VERSION "BASE;119 -- 04.07.2025 -- R3233 -- FDMgenDBC1.0"

NS_ :

BS_:

BU_: CM4

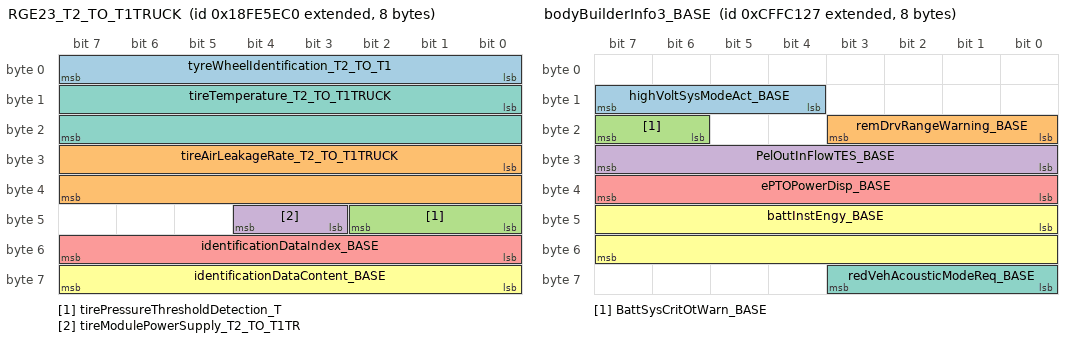
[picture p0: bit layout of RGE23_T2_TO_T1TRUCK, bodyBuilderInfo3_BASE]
BO_ 2566807232 RGE23_T2_TO_T1TRUCK: 8 Vector__XXX
 SG_ tyreWheelIdentification_T2_TO_T1 : 0|8@1+ (1,0) [0|0] "-" CM4
 SG_ tireAirLeakageRate_T2_TO_T1TRUCK : 24|16@1+ (0.1,0) [0|6425.5] "Pa/s" CM4
 SG_ tirePressureThresholdDetection_T : 40|3@1+ (1,0) [0|0] "-" CM4
 SG_ tireModulePowerSupply_T2_TO_T1TR : 43|2@1+ (1,0) [0|0] "-" CM4
 SG_ identificationDataIndex_BASE : 48|8@1+ (1,0) [0|250] "-" CM4
 SG_ identificationDataContent_BASE : 56|8@1+ (1,0) [0|250] "-" CM4
 SG_ tireTemperature_T2_TO_T1TRUCK : 8|16@1+ (0.03125,-273) [-273|1735] "°C" CM4

BO_ 2365571367 bodyBuilderInfo3_BASE: 8 Vector__XXX
 SG_ highVoltSysModeAct_BASE : 12|4@1+ (1,0) [0|0] "-" CM4
 SG_ remDrvRangeWarning_BASE : 16|4@1+ (1,0) [0|0] "-" CM4
 SG_ BattSysCritOtWarn_BASE : 22|2@1+ (1,0) [0|0] "-" CM4
 SG_ PelOutInFlowTES_BASE : 24|8@1+ (5,-625) [-625|625] "kW" CM4
 SG_ ePTOPowerDisp_BASE : 32|8@1+ (0.5,0) [0|120] "%" CM4
 SG_ battInstEngy_BASE : 40|16@1+ (0.01,-321.27) [-321.27|321.28] "kWh/km" CM4
 SG_ redVehAcousticModeReq_BASE : 56|4@1+ (1,0) [0|0] "-" CM4

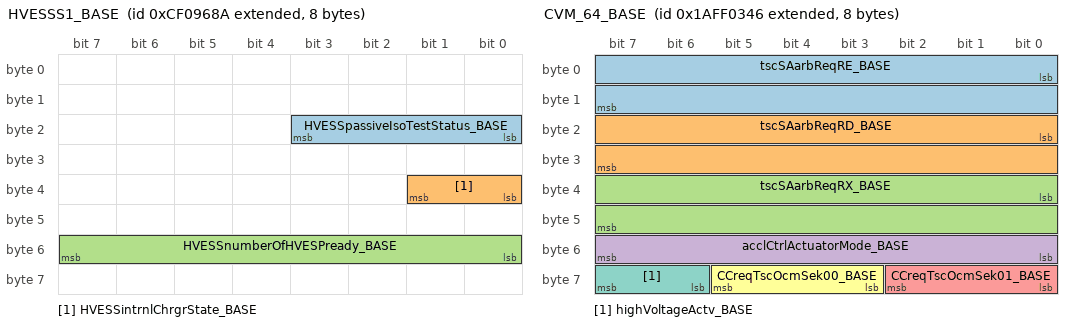
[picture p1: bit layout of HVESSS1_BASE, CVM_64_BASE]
BO_ 2364577418 HVESSS1_BASE: 8 Vector__XXX
 SG_ HVESSpassiveIsoTestStatus_BASE : 16|4@1+ (1,0) [0|0] "-" CM4
 SG_ HVESSintrnlChrgrState_BASE : 32|2@1+ (1,0) [0|0] "-" CM4
 SG_ HVESSnumberOfHVESPready_BASE : 48|8@1+ (1,0) [0|250] "count" CM4

BO_ 2600403782 CVM_64_BASE: 8 Vector__XXX
 SG_ tscSAarbReqRE_BASE : 0|16@1+ (1,0) [0|65535] "-" CM4
 SG_ tscSAarbReqRD_BASE : 16|16@1+ (1,0) [0|65535] "-" CM4
 SG_ tscSAarbReqRX_BASE : 32|16@1+ (1,0) [0|65535] "-" CM4
 SG_ acclCtrlActuatorMode_BASE : 48|8@1+ (1,0) [0|0] "-" CM4
 SG_ CCreqTscOcmSek01_BASE : 56|3@1+ (1,0) [0|0] "-" CM4
 SG_ CCreqTscOcmSek00_BASE : 59|3@1+ (1,0) [0|0] "-" CM4
 SG_ highVoltageActv_BASE : 62|2@1+ (1,0) [0|0] "-" CM4

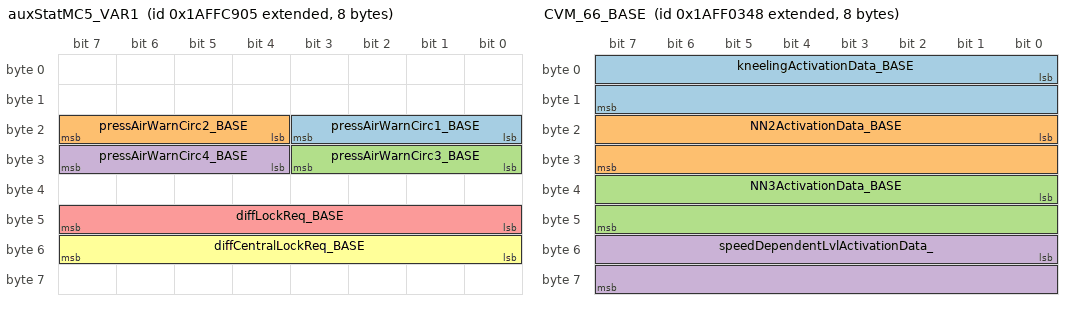
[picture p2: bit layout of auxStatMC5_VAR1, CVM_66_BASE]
BO_ 2600454405 auxStatMC5_VAR1: 8 Vector__XXX
 SG_ pressAirWarnCirc1_BASE : 16|4@1+ (1,0) [0|0] "-" CM4
 SG_ pressAirWarnCirc2_BASE : 20|4@1+ (1,0) [0|0] "-" CM4
 SG_ pressAirWarnCirc3_BASE : 24|4@1+ (1,0) [0|0] "-" CM4
 SG_ pressAirWarnCirc4_BASE : 28|4@1+ (1,0) [0|0] "-" CM4
 SG_ diffLockReq_BASE : 40|8@1+ (1,0) [0|0] "-" CM4
 SG_ diffCentralLockReq_BASE : 48|8@1+ (1,0) [0|0] "-" CM4

BO_ 2566842927 vehicleWeight_VAR2: 8 Vector__XXX
 SG_ axleLocation_VEHWE_VAR2_SSC1 : 0|8@1+ (1,0) [0|255] "-" CM4
 SG_ axleWeight_VEHWE_VAR2_SSC1 : 8|16@1+ (0.5,0) [0|32127.5] "kg" CM4

BO_ 2600403784 CVM_66_BASE: 8 Vector__XXX
 SG_ kneelingActivationData_BASE : 0|16@1+ (1,0) [0|64255] "-" CM4
 SG_ NN2ActivationData_BASE : 16|16@1+ (1,0) [0|64255] "km" CM4
 SG_ NN3ActivationData_BASE : 32|16@1+ (1,0) [0|64255] "km" CM4
 SG_ speedDependentLvlActivationData_ : 48|16@1+ (1,0) [0|64255] "km" CM4

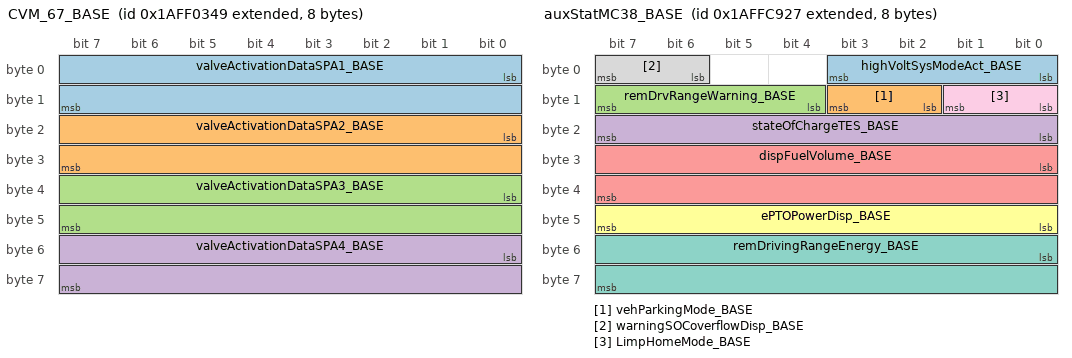
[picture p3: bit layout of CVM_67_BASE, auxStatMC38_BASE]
BO_ 2600403785 CVM_67_BASE: 8 Vector__XXX
 SG_ valveActivationDataSPA1_BASE : 0|16@1+ (1,0) [0|64255] "-" CM4
 SG_ valveActivationDataSPA2_BASE : 16|16@1+ (1,0) [0|64255] "-" CM4
 SG_ valveActivationDataSPA3_BASE : 32|16@1+ (1,0) [0|64255] "-" CM4
 SG_ valveActivationDataSPA4_BASE : 48|16@1+ (1,0) [0|64255] "-" CM4

BO_ 2566898215 bodyBuilderInfo4_BASE: 8 Vector__XXX
 SG_ pssblRngExt_ePTO_BASE : 0|16@1+ (0.5,0) [0|32127.5] "km" CM4
 SG_ currPwrCnsmptEPTO_BASE : 16|16@1+ (0.5,-250) [-250|250] "kW" CM4
 SG_ remOperatingTime_BASE : 32|16@1+ (1,0) [0|64255] "min" CM4
 SG_ sMeanPowerTES_BASE : 48|16@1+ (0.05,-1600) [-1600|1600] "kW" CM4

BO_ 2566898182 bodyBuilderInfo6_BASE: 8 Vector__XXX
 SG_ tourDataSetMux_BASE : 0|8@1+ (1,0) [0|0] "-" CM4
 SG_ energyConsumptionEPTO_BASE : 8|32@1+ (0.1,0) [0|421108121.5] "kWh" CM4

BO_ 2566848295 operatorIndicators_VAR1: 8 Vector__XXX
 SG_ waterInFuelIndicator_BASE : 0|2@1+ (1,0) [0|0] "-" CM4
 SG_ fuelSupplyEstimatedRemainingDist : 16|16@1+ (1,0) [0|64255] "km" CM4

BO_ 2600403787 CVM_69_BASE: 8 Vector__XXX
 SG_ steeringWheelAngle_BASIS : 0|16@1+ (0.0009765625,-31.374) [-31.374|31.3750234375000012221] "rad" CM4
 SG_ engineSpeed_BASIS : 16|16@1+ (0.125,0) [0|8031.875] "rpm" CM4
 SG_ transmissionInputShaftSpeed_BASI : 32|16@1+ (0.125,0) [0|8031.875] "rpm" CM4
 SG_ transmissionOutputShaftSpeed_BAS : 48|16@1+ (0.125,0) [0|8031.875] "rpm" CM4

BO_ 2600454439 auxStatMC38_BASE: 8 Vector__XXX
 SG_ highVoltSysModeAct_BASE : 0|4@1+ (1,0) [0|0] "-" CM4
 SG_ vehParkingMode_BASE : 10|2@1+ (1,0) [0|0] "-" CM4
 SG_ remDrvRangeWarning_BASE : 12|4@1+ (1,0) [0|0] "-" CM4
 SG_ stateOfChargeTES_BASE : 16|8@1+ (0.4,0) [0|100] "%" CM4
 SG_ dispFuelVolume_BASE : 24|16@1+ (0.5,0) [0|32127.5] "l" CM4
 SG_ ePTOPowerDisp_BASE : 40|8@1+ (0.5,0) [0|120] "%" CM4
 SG_ remDrivingRangeEnergy_BASE : 48|16@1+ (0.5,0) [0|32127.5] "km" CM4
 SG_ warningSOCoverflowDisp_BASE : 6|2@1+ (1,0) [0|0] "-" CM4
 SG_ LimpHomeMode_BASE : 8|2@1+ (1,0) [0|0] "-" CM4

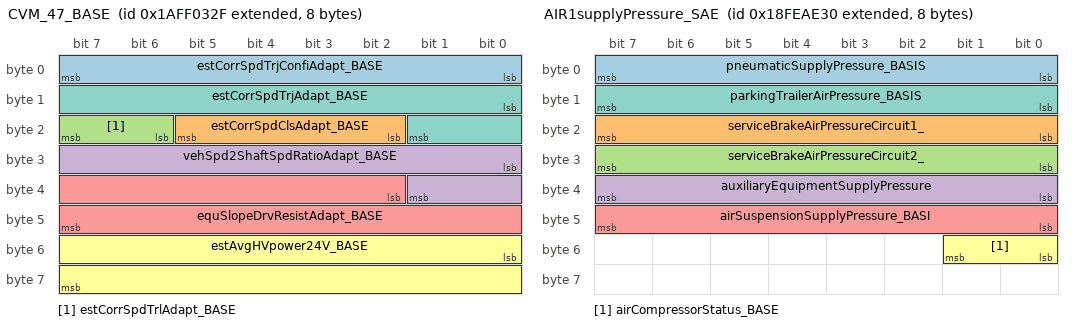
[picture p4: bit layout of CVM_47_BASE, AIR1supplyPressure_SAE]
BO_ 2600403759 CVM_47_BASE: 8 Vector__XXX
 SG_ estCorrSpdTrjConfiAdapt_BASE : 0|8@1+ (1,0) [0|100] "%" CM4
 SG_ estCorrSpdClsAdapt_BASE : 18|4@1+ (1,0) [0|0] "-" CM4
 SG_ estCorrSpdTrlAdapt_BASE : 22|2@1+ (1,0) [0|0] "-" CM4
 SG_ vehSpd2ShaftSpdRatioAdapt_BASE : 24|10@1+ (0.0009765625,0) [0|0.5] "m" CM4
 SG_ equSlopeDrvResistAdapt_BASE : 34|14@1+ (0.01,0) [0|50] "%" CM4
 SG_ estAvgHVpower24V_BASE : 48|16@1+ (0.025,-800) [-800|806.375] "kW" CM4
 SG_ estCorrSpdTrjAdapt_BASE : 8|10@1+ (0.015625,0) [0|3.984375] "-" CM4

BO_ 2566827568 AIR1supplyPressure_SAE: 8 Vector__XXX
 SG_ pneumaticSupplyPressure_BASIS : 0|8@1+ (8,0) [0|2000] "kPa" CM4
 SG_ serviceBrakeAirPressureCircuit1_ : 16|8@1+ (8,0) [0|2000] "kPa" CM4
 SG_ serviceBrakeAirPressureCircuit2_ : 24|8@1+ (8,0) [0|2000] "kPa" CM4
 SG_ auxiliaryEquipmentSupplyPressure : 32|8@1+ (8,0) [0|2000] "kPa" CM4
 SG_ airSuspensionSupplyPressure_BASI : 40|8@1+ (8,0) [0|2000] "kPa" CM4
 SG_ airCompressorStatus_BASE : 48|2@1+ (1,0) [0|0] "-" CM4
 SG_ parkingTrailerAirPressure_BASIS : 8|8@1+ (8,0) [0|2000] "kPa" CM4

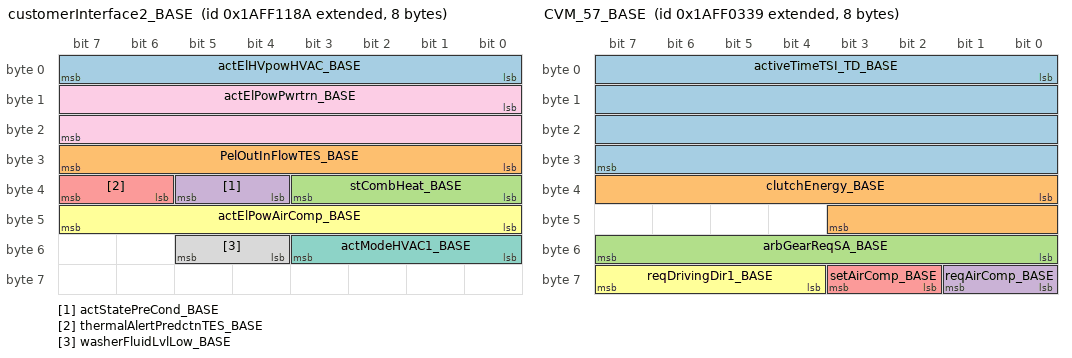
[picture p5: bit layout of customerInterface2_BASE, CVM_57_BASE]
BO_ 2600407434 customerInterface2_BASE: 8 Vector__XXX
 SG_ actElHVpowHVAC_BASE : 0|8@1+ (500,0) [0|125000] "W" CM4
 SG_ PelOutInFlowTES_BASE : 24|8@1+ (5,-625) [-625|625] "kW" CM4
 SG_ stCombHeat_BASE : 32|4@1+ (1,0) [0|0] "-" CM4
 SG_ actStatePreCond_BASE : 36|2@1+ (1,0) [0|0] "-" CM4
 SG_ thermalAlertPredctnTES_BASE : 38|2@1+ (1,0) [0|0] "-" CM4
 SG_ actElPowAirComp_BASE : 40|8@1+ (0.05,0) [0|10.8] "kW" CM4
 SG_ actModeHVAC1_BASE : 48|4@1+ (1,0) [0|0] "-" CM4
 SG_ washerFluidLvlLow_BASE : 52|2@1+ (1,0) [0|0] "-" CM4
 SG_ actElPowPwrtrn_BASE : 8|16@1+ (1,-600) [-600|600] "kW" CM4

BO_ 2566841088 engineConfiguration_BASE: 39 Vector__XXX
 SG_ engineReferenceEngineTorque_BASI : 152|16@1+ (1,0) [0|64255] "Nm" CM4
 SG_ maxMomEngOverSpeedPoint7_BASIS : 168|16@1+ (0.125,0) [0|8031.875] "rpm" CM4

BO_ 2600403768 CVM_56_BASE: 8 Vector__XXX
 SG_ fuelConsptDriveCycle_BASE : 0|32@1+ (0.001,0) [0|4200000] "l" CM4
 SG_ pitchAngleTruckAndTrailer_BASE : 32|16@1+ (0.005,0) [-150|150] "%" CM4
 SG_ Mgu3GeneratingCurrentLimit_BASE : 48|8@1+ (5,0) [0|1250] "A" CM4

BO_ 2600403769 CVM_57_BASE: 8 Vector__XXX
 SG_ activeTimeTSI_TD_BASE : 0|32@1+ (1,0) [0|4294967295] "s" CM4
 SG_ clutchEnergy_BASE : 32|12@1+ (1,0) [0|4093] "kWs" CM4
 SG_ arbGearReqSA_BASE : 48|8@1+ (1,0) [0|255] "-" CM4
 SG_ reqAirComp_BASE : 56|2@1+ (1,0) [0|0] "-" CM4
 SG_ setAirComp_BASE : 58|2@1+ (1,0) [0|0] "-" CM4
 SG_ reqDrivingDir1_BASE : 60|4@1+ (1,0) [0|0] "-" CM4

BO_ 2600403766 CVM_54_BASE: 8 Vector__XXX
 SG_ vehSpdEnhanced_BASE : 0|32@1+ (0.00390625,-250) [-250|250] "km/h" CM4
 SG_ commandTorqueCCDI_BASE : 32|16@1+ (0.1,-3200) [-3200|3225.5] "Nm" CM4
 SG_ Mgu3EstimatedShaftTorque_BASE : 48|16@1+ (0.1,-3200) [-3200|3225.5] "Nm" CM4

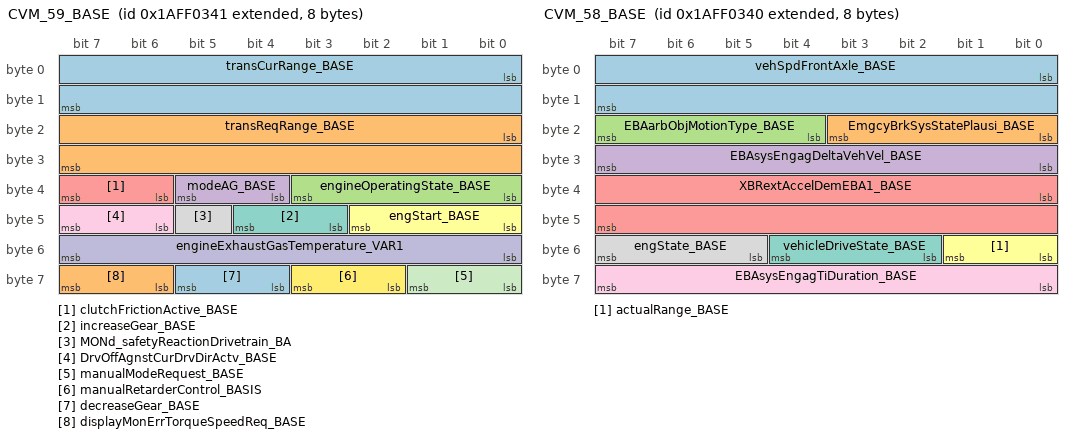
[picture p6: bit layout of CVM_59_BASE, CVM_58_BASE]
BO_ 2600403777 CVM_59_BASE: 8 Vector__XXX
 SG_ transCurRange_BASE : 0|16@1+ (1,0) [0|0] "-" CM4
 SG_ transReqRange_BASE : 16|16@1+ (1,0) [0|0] "-" CM4
 SG_ engineOperatingState_BASE : 32|4@1+ (1,0) [0|0] "-" CM4
 SG_ modeAG_BASE : 36|2@1+ (1,0) [0|0] "-" CM4
 SG_ clutchFrictionActive_BASE : 38|2@1+ (1,0) [0|0] "-" CM4
 SG_ engStart_BASE : 40|3@1+ (1,0) [0|0] "-" CM4
 SG_ increaseGear_BASE : 43|2@1+ (1,0) [0|0] "-" CM4
 SG_ MONd_safetyReactionDrivetrain_BA : 45|1@1+ (1,0) [0|0] "-" CM4
 SG_ DrvOffAgnstCurDrvDirActv_BASE : 46|2@1+ (1,0) [0|0] "-" CM4
 SG_ engineExhaustGasTemperature_VAR1 : 48|8@1+ (4,-40) [-40|960] "°C" CM4
 SG_ manualModeRequest_BASE : 56|2@1+ (1,0) [0|0] "-" CM4
 SG_ manualRetarderControl_BASIS : 58|2@1+ (1,0) [0|0] "-" CM4
 SG_ decreaseGear_BASE : 60|2@1+ (1,0) [0|0] "-" CM4
 SG_ displayMonErrTorqueSpeedReq_BASE : 62|2@1+ (1,0) [0|0] "-" CM4

BO_ 2600403776 CVM_58_BASE: 8 Vector__XXX
 SG_ vehSpdFrontAxle_BASE : 0|16@1+ (0.00390625,0) [0|250.996] "km/h" CM4
 SG_ EmgcyBrkSysStatePlausi_BASE : 16|4@1+ (1,0) [0|0] "-" CM4
 SG_ EBAarbObjMotionType_BASE : 20|4@1+ (1,0) [0|0] "-" CM4
 SG_ EBAsysEngagDeltaVehVel_BASE : 24|8@1+ (1,0) [0|255] "km/h" CM4
 SG_ XBRextAccelDemEBA1_BASE : 32|16@1+ (0.00048828125,-15.687) [-15.687|15.687] "m/s²" CM4
 SG_ actualRange_BASE : 48|2@1+ (1,0) [0|0] "-" CM4
 SG_ vehicleDriveState_BASE : 50|3@1+ (1,0) [0|0] "-" CM4
 SG_ engState_BASE : 53|3@1+ (1,0) [0|0] "-" CM4
 SG_ EBAsysEngagTiDuration_BASE : 56|8@1+ (0.1,0) [0|25.5] "s" CM4

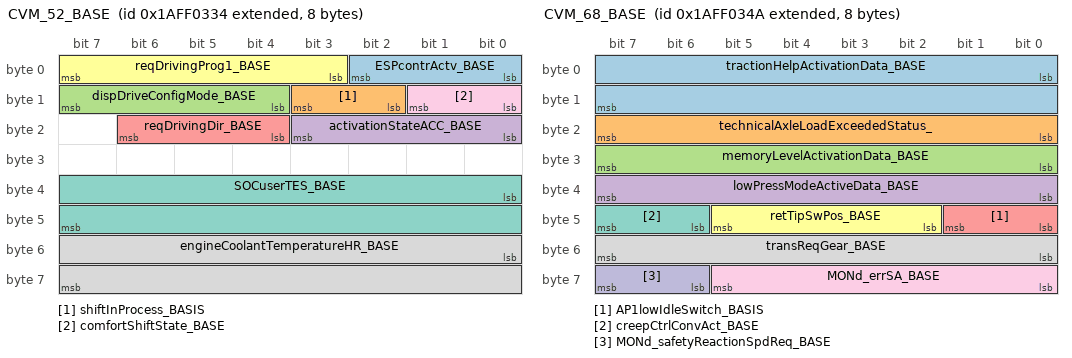
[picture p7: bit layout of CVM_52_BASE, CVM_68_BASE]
BO_ 2600403764 CVM_52_BASE: 8 Vector__XXX
 SG_ ESPcontrActv_BASE : 0|3@1+ (1,0) [0|0] "-" CM4
 SG_ shiftInProcess_BASIS : 10|2@1+ (1,0) [0|0] "-" CM4
 SG_ dispDriveConfigMode_BASE : 12|4@1+ (1,0) [0|0] "-" CM4
 SG_ activationStateACC_BASE : 16|4@1+ (1,0) [0|0] "-" CM4
 SG_ reqDrivingDir_BASE : 20|3@1+ (1,0) [0|0] "-" CM4
 SG_ reqDrivingProg1_BASE : 3|5@1+ (1,0) [0|0] "-" CM4
 SG_ SOCuserTES_BASE : 32|16@1+ (0.1,0) [0|102.1] "%" CM4
 SG_ engineCoolantTemperatureHR_BASE : 48|16@1+ (0.03125,-273) [-273|1734.96875] "°C" CM4
 SG_ comfortShiftState_BASE : 8|2@1+ (1,0) [0|0] "-" CM4

BO_ 2600403786 CVM_68_BASE: 8 Vector__XXX
 SG_ tractionHelpActivationData_BASE : 0|16@1+ (1,0) [0|64255] "km" CM4
 SG_ technicalAxleLoadExceededStatus_ : 16|8@1+ (100,0) [0|25000] "kg" CM4
 SG_ memoryLevelActivationData_BASE : 24|8@1+ (1,0) [0|250] "-" CM4
 SG_ lowPressModeActiveData_BASE : 32|8@1+ (1,0) [0|250] "-" CM4
 SG_ AP1lowIdleSwitch_BASIS : 40|2@1+ (1,0) [0|0] "-" CM4
 SG_ retTipSwPos_BASE : 42|4@1+ (1,0) [0|0] "-" CM4
 SG_ creepCtrlConvAct_BASE : 46|2@1+ (1,0) [0|0] "-" CM4
 SG_ transReqGear_BASE : 48|8@1+ (1,-125) [-125|125] "-" CM4
 SG_ MONd_errSA_BASE : 56|6@1+ (1,0) [0|0] "-" CM4
 SG_ MONd_safetyReactionSpdReq_BASE : 62|2@1+ (1,0) [0|0] "-" CM4

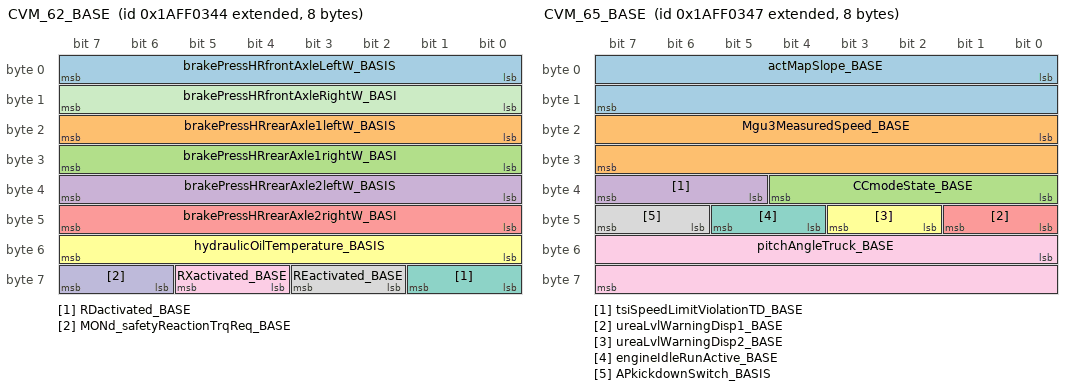
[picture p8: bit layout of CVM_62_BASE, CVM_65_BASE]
BO_ 2600403780 CVM_62_BASE: 8 Vector__XXX
 SG_ brakePressHRfrontAxleLeftW_BASIS : 0|8@1+ (0.05,0) [0|12.5] "bar" CM4
 SG_ brakePressHRrearAxle1leftW_BASIS : 16|8@1+ (0.05,0) [0|12.5] "bar" CM4
 SG_ brakePressHRrearAxle1rightW_BASI : 24|8@1+ (0.05,0) [0|12.5] "bar" CM4
 SG_ brakePressHRrearAxle2leftW_BASIS : 32|8@1+ (0.05,0) [0|12.5] "bar" CM4
 SG_ brakePressHRrearAxle2rightW_BASI : 40|8@1+ (0.05,0) [0|12.5] "bar" CM4
 SG_ hydraulicOilTemperature_BASIS : 48|8@1+ (1,-40) [-40|210] "°C" CM4
 SG_ RDactivated_BASE : 56|2@1+ (1,0) [0|0] "-" CM4
 SG_ REactivated_BASE : 58|2@1+ (1,0) [0|0] "-" CM4
 SG_ RXactivated_BASE : 60|2@1+ (1,0) [0|0] "-" CM4
 SG_ MONd_safetyReactionTrqReq_BASE : 62|2@1+ (1,0) [0|0] "-" CM4
 SG_ brakePressHRfrontAxleRightW_BASI : 8|8@1+ (0.05,0) [0|12.5] "bar" CM4

BO_ 2600403783 CVM_65_BASE: 8 Vector__XXX
 SG_ actMapSlope_BASE : 0|16@1+ (0.01,-50) [-50|50] "%" CM4
 SG_ Mgu3MeasuredSpeed_BASE : 16|16@1+ (0.5,-16000) [-16000|16127.5] "rpm" CM4
 SG_ CCmodeState_BASE : 32|5@1+ (1,0) [0|0] "-" CM4
 SG_ tsiSpeedLimitViolationTD_BASE : 37|3@1+ (1,0) [0|0] "-" CM4
 SG_ ureaLvlWarningDisp1_BASE : 40|2@1+ (1,0) [0|0] "-" CM4
 SG_ ureaLvlWarningDisp2_BASE : 42|2@1+ (1,0) [0|0] "-" CM4
 SG_ engineIdleRunActive_BASE : 44|2@1+ (1,0) [0|0] "-" CM4
 SG_ APkickdownSwitch_BASIS : 46|2@1+ (1,0) [0|0] "-" CM4
 SG_ pitchAngleTruck_BASE : 48|16@1+ (0.005,-150) [-150|150] "%" CM4

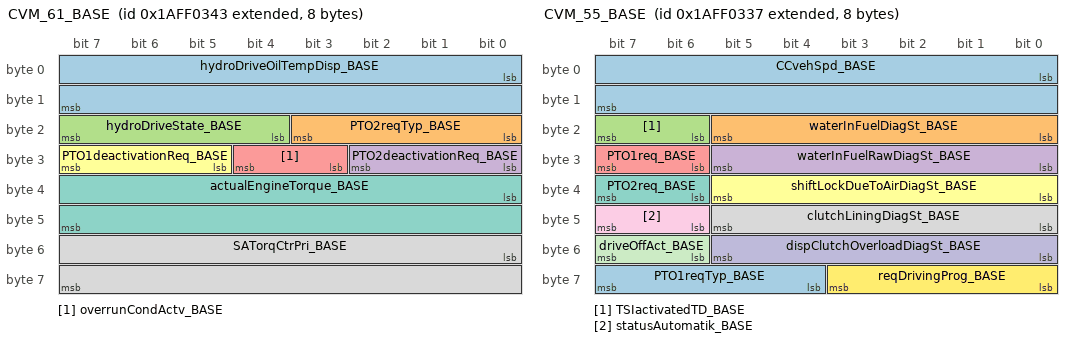
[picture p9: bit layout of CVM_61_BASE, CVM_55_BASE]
BO_ 2600403779 CVM_61_BASE: 8 Vector__XXX
 SG_ hydroDriveOilTempDisp_BASE : 0|16@1+ (0.03125,-273) [-273|1734.96875] "°C" CM4
 SG_ PTO2reqTyp_BASE : 16|4@1+ (1,0) [0|0] "-" CM4
 SG_ hydroDriveState_BASE : 20|4@1+ (1,0) [0|0] "-" CM4
 SG_ PTO2deactivationReq_BASE : 24|3@1+ (1,0) [0|0] "-" CM4
 SG_ overrunCondActv_BASE : 27|2@1+ (1,0) [0|0] "-" CM4
 SG_ PTO1deactivationReq_BASE : 29|3@1+ (1,0) [0|0] "-" CM4
 SG_ actualEngineTorque_BASE : 32|16@1+ (0.00390625,-125) [-125|125] "%" CM4
 SG_ SATorqCtrPri_BASE : 48|16@1+ (1,0) [0|65535] "-" CM4

BO_ 2600403767 CVM_55_BASE: 8 Vector__XXX
 SG_ CCvehSpd_BASE : 0|16@1+ (0.00390625,0) [0|250.996] "km/h" CM4
 SG_ waterInFuelDiagSt_BASE : 16|6@1+ (1,0) [0|0] "-" CM4
 SG_ TSIactivatedTD_BASE : 22|2@1+ (1,0) [0|0] "-" CM4
 SG_ waterInFuelRawDiagSt_BASE : 24|6@1+ (1,0) [0|0] "-" CM4
 SG_ PTO1req_BASE : 30|2@1+ (1,0) [0|0] "-" CM4
 SG_ shiftLockDueToAirDiagSt_BASE : 32|6@1+ (1,0) [0|0] "-" CM4
 SG_ PTO2req_BASE : 38|2@1+ (1,0) [0|0] "-" CM4
 SG_ clutchLiningDiagSt_BASE : 40|6@1+ (1,0) [0|0] "-" CM4
 SG_ statusAutomatik_BASE : 46|2@1+ (1,0) [0|0] "-" CM4
 SG_ dispClutchOverloadDiagSt_BASE : 48|6@1+ (1,0) [0|0] "-" CM4
 SG_ driveOffAct_BASE : 54|2@1+ (1,0) [0|0] "-" CM4
 SG_ reqDrivingProg_BASE : 56|4@1+ (1,0) [0|0] "-" CM4
 SG_ PTO1reqTyp_BASE : 60|4@1+ (1,0) [0|0] "-" CM4

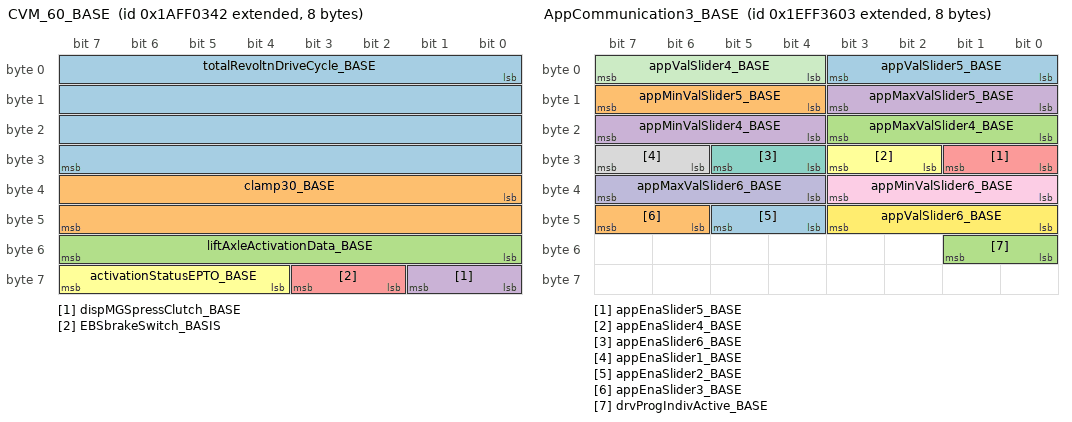
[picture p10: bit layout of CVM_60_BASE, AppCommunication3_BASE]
BO_ 2600403778 CVM_60_BASE: 8 Vector__XXX
 SG_ totalRevoltnDriveCycle_BASE : 0|32@1+ (1,0) [0|4261412864] "r" CM4
 SG_ clamp30_BASE : 32|16@1+ (0.001,0) [0|65.535] "V" CM4
 SG_ liftAxleActivationData_BASE : 48|8@1+ (1,0) [0|250] "-" CM4
 SG_ dispMGSpressClutch_BASE : 56|2@1+ (1,0) [0|0] "-" CM4
 SG_ EBSbrakeSwitch_BASIS : 58|2@1+ (1,0) [0|0] "-" CM4
 SG_ activationStatusEPTO_BASE : 60|4@1+ (1,0) [0|0] "-" CM4

BO_ 2667525635 AppCommunication3_BASE: 8 Vector__XXX
 SG_ appValSlider5_BASE : 0|4@1+ (0.1,0) [0|1] "-" CM4
 SG_ appMinValSlider5_BASE : 12|4@1+ (0.1,0) [0|1] "-" CM4
 SG_ appMaxValSlider4_BASE : 16|4@1+ (0.1,0) [0|1] "-" CM4
 SG_ appMinValSlider4_BASE : 20|4@1+ (0.1,0) [0|1] "-" CM4
 SG_ appEnaSlider5_BASE : 24|2@1+ (1,0) [0|0] "-" CM4
 SG_ appEnaSlider4_BASE : 26|2@1+ (1,0) [0|0] "-" CM4
 SG_ appEnaSlider6_BASE : 28|2@1+ (1,0) [0|0] "-" CM4
 SG_ appEnaSlider1_BASE : 30|2@1+ (1,0) [0|0] "-" CM4
 SG_ appMinValSlider6_BASE : 32|4@1+ (0.1,0) [0|1] "-" CM4
 SG_ appMaxValSlider6_BASE : 36|4@1+ (0.1,0) [0|1] "-" CM4
 SG_ appValSlider4_BASE : 4|4@1+ (0.1,0) [0|1] "-" CM4
 SG_ appValSlider6_BASE : 40|4@1+ (0.1,0) [0|1] "-" CM4
 SG_ appEnaSlider2_BASE : 44|2@1+ (1,0) [0|0] "-" CM4
 SG_ appEnaSlider3_BASE : 46|2@1+ (1,0) [0|0] "-" CM4
 SG_ drvProgIndivActive_BASE : 48|2@1+ (1,0) [0|0] "-" CM4
 SG_ appMaxValSlider5_BASE : 8|4@1+ (0.1,0) [0|1] "-" CM4

BO_ 2600403760 CVM_48_BASE: 8 Vector__XXX
 SG_ hyrdgnMaxTankTemperature_BASE : 0|8@1+ (1,-50) [-50|200] "°C" CM4
 SG_ hyrdgnTemperatureHighSide_BASE : 16|8@1+ (1,-50) [-50|200] "°C" CM4
 SG_ hyrdgnMinTankTemperature_BASE : 8|8@1+ (1,-50) [-50|200] "°C" CM4

BO_ 2566080807 FCCI_BASE: 8 Vector__XXX
 SG_ FCCI_placeholder_BASE : 0|8@1+ (1,0) [0|255] "-" CM4

BO_ 2566675782 HVESSCFG_BASE: 20 Vector__XXX
 SG_ HVESSnumberOfHVESPconfig_BASE : 128|8@1+ (1,0) [0|250] "count" CM4

BO_ 2566678922 EVOI1_BASE: 8 Vector__XXX
 SG_ HVESSestRemDist_BASE : 0|16@1+ (0.25,0) [0|16063.75] "km" CM4

BO_ 2566827815 GFC_BASE: 8 Vector__XXX
 SG_ tripFuelGas_BASE : 0|32@1+ (0.5,0) [0|2105540607.5] "kg" CM4
 SG_ totalFuelUsedGas_BASE : 32|32@1+ (0.5,0) [0|2105540607.5] "kg" CM4

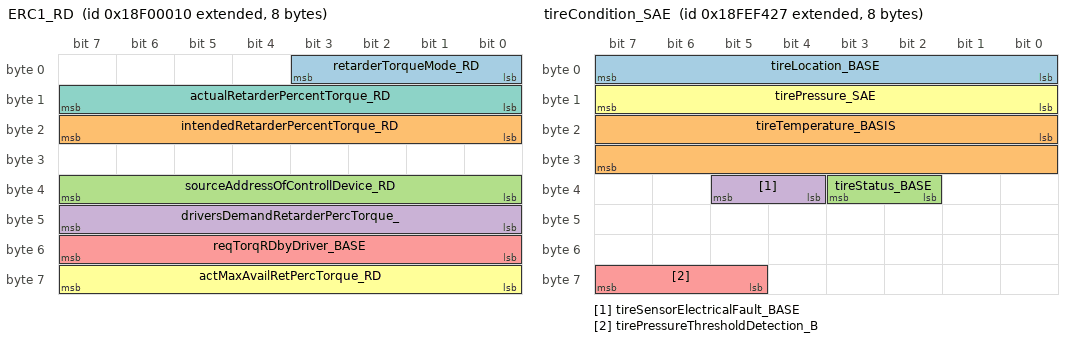
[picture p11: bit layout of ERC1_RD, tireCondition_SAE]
BO_ 2565865488 ERC1_RD: 8 Vector__XXX
 SG_ retarderTorqueMode_RD : 0|4@1+ (1,0) [0|0] "-" CM4
 SG_ intendedRetarderPercentTorque_RD : 16|8@1+ (1,-125) [-125|125] "%" CM4
 SG_ sourceAddressOfControllDevice_RD : 32|8@1+ (1,0) [0|255] "-" CM4
 SG_ driversDemandRetarderPercTorque_ : 40|8@1+ (1,-125) [-125|125] "%" CM4
 SG_ reqTorqRDbyDriver_BASE : 48|8@1+ (0.4,0) [0|100] "%" CM4
 SG_ actMaxAvailRetPercTorque_RD : 56|8@1+ (1,-125) [-125|125] "%" CM4
 SG_ actualRetarderPercentTorque_RD : 8|8@1+ (1,-125) [-125|125] "%" CM4

BO_ 2566845479 tireCondition_SAE: 8 Vector__XXX
 SG_ tireLocation_BASE : 0|8@1+ (1,0) [0|0] "-" CM4
 SG_ tireTemperature_BASIS : 16|16@1+ (0.03125,-273) [-273|1735] "°C" CM4
 SG_ tireStatus_BASE : 34|2@1+ (1,0) [0|0] "-" CM4
 SG_ tireSensorElectricalFault_BASE : 36|2@1+ (1,0) [0|0] "-" CM4
 SG_ tirePressureThresholdDetection_B : 61|3@1+ (1,0) [0|0] "-" CM4
 SG_ tirePressure_SAE : 8|8@1+ (4,0) [0|1000] "kPa" CM4

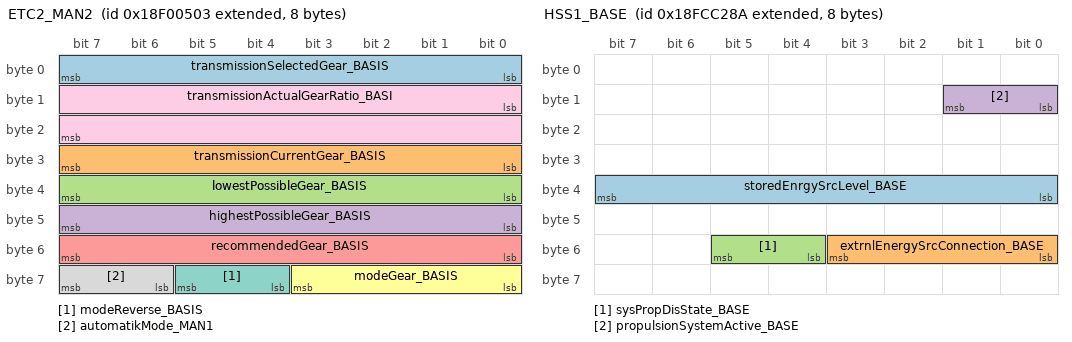
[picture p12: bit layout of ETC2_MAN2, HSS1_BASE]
BO_ 2565866755 ETC2_MAN2: 8 Vector__XXX
 SG_ transmissionSelectedGear_BASIS : 0|8@1+ (1,-125) [-125|125] "gear value" CM4
 SG_ transmissionCurrentGear_BASIS : 24|8@1+ (1,-125) [-125|128] "gear value" CM4
 SG_ lowestPossibleGear_BASIS : 32|8@1+ (1,-125) [-125|125] "gear value" CM4
 SG_ highestPossibleGear_BASIS : 40|8@1+ (1,-125) [-125|125] "gear value" CM4
 SG_ recommendedGear_BASIS : 48|8@1+ (1,-125) [-125|125] "gear value" CM4
 SG_ modeGear_BASIS : 56|4@1+ (1,0) [0|0] "-" CM4
 SG_ modeReverse_BASIS : 60|2@1+ (1,0) [0|0] "-" CM4
 SG_ automatikMode_MAN1 : 62|2@1+ (1,0) [0|0] "-" CM4
 SG_ transmissionActualGearRatio_BASI : 8|16@1+ (0.001,0) [0|64.255] "-" CM4

BO_ 2566774823 AMB2_BASE: 8 Vector__XXX
 SG_ AMB2_placeholder_BASE : 0|8@1+ (1,0) [0|255] "-" CM4

BO_ 2566687271 FCCP2S_BASE: 8 Vector__XXX
 SG_ FCCP2S_placeholder_BASE : 0|8@1+ (1,0) [0|255] "-" CM4

BO_ 2566575143 EVSEACS2_BASE: 8 Vector__XXX
 SG_ EVSEACS2_placeholder_BASE : 0|8@1+ (1,0) [0|255] "-" CM4

BO_ 2566686247 FCHTR_BASE: 8 Vector__XXX
 SG_ FCHTR_placeholder_BASE : 0|8@1+ (1,0) [0|255] "-" CM4

BO_ 2565902887 HVESSD3_BASE: 8 Vector__XXX
 SG_ highestCellTempHVESS_BASE : 0|16@1+ (0.03125,-273) [-273|1734.96875] "°C" CM4
 SG_ lowestCellTempHVESS_BASE : 16|16@1+ (0.03125,-273) [-273|1734.96875] "°C" CM4
 SG_ avrgCellTempHVESS_BASE : 32|16@1+ (0.03125,-273) [-273|1734.96875] "°C" CM4

BO_ 2566775079 CCSI1_BASE: 8 Vector__XXX
 SG_ AirConditionerCompressorStatus_B : 8|2@1+ (1,0) [0|0] "-" CM4

BO_ 2566676038 HVESSHIST_BASE: 19 Vector__XXX
 SG_ HVESSstateOfHealth_BASE : 0|8@1+ (0.4,0) [0|100] "%" CM4
 SG_ HVESSTotalLifetimeEnrgOut_BASE : 120|32@1+ (1,0) [0|4211081215] "kWh" CM4
 SG_ HVESSTotalLifetimeEnrgInp_BASE : 88|32@1+ (1,0) [0|4211081215] "kWh" CM4

BO_ 2566701706 HSS1_BASE: 8 Vector__XXX
 SG_ storedEnrgySrcLevel_BASE : 32|8@1+ (0.4,0) [0|100] "%" CM4
 SG_ extrnlEnergySrcConnection_BASE : 48|4@1+ (1,0) [0|0] "-" CM4
 SG_ sysPropDisState_BASE : 52|2@1+ (1,0) [0|0] "-" CM4
 SG_ propulsionSystemActive_BASE : 8|2@1+ (1,0) [0|0] "-" CM4

BO_ 2600403798 CVM_80_BASE: 8 Vector__XXX
 SG_ CVM80placeholder_BASE : 0|8@1+ (1,0) [0|255] "-" CM4

BO_ 2600403790 CVM_72_BASE: 8 Vector__XXX
 SG_ CVM72placeholder_BASE : 0|8@1+ (1,0) [0|255] "-" CM4

BO_ 2600403794 CVM_76_BASE: 8 Vector__XXX
 SG_ CVM76placeholder_BASE : 0|8@1+ (1,0) [0|255] "-" CM4

BO_ 2600403795 CVM_77_BASE: 8 Vector__XXX
 SG_ CVM77placeholder_BASE : 0|8@1+ (1,0) [0|255] "-" CM4

BO_ 2600403797 CVM_79_BASE: 8 Vector__XXX
 SG_ CVM79placeholder_BASE : 0|8@1+ (1,0) [0|255] "-" CM4

BO_ 2600403796 CVM_78_BASE: 8 Vector__XXX
 SG_ CVM78placeholder_BASE : 0|8@1+ (1,0) [0|255] "-" CM4

BO_ 2600403789 CVM_71_BASE: 8 Vector__XXX
 SG_ CVM71placeholder_BASE : 0|8@1+ (1,0) [0|255] "-" CM4

BO_ 2600403792 CVM_74_BASE: 8 Vector__XXX
 SG_ CVM74placeholder_BASE : 0|8@1+ (1,0) [0|255] "-" CM4

BO_ 2600403793 CVM_75_BASE: 8 Vector__XXX
 SG_ CVM75placeholder_BASE : 0|8@1+ (1,0) [0|255] "-" CM4

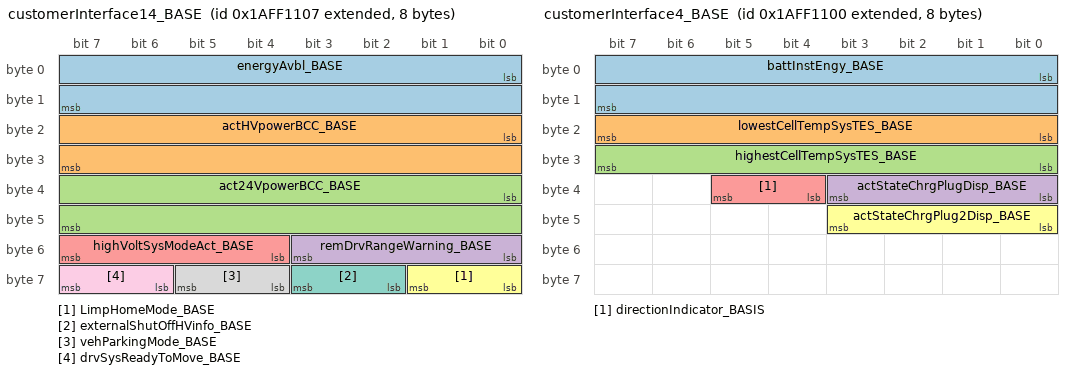
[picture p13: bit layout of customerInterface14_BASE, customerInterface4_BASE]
BO_ 2600407303 customerInterface14_BASE: 8 Vector__XXX
 SG_ energyAvbl_BASE : 0|16@1+ (0.01,0) [0|600] "kWh" CM4
 SG_ actHVpowerBCC_BASE : 16|16@1+ (0.0125,0) [0|100] "kW" CM4
 SG_ act24VpowerBCC_BASE : 32|16@1+ (0.0025,0) [0|13] "kW" CM4
 SG_ remDrvRangeWarning_BASE : 48|4@1+ (1,0) [0|0] "-" CM4
 SG_ highVoltSysModeAct_BASE : 52|4@1+ (1,0) [0|0] "-" CM4
 SG_ LimpHomeMode_BASE : 56|2@1+ (1,0) [0|0] "-" CM4
 SG_ externalShutOffHVinfo_BASE : 58|2@1+ (1,0) [0|0] "-" CM4
 SG_ vehParkingMode_BASE : 60|2@1+ (1,0) [0|0] "-" CM4
 SG_ drvSysReadyToMove_BASE : 62|2@1+ (1,0) [0|0] "-" CM4

BO_ 2566811687 combinationVehicleWeight_VAR2A: 8 Vector__XXX
 SG_ poweredVehicleWeight_VAR2_MC : 0|16@1+ (10,0) [0|642550] "kg" CM4
 SG_ grossCombinationVehicleWeight_VA : 16|16@1+ (10,0) [0|642550] "kg" CM4
 SG_ numberOfMassEstimations_BASIS : 56|8@1+ (1,0) [0|250] "-" CM4

BO_ 2600407296 customerInterface4_BASE: 8 Vector__XXX
 SG_ battInstEngy_BASE : 0|16@1+ (0.01,-321.27) [-321.27|321.28] "kWh/km" CM4
 SG_ lowestCellTempSysTES_BASE : 16|8@1+ (1,-40) [-40|210] "°C" CM4
 SG_ highestCellTempSysTES_BASE : 24|8@1+ (1,-40) [-40|210] "°C" CM4
 SG_ actStateChrgPlugDisp_BASE : 32|4@1+ (1,0) [0|0] "-" CM4
 SG_ directionIndicator_BASIS : 36|2@1+ (1,0) [0|0] "-" CM4
 SG_ actStateChrgPlug2Disp_BASE : 40|4@1+ (1,0) [0|0] "-" CM4

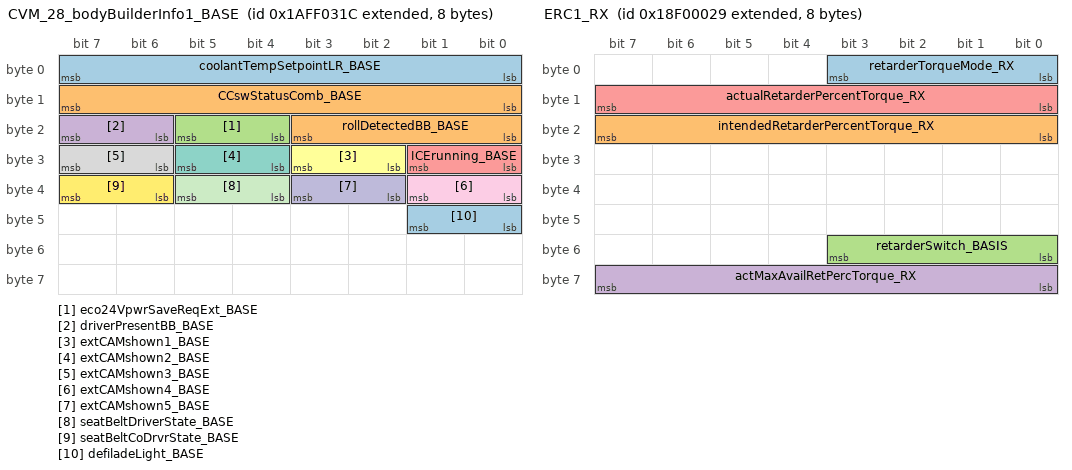
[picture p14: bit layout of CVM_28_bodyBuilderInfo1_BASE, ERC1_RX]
BO_ 2600403740 CVM_28_bodyBuilderInfo1_BASE: 8 Vector__XXX
 SG_ coolantTempSetpointLR_BASE : 0|8@1+ (1,-40) [-40|210] "°C" CM4
 SG_ rollDetectedBB_BASE : 16|4@1+ (1,0) [0|0] "-" CM4
 SG_ eco24VpwrSaveReqExt_BASE : 20|2@1+ (1,0) [0|0] "-" CM4
 SG_ driverPresentBB_BASE : 22|2@1+ (1,0) [0|0] "-" CM4
 SG_ ICErunning_BASE : 24|2@1+ (1,0) [0|0] "-" CM4
 SG_ extCAMshown1_BASE : 26|2@1+ (1,0) [0|0] "-" CM4
 SG_ extCAMshown2_BASE : 28|2@1+ (1,0) [0|0] "-" CM4
 SG_ extCAMshown3_BASE : 30|2@1+ (1,0) [0|0] "-" CM4
 SG_ extCAMshown4_BASE : 32|2@1+ (1,0) [0|0] "-" CM4
 SG_ extCAMshown5_BASE : 34|2@1+ (1,0) [0|0] "-" CM4
 SG_ seatBeltDriverState_BASE : 36|2@1+ (1,0) [0|0] "-" CM4
 SG_ seatBeltCoDrvrState_BASE : 38|2@1+ (1,0) [0|0] "-" CM4
 SG_ defiladeLight_BASE : 40|2@1+ (1,0) [0|0] "-" CM4
 SG_ CCswStatusComb_BASE : 8|8@1+ (1,0) [0|0] "-" CM4

BO_ 2566847015 B1_BASE: 8 Vector__XXX
 SG_ brakeApplicationPressure_BASE : 0|8@1+ (4,0) [0|1000] "kPa" CM4

BO_ 2566660647 EEC19_BASE: 8 Vector__XXX
 SG_ totalEngineEnergy_BASE : 0|32@1+ (1,0) [0|4211081215] "kWh" CM4

BO_ 2566840064 EEC3_BASIS: 8 Vector__XXX
 SG_ nominalFrictionPercentTorque_BAS : 0|8@1+ (1,-125) [-125|125] "%" CM4
 SG_ estimatedEngineParasiticLossesPe : 32|8@1+ (1,-125) [-125|125] "%" CM4

BO_ 2565865513 ERC1_RX: 8 Vector__XXX
 SG_ retarderTorqueMode_RX : 0|4@1+ (1,0) [0|0] "-" CM4
 SG_ intendedRetarderPercentTorque_RX : 16|8@1+ (1,-125) [-125|125] "%" CM4
 SG_ retarderSwitch_BASIS : 48|4@1+ (1,0) [0|0] "-" CM4
 SG_ actMaxAvailRetPercTorque_RX : 56|8@1+ (1,-125) [-125|125] "%" CM4
 SG_ actualRetarderPercentTorque_RX : 8|8@1+ (1,-125) [-125|125] "%" CM4

BO_ 2551906343 HVESSC1_BASE: 8 Vector__XXX
 SG_ HVESSC1_placeholder_BASE : 0|8@1+ (1,0) [0|255] "-" CM4

BO_ 2565902631 HVESSD2_BASE: 8 Vector__XXX
 SG_ HVESSD2_placeholder_BASE : 0|8@1+ (1,0) [0|255] "-" CM4

BO_ 2566687015 FCCP1S_BASE: 8 Vector__XXX
 SG_ FCCP1S_placeholder_BASE : 8|8@1+ (1,0) [0|255] "-" CM4

BO_ 2566570030 MG4LD_BASE: 16 Vector__XXX
 SG_ MG4LD_placeholder_BASE : 0|8@1+ (1,0) [0|255] "-" CM4

BO_ 2566569774 MG3LD_BASE: 16 Vector__XXX
 SG_ MG3LD_placeholder_BASE : 0|8@1+ (1,0) [0|255] "-" CM4

BO_ 2566569518 MG2LD_BASE: 16 Vector__XXX
 SG_ totalEnergyConsmpDS2_BASE : 0|32@1+ (100,0) [0|421108121500] "Wh" CM4
 SG_ totalEnergyGenDS2_BASE : 32|32@1+ (100,0) [0|421108121500] "Wh" CM4

BO_ 2566685991 FCHTRC_BASE: 8 Vector__XXX
 SG_ FCHTRC_placeholder_BASE : 0|8@1+ (1,0) [0|255] "-" CM4

BO_ 2364575882 HVESSD1_BASE: 8 Vector__XXX
 SG_ HVESSavbDisChargePower_BASE : 0|16@1+ (0.05,0) [0|3212.75] "kW" CM4
 SG_ HVESSavbChargePower_BASE : 16|16@1+ (0.05,0) [0|3212.75] "kW" CM4
 SG_ HVESSvoltageLevel_BASE : 32|16@1+ (0.05,0) [0|3212.75] "V" CM4
 SG_ HVESScurrent_BASE : 48|16@1+ (0.05,-1600) [-1600|1612.75] "A" CM4

BO_ 2566567975 EVSEDCS1_BASE: 8 Vector__XXX
 SG_ EVSE_DC_Charging_State_BASE : 0|4@1+ (1,0) [0|0] "-" CM4

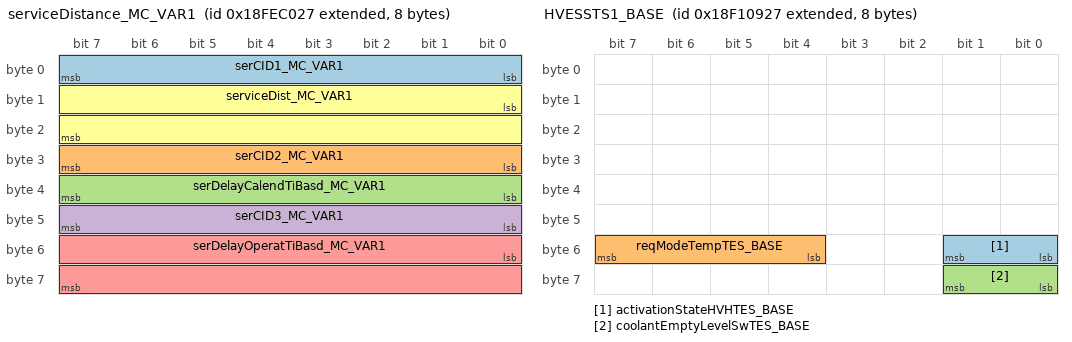
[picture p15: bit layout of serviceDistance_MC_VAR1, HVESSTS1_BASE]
BO_ 2566832167 serviceDistance_MC_VAR1: 8 Vector__XXX
 SG_ serCID1_MC_VAR1 : 0|8@1+ (1,0) [0|0] "-" CM4
 SG_ serCID2_MC_VAR1 : 24|8@1+ (1,0) [0|0] "-" CM4
 SG_ serDelayCalendTiBasd_MC_VAR1 : 32|8@1+ (1,-125) [-125|125] "week" CM4
 SG_ serCID3_MC_VAR1 : 40|8@1+ (1,0) [0|0] "-" CM4
 SG_ serDelayOperatTiBasd_MC_VAR1 : 48|16@1+ (1,-32127) [-32127|32128] "h" CM4
 SG_ serviceDist_MC_VAR1 : 8|16@1+ (5,-160635) [-160635|160640] "km" CM4

BO_ 2566819879 ETH_BASE: 33 Vector__XXX
 SG_ ETH_placeholder_BASE : 8|8@1+ (1,0) [0|255] "-" CM4

BO_ 2566569262 MG1LD_BASE: 16 Vector__XXX
 SG_ totalEnergyConsmpDS1_BASE : 0|32@1+ (100,0) [0|421108121500] "Wh" CM4
 SG_ totalEnergyGenDS1_BASE : 32|32@1+ (100,0) [0|421108121500] "Wh" CM4

BO_ 2600403765 CVM_53_BASE: 8 Vector__XXX
 SG_ HRengineTotalFuelUsed_BASE : 0|32@1+ (0.001,0) [0|4211081.2149999998509883881] "l" CM4
 SG_ calcClutchTorq_BASE : 32|32@1+ (1,-1000000) [-1000000|1000000] "Nm" CM4

BO_ 2565933607 HVESSD8_BASE: 8 Vector__XXX
 SG_ HVESSD8_placeholder_BASE : 0|8@1+ (1,0) [0|255] "-" CM4

BO_ 2565933863 HVESSD9_BASE: 8 Vector__XXX
 SG_ HVESSD9_placeholder_BASE : 8|8@1+ (1,0) [0|255] "-" CM4

BO_ 2566810919 HTR_BASE: 8 Vector__XXX
 SG_ HTR_placeholder_BASE : 0|8@1+ (1,0) [0|255] "-" CM4

BO_ 2565903143 HVESSD4_BASE: 8 Vector__XXX
 SG_ HVESSchargeCapacity_BASE : 16|16@1+ (0.01,0) [0|642.55] "Ah" CM4

BO_ 2566688551 alternateFuel3_VAR1: 8 Vector__XXX
 SG_ gasFuelSupplyPress1extRange_BASE : 0|16@1+ (0.00390625,0) [0|250.99609375] "MPa" CM4

BO_ 2565933351 HVESSTS1_BASE: 8 Vector__XXX
 SG_ activationStateHVHTES_BASE : 48|2@1+ (1,0) [0|0] "-" CM4
 SG_ reqModeTempTES_BASE : 52|4@1+ (1,0) [0|0] "-" CM4
 SG_ coolantEmptyLevelSwTES_BASE : 56|2@1+ (1,0) [0|0] "-" CM4

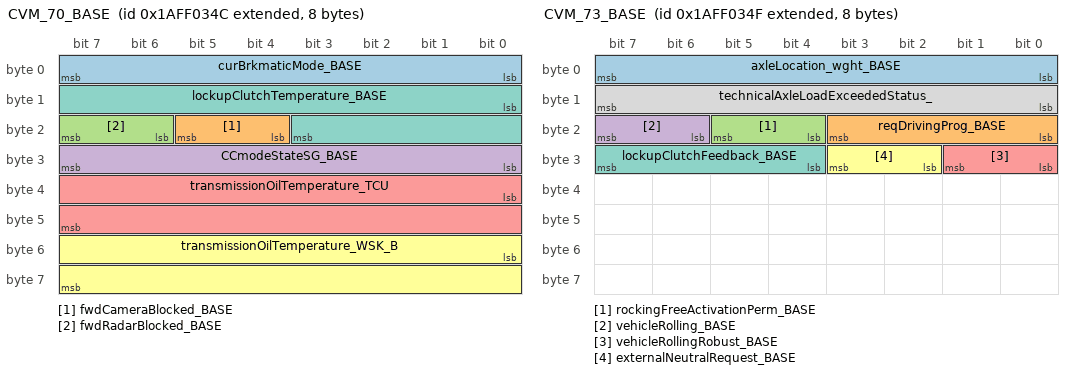
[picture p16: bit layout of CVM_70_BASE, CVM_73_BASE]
BO_ 2600403788 CVM_70_BASE: 8 Vector__XXX
 SG_ curBrkmaticMode_BASE : 0|8@1+ (1,0) [0|0] "-" CM4
 SG_ fwdCameraBlocked_BASE : 20|2@1+ (1,0) [0|0] "-" CM4
 SG_ fwdRadarBlocked_BASE : 22|2@1+ (1,0) [0|0] "-" CM4
 SG_ CCmodeStateSG_BASE : 24|8@1+ (1,0) [0|0] "-" CM4
 SG_ transmissionOilTemperature_TCU : 32|16@1+ (0.03125,-273) [-273|1735] "°C" CM4
 SG_ transmissionOilTemperature_WSK_B : 48|16@1+ (0.03125,-273) [-273|1734.96875] "°C" CM4
 SG_ lockupClutchTemperature_BASE : 8|12@1+ (1,-100) [-100|3915] "°C" CM4

BO_ 2600403791 CVM_73_BASE: 8 Vector__XXX
 SG_ axleLocation_wght_BASE : 0|8@1+ (1,0) [0|255] "-" CM4
 SG_ reqDrivingProg_BASE : 16|4@1+ (1,0) [0|0] "-" CM4
 SG_ rockingFreeActivationPerm_BASE : 20|2@1+ (1,0) [0|0] "-" CM4
 SG_ vehicleRolling_BASE : 22|2@1+ (1,0) [0|0] "-" CM4
 SG_ vehicleRollingRobust_BASE : 24|2@1+ (1,0) [0|0] "-" CM4
 SG_ externalNeutralRequest_BASE : 26|2@1+ (1,0) [0|0] "-" CM4
 SG_ lockupClutchFeedback_BASE : 28|4@1+ (1,0) [0|0] "-" CM4
 SG_ technicalAxleLoadExceededStatus_ : 8|8@1+ (100,0) [0|25000] "kg" CM4

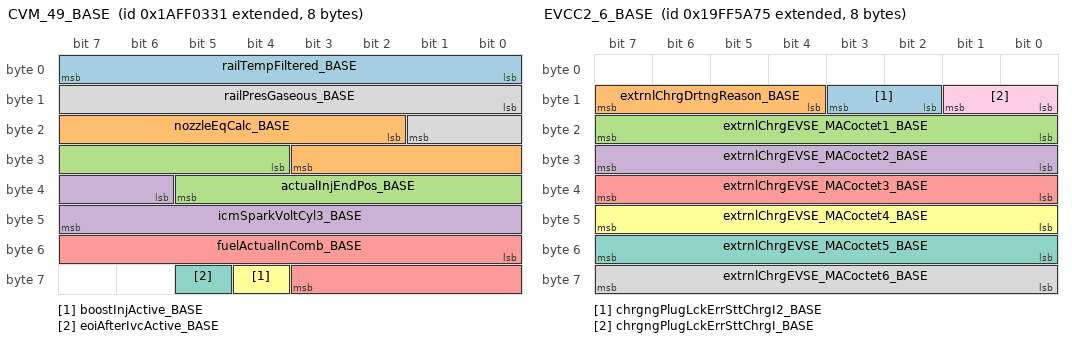
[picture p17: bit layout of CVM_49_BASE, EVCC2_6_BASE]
BO_ 2600403761 CVM_49_BASE: 8 Vector__XXX
 SG_ railTempFiltered_BASE : 0|8@1+ (0.5,0) [0|120] "°C" CM4
 SG_ nozzleEqCalc_BASE : 18|10@1+ (0.01,0) [0|10] "ms" CM4
 SG_ actualInjEndPos_BASE : 28|10@1+ (1,0) [0|650] "-" CM4
 SG_ icmSparkVoltCyl3_BASE : 38|10@1+ (0.1,0) [0|35] "-" CM4
 SG_ fuelActualInComb_BASE : 48|12@1+ (0.1,0) [0|110] "-" CM4
 SG_ boostInjActive_BASE : 60|1@1+ (1,0) [0|0] "-" CM4
 SG_ eoiAfterIvcActive_BASE : 61|1@1+ (1,0) [0|0] "-" CM4
 SG_ railPresGaseous_BASE : 8|10@1+ (0.05,0) [0|50] "bar" CM4

BO_ 2566843182 CI_BASE: 100 Vector__XXX
 SG_ CI_placeholder_BASE : 0|8@1+ (1,0) [0|255] "-" CM4

BO_ 2583648885 EVCC2_6_BASE: 8 Vector__XXX
 SG_ chrgngPlugLckErrSttChrgI2_BASE : 10|2@1+ (1,0) [0|0] "-" CM4
 SG_ extrnlChrgDrtngReason_BASE : 12|4@1+ (1,0) [0|0] "-" CM4
 SG_ extrnlChrgEVSE_MACoctet1_BASE : 16|8@1+ (1,0) [0|255] "count" CM4
 SG_ extrnlChrgEVSE_MACoctet2_BASE : 24|8@1+ (1,0) [0|255] "count" CM4
 SG_ extrnlChrgEVSE_MACoctet3_BASE : 32|8@1+ (1,0) [0|255] "count" CM4
 SG_ extrnlChrgEVSE_MACoctet4_BASE : 40|8@1+ (1,0) [0|255] "count" CM4
 SG_ extrnlChrgEVSE_MACoctet5_BASE : 48|8@1+ (1,0) [0|255] "count" CM4
 SG_ extrnlChrgEVSE_MACoctet6_BASE : 56|8@1+ (1,0) [0|255] "count" CM4
 SG_ chrgngPlugLckErrSttChrgI_BASE : 8|2@1+ (1,0) [0|0] "-" CM4

BO_ 2600454433 auxStatMC21_VAR1: 8 Vector__XXX
 SG_ reqDispLKAdeact_BASE : 0|2@1+ (1,0) [0|0] "-" CM4
 SG_ reqDispMenuLKA_BASE : 10|2@1+ (1,0) [0|0] "-" CM4
 SG_ reqDispTJAdeactAuto_BASE : 12|2@1+ (1,0) [0|0] "-" CM4
 SG_ reqDispTJAdeactMan_BASE : 14|2@1+ (1,0) [0|0] "-" CM4
 SG_ TJAselected_BASE : 16|2@1+ (1,0) [0|0] "-" CM4
 SG_ reqDispVirtualConvoy_BASE : 18|2@1+ (1,0) [0|0] "-" CM4
 SG_ reqDispTJAdeactAutoNS_BASE : 2|2@1+ (1,0) [0|0] "-" CM4
 SG_ reqDispTCWblock_BASE : 20|2@1+ (1,0) [0|0] "-" CM4
 SG_ reqDispTCWcalib_BASE : 22|2@1+ (1,0) [0|0] "-" CM4
 SG_ reqDispTCWLCWlftBlock_BASE : 24|2@1+ (1,0) [0|0] "-" CM4
 SG_ reqDispTCWLCWlftCalib_BASE : 26|2@1+ (1,0) [0|0] "-" CM4
 SG_ reqDispTCWLCWlftPermFlt_BASE : 28|2@1+ (1,0) [0|0] "-" CM4
 SG_ reqDispTCWLCWlftTemp_BASE : 30|2@1+ (1,0) [0|0] "-" CM4
 SG_ reqDispTCWLCWrghBlock_BASE : 32|2@1+ (1,0) [0|0] "-" CM4
 SG_ reqDispTCWLCWrghCalib_BASE : 34|2@1+ (1,0) [0|0] "-" CM4
 SG_ reqDispTCWLCWrghPermFlt_BASE : 36|2@1+ (1,0) [0|0] "-" CM4
 SG_ reqDispTCWLCWrghTemp_BASE : 38|2@1+ (1,0) [0|0] "-" CM4
 SG_ reqDispLKAlatArrows_BASE : 4|2@1+ (1,0) [0|0] "-" CM4
 SG_ reqDispTCWlht_BASE : 40|2@1+ (1,0) [0|0] "-" CM4
 SG_ reqDispTCWpermFlt_BASE : 42|2@1+ (1,0) [0|0] "-" CM4
 SG_ reqDispTCWrht_BASE : 44|2@1+ (1,0) [0|0] "-" CM4
 SG_ reqDispTCWtemp_BASE : 46|2@1+ (1,0) [0|0] "-" CM4
 SG_ ecoWarningDoor_BASE : 48|2@1+ (1,0) [0|0] "-" CM4
 SG_ ecoWarningWndw_BASE : 50|2@1+ (1,0) [0|0] "-" CM4
 SG_ errPrkHeatingOff_BASE : 52|2@1+ (1,0) [0|0] "-" CM4
 SG_ wrnProgADRCluster_BASE : 54|2@1+ (1,0) [0|0] "-" CM4
 SG_ dispBattMainSwOffReqPrvnt_BASE : 56|2@1+ (1,0) [0|0] "-" CM4
 SG_ dispActEmergencySwitch_BASE : 58|2@1+ (1,0) [0|0] "-" CM4
 SG_ reqDispLKAmodeActive_BASE : 6|2@1+ (1,0) [0|0] "-" CM4
 SG_ stopStartDeselected_BASE : 60|2@1+ (1,0) [0|0] "-" CM4
 SG_ bckgrndLghtDefLiMd_BASE : 62|2@1+ (1,0) [0|0] "-" CM4
 SG_ reqDispLKAmodeStandby_BASE : 8|2@1+ (1,0) [0|0] "-" CM4

BO_ 2600454425 auxStatMC24_VAR1: 8 Vector__XXX
 SG_ couplingLockState_BASE : 0|8@1+ (1,0) [0|0] "-" CM4
 SG_ interlockServiceDue_BASE : 12|2@1+ (1,0) [0|0] "-" CM4
 SG_ tempLockout_BASE : 14|2@1+ (1,0) [0|0] "-" CM4
 SG_ permaLockout_BASE : 16|2@1+ (1,0) [0|0] "-" CM4
 SG_ ttAirSuspDeactivation_BASE : 18|2@1+ (1,0) [0|0] "-" CM4
 SG_ dispWrnElHySteer_BASE : 20|4@1+ (1,0) [0|0] "-" CM4
 SG_ DIGenableDistWrn_BASE : 24|2@1+ (1,0) [0|0] "-" CM4
 SG_ VASCsafeStateActive_BASE : 26|2@1+ (1,0) [0|0] "-" CM4
 SG_ reqCSSerrLmp_BASE : 28|2@1+ (1,0) [0|0] "-" CM4
 SG_ dispTipperStateSideWall_BASE : 30|2@1+ (1,0) [0|0] "-" CM4
 SG_ dispLimpHomeMode_BASE : 32|4@1+ (1,0) [0|0] "-" CM4
 SG_ tailGateRsp_BASE : 36|2@1+ (1,0) [0|0] "-" CM4
 SG_ ureaLvlWarningDisp1_BASE : 38|2@1+ (1,0) [0|0] "-" CM4
 SG_ VASCsupplyPressureLow_BASE : 54|2@1+ (1,0) [0|0] "-" CM4
 SG_ auxStatMC24cntE2E_BASE : 56|4@1+ (1,0) [0|15] "-" CM4
 SG_ auxStatMC24chkE2E_BASE : 60|4@1+ (1,0) [0|15] "-" CM4
 SG_ alcolTestMessage_BASE : 8|4@1+ (1,0) [0|0] "-" CM4

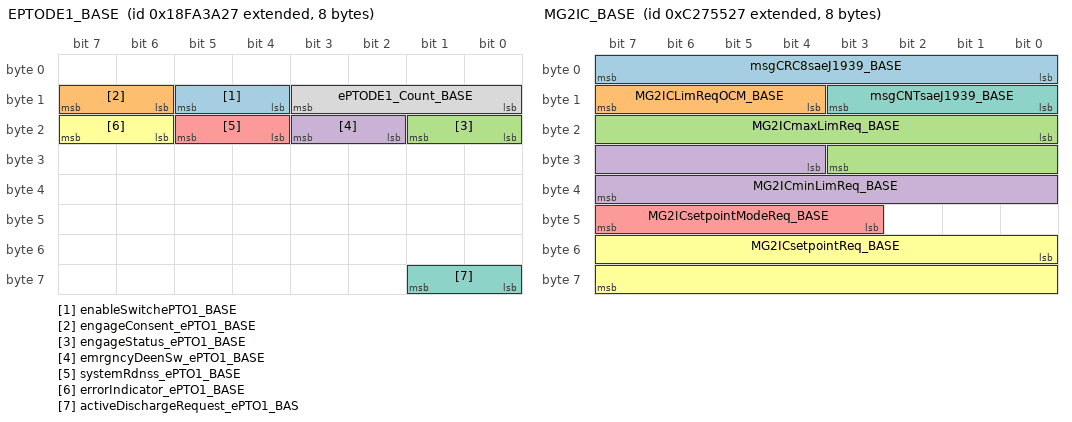
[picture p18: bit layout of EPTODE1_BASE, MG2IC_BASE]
BO_ 2566535719 EPTODE1_BASE: 8 Vector__XXX
 SG_ enableSwitchePTO1_BASE : 12|2@1+ (1,0) [0|0] "-" CM4
 SG_ engageConsent_ePTO1_BASE : 14|2@1+ (1,0) [0|0] "-" CM4
 SG_ engageStatus_ePTO1_BASE : 16|2@1+ (1,0) [0|0] "-" CM4
 SG_ emrgncyDeenSw_ePTO1_BASE : 18|2@1+ (1,0) [0|0] "-" CM4
 SG_ systemRdnss_ePTO1_BASE : 20|2@1+ (1,0) [0|0] "-" CM4
 SG_ errorIndicator_ePTO1_BASE : 22|2@1+ (1,0) [0|0] "-" CM4
 SG_ activeDischargeRequest_ePTO1_BAS : 56|2@1+ (1,0) [0|0] "-" CM4
 SG_ ePTODE1_Count_BASE : 8|4@1+ (1,0) [0|15] "-" CM4

BO_ 2351387943 MG2IC_BASE: 8 Vector__XXX
 SG_ msgCRC8saeJ1939_BASE : 0|8@1+ (1,0) [0|255] "-" CM4
 SG_ MG2ICLimReqOCM_BASE : 12|4@1+ (1,0) [0|0] "-" CM4
 SG_ MG2ICmaxLimReq_BASE : 16|12@1+ (0.0625,-125) [-125|125.9375] "%" CM4
 SG_ MG2ICminLimReq_BASE : 28|12@1+ (0.0625,-125) [-125|125.9375] "%" CM4
 SG_ MG2ICsetpointModeReq_BASE : 43|5@1+ (1,0) [0|0] "-" CM4
 SG_ MG2ICsetpointReq_BASE : 48|16@1+ (0.00390625,-125) [-125|125.99609375] "%" CM4
 SG_ msgCNTsaeJ1939_BASE : 8|4@1+ (1,0) [0|15] "-" CM4

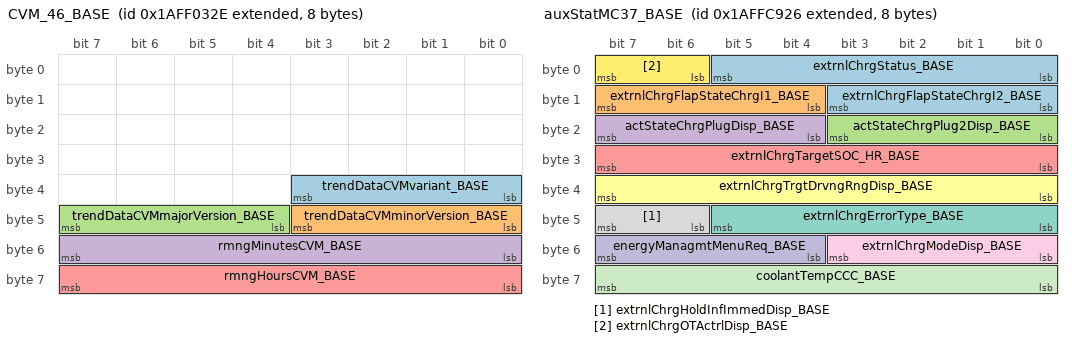
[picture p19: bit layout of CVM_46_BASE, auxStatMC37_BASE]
BO_ 2600403758 CVM_46_BASE: 8 Vector__XXX
 SG_ trendDataCVMvariant_BASE : 32|4@1+ (1,0) [0|0] "-" CM4
 SG_ trendDataCVMminorVersion_BASE : 40|4@1+ (1,0) [0|15] "-" CM4
 SG_ trendDataCVMmajorVersion_BASE : 44|4@1+ (1,0) [0|15] "-" CM4
 SG_ rmngMinutesCVM_BASE : 48|8@1+ (1,0) [0|250] "min" CM4
 SG_ rmngHoursCVM_BASE : 56|8@1+ (1,0) [0|250] "h" CM4

BO_ 2600454438 auxStatMC37_BASE: 8 Vector__XXX
 SG_ extrnlChrgStatus_BASE : 0|6@1+ (1,0) [0|0] "-" CM4
 SG_ extrnlChrgFlapStateChrgI1_BASE : 12|4@1+ (1,0) [0|0] "-" CM4
 SG_ actStateChrgPlug2Disp_BASE : 16|4@1+ (1,0) [0|0] "-" CM4
 SG_ actStateChrgPlugDisp_BASE : 20|4@1+ (1,0) [0|0] "-" CM4
 SG_ extrnlChrgTargetSOC_HR_BASE : 24|8@1+ (0.5,0) [0|125] "%" CM4
 SG_ extrnlChrgTrgtDrvngRngDisp_BASE : 32|8@1+ (10,0) [0|2500] "km" CM4
 SG_ extrnlChrgErrorType_BASE : 40|6@1+ (1,0) [0|0] "-" CM4
 SG_ extrnlChrgHoldInfImmedDisp_BASE : 46|2@1+ (1,0) [0|0] "-" CM4
 SG_ extrnlChrgModeDisp_BASE : 48|4@1+ (1,0) [0|0] "-" CM4
 SG_ energyManagmtMenuReq_BASE : 52|4@1+ (1,0) [0|0] "-" CM4
 SG_ coolantTempCCC_BASE : 56|8@1+ (1,-40) [-40|210] "°C" CM4
 SG_ extrnlChrgOTActrlDisp_BASE : 6|2@1+ (1,0) [0|0] "-" CM4
 SG_ extrnlChrgFlapStateChrgI2_BASE : 8|4@1+ (1,0) [0|0] "-" CM4

CM_ SG_ 2566807232 tyreWheelIdentification_T2_TO_T1 "It shall indicate the identification number of the tyre or wheel. The identification number shall specify the tyre or wheel position on each axle (bit 1 to bit 4) and the number of axles starting from the front of the respective towed vehicle (bit 5 to bi";
CM_ SG_ 2566807232 tireAirLeakageRate_T2_TO_T1TRUCK "This signal indicates the current air leakage (pressure loss) of a tyre. This signal is used in conjunction with the tyre/wheel identification.";
CM_ SG_ 2566807232 tirePressureThresholdDetection_T "This signal indicates the pressure level of one specific tyre. This signal is used in conjunctionwith the tyre/wheel identification.";
CM_ SG_ 2566807232 tireModulePowerSupply_T2_TO_T1TR "This signal indicates the current status of the power supply of the tyre module. It shall indicate whether it is sufficient to achieve the specified performance of the module. This parameter is used in conjunction with the tyre/wheel identification.";
CM_ SG_ 2566807232 identificationDataIndex_BASE "This signal shall be used as an index to an array of identification data as defined by the signal identification data conten and shall not be used without that context.";
CM_ SG_ 2566807232 identificationDataContent_BASE "This signal shall be interpreted as an array of identification data that is indexed by the signal ¿identification data index¿.";
CM_ SG_ 2566807232 tireTemperature_T2_TO_T1TRUCK "This signal indicates the current temperature of a tyre. This signal is used in conjunction with the tyre/wheel identification.";
CM_ BO_ 2365571367 "fast info for BodyBuilder";
CM_ SG_ 2365571367 highVoltSysModeAct_BASE "current operating mode of the high voltage system";
CM_ SG_ 2365571367 remDrvRangeWarning_BASE "The signal shows the current status of the TES energy content (in consideration of the SOC and the range).";
CM_ SG_ 2365571367 BattSysCritOtWarn_BASE "Critical battery system over-temperature warning";
CM_ SG_ 2365571367 PelOutInFlowTES_BASE "power flow / power outflow in/from TES (traction energy storage) positive: charge negative: discharge";
CM_ SG_ 2365571367 ePTOPowerDisp_BASE "value for ePTO power %";
CM_ SG_ 2365571367 battInstEngy_BASE "The instantous energy consumption divided by actual vehicle velocity.";
CM_ SG_ 2365571367 redVehAcousticModeReq_BASE "Requested acoustic mode for reduced acoustic emission of the vehicle.";
CM_ SG_ 2364577418 HVESSpassiveIsoTestStatus_BASE "Status of the high-voltage bus electrical passive isolation test as performed by the High Voltage Energy Storage System (or Pack 1 in systems with only one pack).";
CM_ SG_ 2364577418 HVESSintrnlChrgrState_BASE "Indicates that the charger in this HVES instance is on. SAE-SPN: 8207";
CM_ SG_ 2364577418 HVESSnumberOfHVESPready_BASE "The number of High-Voltage Energy Storage Packs that are currently ready to provide high-voltage energy. This signal will increment after contactors are closed. SAE-SPN: 12905";
CM_ BO_ 2600403782 "CANMSG CVM_64";
CM_ SG_ 2600403782 tscSAarbReqRE_BASE "The signal transmits the source address of the torque specification to the primary retarder.";
CM_ SG_ 2600403782 tscSAarbReqRD_BASE "The signal transmits the source address of the torque specification to the secondary retarder.";
CM_ SG_ 2600403782 acclCtrlActuatorMode_BASE "Signal indicates the actuator mode of acceleration control.";
CM_ SG_ 2600403782 CCreqTscOcmSek01_BASE "Maximum speed limitation/road speed limiter request; Request mode to the engine (Override Control Mode) as a component of the secondary side internal TSC for the engine. The request mode is used by the requesting function to define whether the request is ";
CM_ SG_ 2600403782 CCreqTscOcmSek00_BASE "Request from cruise control; Request mode to the engine (Override Control Mode) as a component of the secondary side internal TSC for the engine. The request mode is used by the requesting function to define whether the request is a restriction or a speci";
CM_ SG_ 2600403782 highVoltageActv_BASE "Indication of the HighVoltate-Status (active/not active) according to the highVoltage-switches of the traction energy storage (connected/not connected)";
CM_ BO_ 2600403784 "CANMSG CVM_66";
CM_ SG_ 2600403784 kneelingActivationData_BASE "This signal describes the frequency of active kneeling during an ignition cycle.";
CM_ SG_ 2600403784 NN2ActivationData_BASE "This signal describes the distance driven with active nominal level 2 during an ignition cycle.";
CM_ SG_ 2600403784 NN3ActivationData_BASE "This signal describes the distance driven with active nominal level 3 during an ignition cycle.";
CM_ SG_ 2600403784 speedDependentLvlActivationData_ "This signal describes the distance driven with active speed dependent level during an ignition cycle.";
CM_ BO_ 2600403785 "CANMSG CVM_67";
CM_ SG_ 2600403785 valveActivationDataSPA1_BASE "This signal describes the frequency of valve activation of the SPA 1 during an ignition cycle.";
CM_ SG_ 2600403785 valveActivationDataSPA2_BASE "This signal describes the frequency of valve activation of the SPA 2 during an ignition cycle.";
CM_ SG_ 2600403785 valveActivationDataSPA3_BASE "This signal describes the frequency of valve activation of the SPA 3 during an ignition cycle.";
CM_ SG_ 2600403785 valveActivationDataSPA4_BASE "This signal describes the frequency of valve activation of the SPA 4 during an ignition cycle.";
CM_ BO_ 2566898215 "bodyBuilderInfo4";
CM_ SG_ 2566898215 pssblRngExt_ePTO_BASE "The estimated possible range extension by switching off the electric Power Take Off (ePTO) system.";
CM_ SG_ 2566898215 currPwrCnsmptEPTO_BASE "current power delivery of the ePTO(contactor box) / (negative values for power consumption of ePTO)";
CM_ SG_ 2566898215 remOperatingTime_BASE "Remaining operating time of the vehicle in standstill considering auxiliary consumers and the remaining energy stored in the TES.";
CM_ SG_ 2566898215 sMeanPowerTES_BASE "1 s mean value of the power output of the Traction Energy Storage (TES). Power flowing into the TES has a positive sign, power flowing out of the TES has a negative sign.";
CM_ BO_ 2566898182 "bodyBuilderInfo6";
CM_ SG_ 2566898182 tourDataSetMux_BASE "Index of Selected Trip";
CM_ SG_ 2566898182 energyConsumptionEPTO_BASE "ePTO consumption since the last selected trip reset.";
CM_ BO_ 2566848295 "Operator indicators: Transmission Repetition Rate: 10 s or on change but no more often than 1s";
CM_ SG_ 2566848295 fuelSupplyEstimatedRemainingDist "Estimated remaining distance based on existing fuel supply. (SPN 8428)";
CM_ BO_ 2600403787 "CANMSG CVM_69";
CM_ SG_ 2600403787 steeringWheelAngle_BASIS "The main operator's steering wheel angle (on the steering column, not the actual wheel angle). The vehicle being steered to the left results in a positive steering wheel angle.";
CM_ SG_ 2600403787 engineSpeed_BASIS "Actual engine speed which is calculated over a minimum crankshaft angle of 720 degrees divided by the number of cylinders.";
CM_ SG_ 2600403787 transmissionInputShaftSpeed_BASI "Rotational velocity of the primary shaft transferring power into the transmission. When a torque converter is present, it is the output of the torque converter.";
CM_ SG_ 2600403787 transmissionOutputShaftSpeed_BAS "Calculated speed of the transmission output shaft.";
CM_ BO_ 2600454439 "CANMSG auxStatMC38";
CM_ SG_ 2600454439 highVoltSysModeAct_BASE "current operating mode of the high voltage system";
CM_ SG_ 2600454439 vehParkingMode_BASE "This signal describes whether the vehicle is in operation mode parking.";
CM_ SG_ 2600454439 remDrvRangeWarning_BASE "The signal shows the current status of the TES energy content (in consideration of the SOC and the range).";
CM_ SG_ 2600454439 stateOfChargeTES_BASE "Relative charge state of the TES (traction energy accumulator).";
CM_ SG_ 2600454439 dispFuelVolume_BASE "fuel volume to display";
CM_ SG_ 2600454439 ePTOPowerDisp_BASE "value for ePTO power %";
CM_ SG_ 2600454439 remDrivingRangeEnergy_BASE "Remaining range for the existing energy content of the TES.";
CM_ SG_ 2600454439 warningSOCoverflowDisp_BASE "This signal indicates a possible retarder brake overloading warning for further use.";
CM_ SG_ 2600454439 LimpHomeMode_BASE "The signal indicates whether the creep mode is active.";
CM_ BO_ 2600403759 "CANMSG CVM_47";
CM_ SG_ 2600403759 estCorrSpdTrjConfiAdapt_BASE "Confidence of the estimated correction coefficient";
CM_ SG_ 2600403759 estCorrSpdClsAdapt_BASE "the signal indicates in which speed range the transmitted value of CANSIG: estCorrSpdTrjAdapt is valid";
CM_ SG_ 2600403759 estCorrSpdTrlAdapt_BASE "signal indicated if CANSIG: estCorrSpdClsAdapt is taken without (0) or with trailer .";
CM_ SG_ 2600403759 vehSpd2ShaftSpdRatioAdapt_BASE "Ratio of vehicle speed [m/s] to angular speed of transmission output. f_vehSpd2ShaftSpdRatio [ (m/s) / (rad/s) = m/rad ] = Vehicle speed [km/h] / output shaft speed [rpm] * (30/pi) [rpm->rad/s] / 3.6 [km/h ->m/s].";
CM_ SG_ 2600403759 equSlopeDrvResistAdapt_BASE "calculated substitute slope value";
CM_ SG_ 2600403759 estAvgHVpower24V_BASE "The estimated average HV-power consumption of the Air Management System (AMS).";
CM_ SG_ 2600403759 estCorrSpdTrjAdapt_BASE "Estimated correction coefficient of the equivalent slope value of the parameter estimate of the vehicle function PCCA. (Parameter must be multiplied by the calculated equivalent slope value)";
CM_ BO_ 2566827568 "Air Supply Pressure - SAE variant";
CM_ SG_ 2566827568 pneumaticSupplyPressure_BASIS "Pneumatic Supply Pressure";
CM_ SG_ 2566827568 serviceBrakeAirPressureCircuit1_ "serviceBrakeAirPressureCircuit1; at MAN: Circuit 1";
CM_ SG_ 2566827568 serviceBrakeAirPressureCircuit2_ "serviceBrakeAirPressureCircuit2; at MAN: Circuit 2";
CM_ SG_ 2566827568 auxiliaryEquipmentSupplyPressure "The pneumatic pressure in the auxiliary circuit.";
CM_ SG_ 2566827568 airSuspensionSupplyPressure_BASI "The pneumatic pressure in the circuit for the electronically controlled air suspension system.";
CM_ SG_ 2566827568 airCompressorStatus_BASE "Indicates whether the air compressor is actively compressing air. SPN 1351";
CM_ SG_ 2566827568 parkingTrailerAirPressure_BASIS "parkingTrailerAirPressure; at MAN: Circuit 3";
CM_ BO_ 2600407434 "prop. message for the transmission of customer-specific signals 2";
CM_ SG_ 2600407434 actElHVpowHVAC_BASE "currently consumed electrical power (HV) of the HVAC system";
CM_ SG_ 2600407434 PelOutInFlowTES_BASE "power flow / power outflow in/from TES (traction energy storage) positive: charge negative: discharge";
CM_ SG_ 2600407434 stCombHeat_BASE "Feedback of the current status of the combustion heater of the climate system.";
CM_ SG_ 2600407434 actStatePreCond_BASE "information that the preconditioning of the vehicle interior is active";
CM_ SG_ 2600407434 thermalAlertPredctnTES_BASE "condition of the TES (traction energy accumulator) warning of increased temperature";
CM_ SG_ 2600407434 actElPowAirComp_BASE "Power consumption of the electric air compressor.";
CM_ SG_ 2600407434 actModeHVAC1_BASE "Current control mode of the climate controller in a solobus or in the rear of the vehicle of an articulated bus.";
CM_ SG_ 2600407434 actElPowPwrtrn_BASE "Actual electrical power of the powertrain. negative: recuperation positive: consumption";
CM_ BO_ 2566841088 "This map describes the stationary behavior of the engine and the speed dependent available indicated torque. This map should reflect the effect of changes due to barometric pressure, engine temperature, and any other stationary changes (sensor failures, e";
CM_ SG_ 2566841088 engineReferenceEngineTorque_BASI "This parameter is the 100% reference value for all defined indicated engine torque parameters. It is only defined once and doesn't change if a different engine torque map becomes valid.";
CM_ SG_ 2566841088 maxMomEngOverSpeedPoint7_BASIS "The maximum engine speed above high idle allowed by the engine control during a momentary high idle override. This duration of the override is limited by the maximum momentary override time limit, SPN 534.";
CM_ BO_ 2600403768 "CANMSG CVM_56";
CM_ SG_ 2600403768 fuelConsptDriveCycle_BASE "Added fuel consumption over the operating cycle.";
CM_ SG_ 2600403768 pitchAngleTruckAndTrailer_BASE "Effective angle of the vehicle/trailer combination (tractor vehicle + trailer) relative to the horizontal. The small angle approximation was used to convert rad to %: % = 100 x rad";
CM_ BO_ 2600403769 "CANMSG CVM_57";
CM_ SG_ 2600403769 activeTimeTSI_TD_BASE "Active time of traffic sign information between system activation and manual deactivation by the driver.";
CM_ SG_ 2600403769 clutchEnergy_BASE "Induced Clutch Energy.";
CM_ SG_ 2600403769 reqDrivingDir1_BASE "Requested driving range by the driving range switch";
CM_ BO_ 2600403766 "CANMSG CVM_54";
CM_ SG_ 2600403766 commandTorqueCCDI_BASE "commandTorqueCCDI";
CM_ BO_ 2600403777 "CANMSG CVM_59";
CM_ SG_ 2600403777 transCurRange_BASE "Engaged driving mode request: This signal indicates the currently active driving mode.";
CM_ SG_ 2600403777 transReqRange_BASE "Driving mode selection: This signal indicates the value for the driving mode.";
CM_ SG_ 2600403777 engineOperatingState_BASE "This parameter is used to indicate the current state, or mode, of operation by the engine. For details see SAE J1939-71 signal description.";
CM_ SG_ 2600403777 clutchFrictionActive_BASE "heat input due to active clutch friction.";
CM_ SG_ 2600403777 engStart_BASE "This signal is used to request a start of the internal combustion engine.";
CM_ SG_ 2600403777 MONd_safetyReactionDrivetrain_BA "This signal indicates whether a safety response is triggered in the clutch path.";
CM_ SG_ 2600403777 DrvOffAgnstCurDrvDirActv_BASE "This signal indicates whether a drive off against the vehicle's current direction of movement is active.";
CM_ SG_ 2600403777 manualModeRequest_BASE "This signal indicates a request to switch to manual mode.";
CM_ SG_ 2600403777 manualRetarderControl_BASIS "Manual Retarder Control";
CM_ SG_ 2600403777 decreaseGear_BASE "Reduce gear button";
CM_ SG_ 2600403777 displayMonErrTorqueSpeedReq_BASE "Signal indicating a safety response (engine speed / torque restriction) due to a violation of the engine speed / torque specification.";
CM_ BO_ 2600403776 "CANMSG CVM_58";
CM_ SG_ 2600403776 vehSpdFrontAxle_BASE "Durchschnittsgeschwindigkeit der beiden Vorderräder (Vorderachsgeschwindigkeit). Diese Fahrzeuggeschwindigkeit ist auf die Fahrzeuggeschwindigkeit des Tachographen (TCO) adaptiert.";
CM_ SG_ 2600403776 EmgcyBrkSysStatePlausi_BASE "This signal indicates the plausibilized EBA (emergency brake assist) system state according to SAE.";
CM_ SG_ 2600403776 EBAarbObjMotionType_BASE "This signal indicates the arbitrated object motion type.";
CM_ SG_ 2600403776 XBRextAccelDemEBA1_BASE "External EBA acceleration request (emergency brake assist) that the braking system must execute.";
CM_ SG_ 2600403776 actualRange_BASE "Gear group determined from the gear calculation.";
CM_ SG_ 2600403776 vehicleDriveState_BASE "This signals shows the current drive direction.";
CM_ SG_ 2600403776 engState_BASE "Current Engine state.";
CM_ BO_ 2600403764 "CANMSG CVM_52";
CM_ SG_ 2600403764 shiftInProcess_BASIS "Indicates that the transmission is in process of shifting from the current gear to the selected gear. This state is generally ACTIVE during the entire time that the transmission controls the vehicle. This includes any transmission clutch control, all engi";
CM_ SG_ 2600403764 dispDriveConfigMode_BASE "Display signal for drive config mode";
CM_ SG_ 2600403764 reqDrivingDir_BASE "Requested driving range by the driving range switch";
CM_ SG_ 2600403764 SOCuserTES_BASE "Current user SoC (state of charge) of the TES (traction energy storage). This is the SoC that is expected to be in use, after rescaling with upper and lower usage limits, but before final filtering and trimming for the cluster.";
CM_ SG_ 2600403764 comfortShiftState_BASE "actual state of the function Comfort Shift";
CM_ BO_ 2600403786 "CANMSG CVM_68";
CM_ SG_ 2600403786 tractionHelpActivationData_BASE "This signal describes the distance driven with active traction help during an ignition cycle.";
CM_ SG_ 2600403786 technicalAxleLoadExceededStatus_ "This signal indicates that the technical axle load has been exceeded (absolute value in kg). Value 0 kg corresponds to a non-existing exceedance. The axle position is specified via the additional information of the axleLocation.";
CM_ SG_ 2600403786 memoryLevelActivationData_BASE "This signal describes the frequency of memory level activation during an ignition cycle.";
CM_ SG_ 2600403786 lowPressModeActiveData_BASE "This signal describes the frequency of an active low pressure mode during an ignition cycle.";
CM_ SG_ 2600403786 AP1lowIdleSwitch_BASIS "Switch signal which indicates the state of the accelerator pedal 1 low idle switch. The low idle switch is defined in SAE Recommended Practice J1843.";
CM_ SG_ 2600403786 creepCtrlConvAct_BASE "status creep mode";
CM_ SG_ 2600403786 transReqGear_BASE "Requested Gear";
CM_ SG_ 2600403786 MONd_errSA_BASE "Arbitrated source address prepared for diagnostics at the time of the last safety response";
CM_ SG_ 2600403786 MONd_safetyReactionSpdReq_BASE "This signal indicates whether a safety response is triggered in the path that specifies the engine speed.";
CM_ BO_ 2600403780 "CANMSG CVM_62";
CM_ SG_ 2600403780 MONd_safetyReactionTrqReq_BASE "This signal indicates whether a safety response is triggered in the path that specifies the torque.";
CM_ BO_ 2600403783 "CANMSG CVM_65";
CM_ SG_ 2600403783 CCmodeState_BASE "This signal indicates the status of the cruise control.";
CM_ SG_ 2600403783 tsiSpeedLimitViolationTD_BASE "This signal shows, if the speed limit is currently violated.";
CM_ SG_ 2600403783 ureaLvlWarningDisp1_BASE "First Warning due to low urea level active";
CM_ SG_ 2600403783 ureaLvlWarningDisp2_BASE "Second Warning due to low adBlue level aktiv";
CM_ SG_ 2600403783 pitchAngleTruck_BASE "Angle of the towing vehicle relative to the horizontal. The small angle approximation was used for the conversion from rad to %used: % = 100 x rad";
CM_ BO_ 2600403779 "CANMSG CVM_61";
CM_ SG_ 2600403779 hydroDriveState_BASE "current system state of HydroDrive";
CM_ SG_ 2600403779 PTO2deactivationReq_BASE "Indicates if PTO2 has been deactivated manual or automated. An automated deactivation can be caused by internal faults or caused by a manual gear shift (misuse by operator).";
CM_ SG_ 2600403779 PTO1deactivationReq_BASE "Indicates if PTO1 has been deactivated manual or automated. An automated deactivation can be caused by internal faults or caused by a manual gear shift (misuse by operator).";
CM_ SG_ 2600403779 actualEngineTorque_BASE "Actual internal engine drive torque of engine with percental reference to the reference torque.";
CM_ SG_ 2600403779 SATorqCtrPri_BASE "Source address of the active primary side torque specification for the engine";
CM_ BO_ 2600403767 "CANMSG CVM_55";
CM_ SG_ 2600403767 CCvehSpd_BASE "Vehicle speed for the cruise control function.";
CM_ SG_ 2600403767 TSIactivatedTD_BASE "This signal shows the current status of the speed warning enabled setting.";
CM_ SG_ 2600403767 PTO1req_BASE "PTO1 request";
CM_ SG_ 2600403767 shiftLockDueToAirDiagSt_BASE "Status signal to the diagnostic manager: Shift lock due to air pressure.";
CM_ SG_ 2600403767 PTO2req_BASE "PTO2 request";
CM_ SG_ 2600403767 driveOffAct_BASE "Indicator of whether moving off is active or whether the clutch is closed for PTO";
CM_ SG_ 2600403767 reqDrivingProg_BASE "Driving program resulting from the driver control.";
CM_ BO_ 2600403778 "CANMSG CVM_60";
CM_ SG_ 2600403778 totalRevoltnDriveCycle_BASE "Number of crankshaft revolutions in the operating cycle.";
CM_ SG_ 2600403778 clamp30_BASE "Voltage of terminal 30. Note: This signal can be deactivated if equipped with battery emergency off switch or with main battery switch.";
CM_ SG_ 2600403778 liftAxleActivationData_BASE "This signal describes the frequency of lift axle processes (lowering/lifting) during an ignition cycle.";
CM_ SG_ 2600403778 dispMGSpressClutch_BASE "Hint to press the clutch";
CM_ SG_ 2600403778 EBSbrakeSwitch_BASIS "Switch signal which indicates that the brake pedal is being pressed. The EBS brake switch is &#x0A;independent of the brake light switch and has no provisions for external connections.";
CM_ SG_ 2600403778 activationStatusEPTO_BASE "Signal indicates the connection state of the ePTO.";
CM_ BO_ 2667525635 "MC --> AppFramework";
CM_ SG_ 2667525635 appValSlider5_BASE "App Value of Slider 5";
CM_ SG_ 2667525635 appMinValSlider5_BASE "App Minimum Value of Slider 5";
CM_ SG_ 2667525635 appMaxValSlider4_BASE "App Maximum Value of Slider 4";
CM_ SG_ 2667525635 appMinValSlider4_BASE "App Minimum Value of Slider 4";
CM_ SG_ 2667525635 appEnaSlider5_BASE "App Enable Slider 5";
CM_ SG_ 2667525635 appEnaSlider4_BASE "App Enable Slider 4";
CM_ SG_ 2667525635 appEnaSlider6_BASE "App Enable Slider 6";
CM_ SG_ 2667525635 appEnaSlider1_BASE "App Enable Slider 1";
CM_ SG_ 2667525635 appMinValSlider6_BASE "App Minimum Value of Slider 6";
CM_ SG_ 2667525635 appMaxValSlider6_BASE "App Maximum Value of Slider 6";
CM_ SG_ 2667525635 appValSlider4_BASE "App Value of Slider 4";
CM_ SG_ 2667525635 appValSlider6_BASE "App Value of Slider 6";
CM_ SG_ 2667525635 appEnaSlider2_BASE "App Enable Slider 2";
CM_ SG_ 2667525635 appEnaSlider3_BASE "App Enable Slider 3";
CM_ SG_ 2667525635 drvProgIndivActive_BASE "indivdual drive progam active";
CM_ SG_ 2667525635 appMaxValSlider5_BASE "App Maximum Value of Slider 5";
CM_ BO_ 2600403760 "CANMSG CVM_48";
CM_ SG_ 2600403760 hyrdgnMaxTankTemperature_BASE "Current maximum temperature measured in all tanks.";
CM_ SG_ 2600403760 hyrdgnTemperatureHighSide_BASE "TemperatureHighSide";
CM_ SG_ 2600403760 hyrdgnMinTankTemperature_BASE "Current minimum temperature measured in all tanks.";
CM_ BO_ 2566080807 "Fuel Cell Compartment Information Contains the Fuel Cell Compartment Information.";
CM_ SG_ 2566080807 FCCI_placeholder_BASE "Place Holder signal";
CM_ BO_ 2566675782 "Configuration data for High Voltage Energy Storage System (or Pack 1 in systems with only one pack). Note that configuration data should not dynamically change during vehicle operation. ";
CM_ SG_ 2566675782 HVESSnumberOfHVESPconfig_BASE "The number of High-Voltage Energy Storage Packs that are currently configured in the HVESS system. SAE-SPN: 12904";
CM_ BO_ 2566678922 "EV Operator Indicators 1";
CM_ SG_ 2566678922 HVESSestRemDist_BASE "Estimated remaining distance based on existing available HVES system capacity. SAE-SPN: 15268";
CM_ BO_ 2566827815 "Fuel Consumption (Gaseous)";
CM_ SG_ 2566827815 tripFuelGas_BASE "Total fuel consumed (trip drive fuel + trip PTO governor moving fuel + trip PTO governor non-moving fuel + trip idle fuel) since the last trip reset. SAE-SPN 1039";
CM_ SG_ 2566827815 totalFuelUsedGas_BASE "Total fuel consumed (trip drive fuel + trip PTO governor moving fuel + trip PTO governor non-moving fuel + trip idle fuel) over the life of the engine.";
CM_ BO_ 2565865488 "NOTE- This message will be transmitted by several types of retarding devices such as engine compression release brakes, exhaust system restriction brakes, and driveline retarders using hydraulic, electric, or mechanical friction to slow the vehicle. The s";
CM_ SG_ 2565865488 retarderTorqueMode_RD "State signal which indicates which retarder torque mode is currently generating, limiting, or controlling the torque. Note that the modes are not in prioritized order. Not all modes may be relevant for a given device. Some devices may not implement all fu";
CM_ SG_ 2565865488 intendedRetarderPercentTorque_RD "Braking torque of retarder that the retarder is currently trying to achieve. This value takes into account all static limitations, but not the limitations due to the dynamic behavior of the retarder. This value, if unchanged over a certain time, can and w";
CM_ SG_ 2565865488 sourceAddressOfControllDevice_RD "The source address of the SAE J1939 device currently controlling the brake system. Its value may be the source address&#x0A;of the ECU transmitting the message (which means that no external SAE J1939 message is providing the active command)&#x0A;or the so";
CM_ SG_ 2565865488 driversDemandRetarderPercTorque_ "The Drivers demand retarder ¿ percent torque is the maximum torque selected by the driver when one or more modes are selected by the driver, such as hand lever, switch, constant torque, constant velocity, etc.";
CM_ SG_ 2565865488 reqTorqRDbyDriver_BASE "Signal provides requested percentage torque which is requested by retarder lever to driveline retarder.";
CM_ SG_ 2565865488 actMaxAvailRetPercTorque_RD "This is the maximum amount of torque that the retarder can immediately deliver. It is the same as the maximum torque shown in the Retarder¿s Configuration message, but allows for a much faster rate of change than could be communicated by reissuing the con";
CM_ SG_ 2565865488 actualRetarderPercentTorque_RD "Actual braking torque of the retarder as a percent of retarder configuration reference torque SPN 556.";
CM_ BO_ 2566845479 "Tire Condition Message";
CM_ SG_ 2566845479 tireLocation_BASE "To identify to which of several similar devices (such as tires or fuel tanks) the information applies.The low order 4 bits represent a position number, counting left to right when facing in the direction of normal vehicle travel (forward).The high order 4";
CM_ SG_ 2566845479 tireStatus_BASE "Indicates whether or not a fast pressure loss is occurring";
CM_ SG_ 2566845479 tireSensorElectricalFault_BASE "Indicates the status of electrical fault on the tire sensor.";
CM_ SG_ 2566845479 tirePressureThresholdDetection_B "Signal indicating the pressure level of the tire. The levels defined represent different pressure conditions of the tire.";
CM_ SG_ 2566845479 tirePressure_SAE "Pressure at which air is contained in cavity formed by tire and rim.";
CM_ SG_ 2565866755 transmissionSelectedGear_BASIS "The gear that the transmission will attempt to achieve during the current shift if a shift is in progress, or the next shift if one is pending (i.e., waiting for torque reduction to initiate the shift). 0xFB=park";
CM_ SG_ 2565866755 transmissionCurrentGear_BASIS "The gear currently engaged in the transmission or the last gear engaged while the transmission is in the process of shifting to the new or selected gear. Negative values are reverse gears, 0xFB is park.";
CM_ SG_ 2565866755 transmissionActualGearRatio_BASI "Actual ratio of input shaft speed to output shaft speed.";
CM_ BO_ 2566774823 "CANMSG AMB2 (Ambient Conditions 2) This message contains measurement and configuration information about the vehicle ambient conditions.";
CM_ SG_ 2566774823 AMB2_placeholder_BASE "Place Holder signal";
CM_ BO_ 2566687271 "CANMSG FCCP2S (Fuel Cell Coolant Pump 2 Status) Indicates the status of Fuel Cell Coolant Pump 2.  Note: See PGN 64648 (Fuel Cell Coolant Pump 2 Command) for corresponding command message.";
CM_ SG_ 2566687271 FCCP2S_placeholder_BASE "Place Holder signal";
CM_ BO_ 2566575143 "CANMSG EVSEACS2 (EVSE AC Status 2) This message contains diagnostic information about power supplied from the EVSE.";
CM_ SG_ 2566575143 EVSEACS2_placeholder_BASE "Place Holder signal";
CM_ BO_ 2566686247 "CANMSG FCHTR (Fuel Cell Auxiliary Heater Information) Contains the Fuel Cell Auxiliary Heater Information.";
CM_ SG_ 2566686247 FCHTR_placeholder_BASE "Place Holder signal";
CM_ BO_ 2565902887 "CANMSG HVESSD3 (High Voltage Energy Storage System Data 3) Data set 3 (thermal data) for High Voltage Energy Storage System (or Pack 1 in systems with only one pack).";
CM_ SG_ 2565902887 highestCellTempHVESS_BASE "The highest temperature level reported by any cell in the Traction Energy Storage System";
CM_ SG_ 2565902887 lowestCellTempHVESS_BASE "The lowest temperature level reported by any cell in the Traction Energy Storage System";
CM_ SG_ 2565902887 avrgCellTempHVESS_BASE "Average temperature TES system temperature.";
CM_ BO_ 2566775079 "CANMSG CCSI1 (Cab Climate System Information 1) This message contains measurement and condition information from cab HVAC components.";
CM_ SG_ 2566775079 AirConditionerCompressorStatus_B "Air Conditioner Compressor Status for VDV238";
CM_ BO_ 2566676038 "High Voltage Energy Storage System History Source Address 0x71 Hochvoltbatterie ";
CM_ SG_ 2566676038 HVESSstateOfHealth_BASE "This signal represents the expected remaining Life of the High Voltage Energy Storage System in percent. 100% Begin of Life 0% End of Life SAE SPN: 8121";
CM_ SG_ 2566676038 HVESSTotalLifetimeEnrgOut_BASE "The cumulative energy which has flowed out of the High Voltage Energy Storage System over the lifetime of the battery system";
CM_ SG_ 2566676038 HVESSTotalLifetimeEnrgInp_BASE "The cumulative energy which has flowed into the High Voltage Energy Storage System over the lifetime of the battery system";
CM_ SG_ 2566701706 storedEnrgySrcLevel_BASE "Stored Energy Source Level indicates the current operating stored HVES energy capacity available for use. SAE-SPN: 7895";
CM_ SG_ 2566701706 extrnlEnergySrcConnection_BASE "Connection status of the external energy source";
CM_ SG_ 2566701706 sysPropDisState_BASE "Indicates if the system is in a state where propulsion is not available. SAE-SPN: 8267";
CM_ SG_ 2566701706 propulsionSystemActive_BASE "Propulsion System Active";
CM_ BO_ 2600403798 "CANMSG CVM_80";
CM_ SG_ 2600403798 CVM80placeholder_BASE "Placeholder signal";
CM_ BO_ 2600403790 "CANMSG CVM_72";
CM_ SG_ 2600403790 CVM72placeholder_BASE "Placeholder signal";
CM_ BO_ 2600403794 "CANMSG CVM_76";
CM_ SG_ 2600403794 CVM76placeholder_BASE "Placeholder signal";
CM_ BO_ 2600403795 "CANMSG CVM_77";
CM_ SG_ 2600403795 CVM77placeholder_BASE "Placeholder signal";
CM_ BO_ 2600403797 "CANMSG CVM_79";
CM_ SG_ 2600403797 CVM79placeholder_BASE "Placeholder signal";
CM_ BO_ 2600403796 "CANMSG CVM_78";
CM_ SG_ 2600403796 CVM78placeholder_BASE "Placeholder signal";
CM_ BO_ 2600403789 "CANMSG CVM_71";
CM_ SG_ 2600403789 CVM71placeholder_BASE "Placeholder signal";
CM_ BO_ 2600403792 "CANMSG CVM_74";
CM_ SG_ 2600403792 CVM74placeholder_BASE "Placeholder signal";
CM_ BO_ 2600403793 "CANMSG CVM_75";
CM_ SG_ 2600403793 CVM75placeholder_BASE "Placeholder signal";
CM_ BO_ 2600407303 "prop. message for the transmission of customer-specific signals";
CM_ SG_ 2600407303 energyAvbl_BASE "Actual available energy of the traction energy storage (TES).";
CM_ SG_ 2600407303 actHVpowerBCC_BASE "Actual HV power of the components within the battery cooling circuit.";
CM_ SG_ 2600407303 act24VpowerBCC_BASE "Actual 24V power of the componentes within the battery cooling circuit.";
CM_ SG_ 2600407303 remDrvRangeWarning_BASE "The signal shows the current status of the TES energy content (in consideration of the SOC and the range).";
CM_ SG_ 2600407303 highVoltSysModeAct_BASE "current operating mode of the high voltage system";
CM_ SG_ 2600407303 LimpHomeMode_BASE "The signal indicates whether the creep mode is active.";
CM_ SG_ 2600407303 externalShutOffHVinfo_BASE "High-voltage shut-down due to emergency cause.";
CM_ SG_ 2600407303 vehParkingMode_BASE "This signal describes whether the vehicle is in operation mode parking.";
CM_ SG_ 2600407303 drvSysReadyToMove_BASE "Signal indicates whether the indicator light for the driving readiness display is to be switched on.";
CM_ BO_ 2600407296 "prop. message for the transmission of customer-specific signals";
CM_ SG_ 2600407296 battInstEngy_BASE "The instantous energy consumption divided by actual vehicle velocity.";
CM_ SG_ 2600407296 lowestCellTempSysTES_BASE "The lowest temperature level reported by any cell in the Traction Energy Storage System";
CM_ SG_ 2600407296 highestCellTempSysTES_BASE "The highest temperature level reported by any cell in the Traction Energy Storage System";
CM_ SG_ 2600407296 actStateChrgPlugDisp_BASE "state of the plug connector of the conductive charging interface for display purpose.";
CM_ SG_ 2600407296 directionIndicator_BASIS "Indicates the direction of the vehicle.";
CM_ SG_ 2600407296 actStateChrgPlug2Disp_BASE "State of the plug connector of the conductive charging interface 2 for display purpose.";
CM_ BO_ 2600403740 "CVM_28 body builder info 1 message";
CM_ SG_ 2600403740 coolantTempSetpointLR_BASE "Setpoint for the coolant temperature based on vehicle conditions.";
CM_ SG_ 2600403740 rollDetectedBB_BASE "Signal for the activation of the output through meeting the activation condition for body buílder";
CM_ SG_ 2600403740 eco24VpwrSaveReqExt_BASE "Energy saving level for 24V consumers (eco power save).";
CM_ SG_ 2600403740 ICErunning_BASE "Engine is running and is able to deliver torque.";
CM_ SG_ 2600403740 extCAMshown1_BASE "This signal indicates if the camera is shown: Camera on infotainment CAM-Port 1 (without camera-hub attached to CAM-Port 1).";
CM_ SG_ 2600403740 extCAMshown2_BASE "This signal indicates if the camera 2 is shown: It is currently mapped onto the Camera on camera-hub input 1 via infotainment CAM-Port 2 or the camera on MMT CAM-port 2.";
CM_ SG_ 2600403740 extCAMshown3_BASE "This signal indicates if the camera 3 is shown: It is currently mapped onto the Camera on camera-hub input 2 via infotainment CAM-Port 2 or the camera on MMT CAM-port 2.";
CM_ SG_ 2600403740 extCAMshown4_BASE "This signal indicates if the camera 4 is shown: It is currently mapped onto the Camera on camera-hub input 3 via infotainment CAM-Port 2 or the camera on MMT CAM-port 2.";
CM_ SG_ 2600403740 extCAMshown5_BASE "This signal indicates if the camera 5 is shown: It is currently mapped onto the Camera on camera-hub input 4 via infotainment CAM-Port 2 or the camera on MMT CAM-port 2.";
CM_ SG_ 2600403740 seatBeltDriverState_BASE "This signal indicates whether the driver's seatbelt is fastened.";
CM_ SG_ 2600403740 seatBeltCoDrvrState_BASE "This signal indicates whether the co-driver's seatbelt is fastened.";
CM_ SG_ 2600403740 CCswStatusComb_BASE "status of the cruise control controls from body builder, and from multi functional steering wheeler";
CM_ BO_ 2566847015 "Brakes 1 -";
CM_ SG_ 2566847015 brakeApplicationPressure_BASE "Gage pressure of compressed air or fluid in vehicle braking system measured at the brake chamber when brake shoe (or pad) is placed against brake drum (or disc).";
CM_ BO_ 2566660647 "CANMSG EEC19 (Electronic Engine Controller 19) Engine related parameters.";
CM_ SG_ 2566660647 totalEngineEnergy_BASE "The total amount of energy delivered by the engine. It is accumulated over the life of the engine.";
CM_ BO_ 2566840064 "Message Electronic Engine Controller 3";
CM_ SG_ 2566840064 nominalFrictionPercentTorque_BAS "The calculated torque that indicates the amount of torque required by the basic engine itself added by the loss torque of accessories. It contains the frictional and thermodynamic loss of the engine itself, and the losses of fuel, oil and cooling pumps. T";
CM_ SG_ 2566840064 estimatedEngineParasiticLossesPe "The calculated torque that indicates the estimated amount of torque loss due to engine parasitics, such as cooling fan, air compressor, air conditioning, etc. It is expressed as a percent of Engine Reference Torque.";
CM_ BO_ 2565865513 "ERC1";
CM_ SG_ 2565865513 actualRetarderPercentTorque_RX "Actual braking torque of the retarder as a percent of retarder configuration reference torque SPN 556.";
CM_ BO_ 2551906343 "CANMSG HVESSC1 (High Voltage Energy Storage System Control 1) Control commands to be sent to High Voltage Energy Storage System (or Pack 1 in systems with only one pack). ";
CM_ SG_ 2551906343 HVESSC1_placeholder_BASE "Place Holder signal";
CM_ BO_ 2565902631 "High Voltage Energy Storage System Data 2 Data set 2 (electrical data) for High Voltage Energy Storage System (or Pack 1 in systems with only one pack).";
CM_ SG_ 2565902631 HVESSD2_placeholder_BASE "Place Holder signal";
CM_ BO_ 2566687015 "CANMSG FCCP1S (Fuel Cell Coolant Pump 1 Status) PGN description  Indicates the status of Fuel Cell Coolant Pump 1.  Note: See PGN 64647 (Fuel Cell Coolant Pump 1 Command) for corresponding command message.";
CM_ SG_ 2566687015 FCCP1S_placeholder_BASE "Place Holder signal";
CM_ BO_ 2566570030 "CANMSG MG4LD (Motor/Generator 4 Lifetime Data) Contains data accumulated over the lifetime of this Motor/Generator.";
CM_ SG_ 2566570030 MG4LD_placeholder_BASE "Place Holder signal";
CM_ BO_ 2566569774 "CANMSG MG3LD (Motor/Generator 3 Lifetime Data) Contains data accumulated over the lifetime of this Motor/Generator.";
CM_ SG_ 2566569774 MG3LD_placeholder_BASE "Place Holder signal";
CM_ BO_ 2566569518 "CANMSG MG2LD (Motor/Generator 2 Lifetime Data) Contains data accumulated over the lifetime of this Motor/Generator.";
CM_ SG_ 2566569518 totalEnergyConsmpDS2_BASE "Accumulated total electric energy consumed by drive system 2 over the lifetime of the vehicle.";
CM_ SG_ 2566569518 totalEnergyGenDS2_BASE "Accumulated total electric energy generated by drive system 2 over the lifetime of the vehicle.";
CM_ BO_ 2566685991 "CANMSG FCHTRC (Fuel Cell Auxiliary Heater Control) The command message to the Fuel Cell Auxiliary Heater.";
CM_ SG_ 2566685991 FCHTRC_placeholder_BASE "Place Holder signal";
CM_ SG_ 2364575882 HVESSavbDisChargePower_BASE "The rate at which the High Voltage Energy Storage System can currently provide energy for propulsion or other uses. SAE-SPN: 5917";
CM_ SG_ 2364575882 HVESSavbChargePower_BASE "The rate at which the High Voltage Energy Storage System can currently receive energy from a regenerative or recharging system. SAE-SPN: 5918";
CM_ SG_ 2364575882 HVESSvoltageLevel_BASE "The voltage level of the High Voltage Energy Storage System. SAE-SPN: 5919";
CM_ SG_ 2364575882 HVESScurrent_BASE "The current in or out of the High Voltage Energy Storage System (or Pack 1 in systems with only one pack).";
CM_ BO_ 2566567975 "CANMSG EVSEDCS1 (EVSE DC Status 1)  This message is sent from the EVCC containing status information receved from the DC EVSE. &#x0A;&#x0A;If this PG is requested, e.g. using RQST, when no EVSE is connected then specific values or states are provided in e";
CM_ SG_ 2566567975 EVSE_DC_Charging_State_BASE "Overall State of the DC charging system";
CM_ SG_ 2566832167 serCID1_MC_VAR1 "Identification of component needing service.";
CM_ SG_ 2566832167 serCID2_MC_VAR1 "Identification of component needing service.";
CM_ SG_ 2566832167 serDelayCalendTiBasd_MC_VAR1 "The time in weeks until the next vehicle service inspection is required. A negative value is transmitted if the service&#x0A;inspection has been passed. The component that requires service is identified by the service component identification (see&#x0A;SP";
CM_ SG_ 2566832167 serCID3_MC_VAR1 "Identification of component needing service.";
CM_ SG_ 2566832167 serDelayOperatTiBasd_MC_VAR1 "The time in vehicle operational time until the next vehicle service inspection is required. A negative value is transmitted if&#x0A;the service inspection has been passed. The component that requires service is identified by the service component&#x0A;ide";
CM_ SG_ 2566832167 serviceDist_MC_VAR1 "The distance which can be traveled by the vehicle before the next service inspection is required.";
CM_ BO_ 2566819879 "CANMSG ETH (Engine Torque History)  PGN description:  NOTE The torque history PG is variable in length and may contain up to 125 torque history records. Each torque history record MUST BE 38 bytes in length. Any unused bytes must be 0xFF.  The last six by";
CM_ SG_ 2566819879 ETH_placeholder_BASE "Place Holder signal";
CM_ BO_ 2566569262 "CANMSG MG1LD (Motor/Generator 1 Lifetime Data) Contains data accumulated over the lifetime of this Motor/Generator.";
CM_ SG_ 2566569262 totalEnergyConsmpDS1_BASE "Accumulated total electric energy consumed by drive system 1 over the lifetime of the vehicle.";
CM_ SG_ 2566569262 totalEnergyGenDS1_BASE "Accumulated total electric energy generated by drive system 2 over the lifetime of the vehicle.";
CM_ BO_ 2600403765 "CANMSG CVM_53";
CM_ SG_ 2600403765 calcClutchTorq_BASE "Current torque transferred via the clutch, taking the following into account: Engine torque, frictional torque, auxiliary consumer torque, primary retarder torque, engine brake torque, mass moment of inertia of the engine.";
CM_ BO_ 2565933607 "High Voltage Energy Storage System Data 8 Data set 8 (electrical data) for High Voltage Energy Storage System (or Pack 1 in systems with only one pack).";
CM_ SG_ 2565933607 HVESSD8_placeholder_BASE "Place Holder signal";
CM_ BO_ 2565933863 "High Voltage Energy Storage System Data 9 Data set 9 (thermal) for High Voltage Energy Storage System (or Pack 1 in systems with only one pack).";
CM_ SG_ 2565933863 HVESSD9_placeholder_BASE "Place Holder signal";
CM_ BO_ 2566810919 "CANMSG HTR (Heater Information) ";
CM_ SG_ 2566810919 HTR_placeholder_BASE "Place Holder signal";
CM_ BO_ 2565903143 "CANMSG HVESSD4 (High Voltage Energy Storage System Data 4) Data set 4 (electrical data) for High Voltage Energy Storage System (or Pack 1 in systems with only one pack).";
CM_ SG_ 2565903143 HVESSchargeCapacity_BASE "The amount of unused electrical charge storage in the High Voltage Energy Storage System that is available to be filled by charging, i.e. how much empty space is remaining in the tank. See SPN 8206 (HVESS Charge Energy Capacity) for kilowatt-hours (kWh). ";
CM_ BO_ 2566688551 "alternate fuel, variant with Source Address 0x27";
CM_ SG_ 2566688551 gasFuelSupplyPress1extRange_BASE "Pressure of gaseous fuel supply to fuel metering device in systems where the pressure range defined for SPN 159 is not sufficient.";
CM_ BO_ 2565933351 "CANMSG HVESSTS1 (High Voltage Energy Storage System Thermal Management System Status 1) Collection of data the High Voltage Energy Storage System (or Pack 1 in systems with only one pack) Thermal Management System sends to the Hybrid Controller.";
CM_ SG_ 2565933351 activationStateHVHTES_BASE "Indicates if the HVH (High Voltage Heater) is activated or not.";
CM_ SG_ 2565933351 reqModeTempTES_BASE "Requested operation mode of the temperatur controll for the battery cooling/heating system.";
CM_ SG_ 2565933351 coolantEmptyLevelSwTES_BASE "The coolant level of the TES cooling circuit is below a critical level.";
CM_ BO_ 2600403788 "CANMSG CVM_70";
CM_ SG_ 2600403788 fwdCameraBlocked_BASE "blockage of forward camera (partial or full blockage detected)";
CM_ SG_ 2600403788 fwdRadarBlocked_BASE "blockage of forward radar";
CM_ SG_ 2600403788 transmissionOilTemperature_TCU "Temperature of the transmission lubricant.";
CM_ SG_ 2600403788 transmissionOilTemperature_WSK_B "transmissionOilTemperature; Temperature of the transmission lubricant.";
CM_ SG_ 2600403788 lockupClutchTemperature_BASE "Temperature of the elements of the torque converter lockup clutch. validRange: 0x0 to 0xFAF, see signal values; error Range: 0xFB0 to 0xFEF; not available range: 0xFF0 to 0xFFF;";
CM_ BO_ 2600403791 "CANMSG CVM_73";
CM_ SG_ 2600403791 axleLocation_wght_BASE "axleLocation; To identify to which of several similar devices (such as tires or fuel tanks) the information applies. The low order 4 bits represent a position number, counting left to right when facing in the direction of normal vehicle travel (forward). ";
CM_ SG_ 2600403791 reqDrivingProg_BASE "Driving program resulting from the driver control.";
CM_ SG_ 2600403791 rockingFreeActivationPerm_BASE "This signal is the activation release for the rock-free function to the driving range arbiter.";
CM_ SG_ 2600403791 vehicleRolling_BASE "Drive train status due to rolling function.";
CM_ SG_ 2600403791 vehicleRollingRobust_BASE "Drive train status due to rolling function, which compensates for the running time due to CAN and the gearbox reaction when closing the drive train.";
CM_ SG_ 2600403791 externalNeutralRequest_BASE "Indicates whether an external neutral request is active or not.";
CM_ SG_ 2600403791 lockupClutchFeedback_BASE "Feedback of the torque converter lockup clutch";
CM_ SG_ 2600403791 technicalAxleLoadExceededStatus_ "This signal indicates that the technical axle load has been exceeded (absolute value in kg). Value 0 kg corresponds to a non-existing exceedance. The axle position is specified via the additional information of the axleLocation.";
CM_ BO_ 2600403761 "CANMSG CVM_49";
CM_ SG_ 2600403761 railTempFiltered_BASE "Filtered rail temperature";
CM_ SG_ 2600403761 nozzleEqCalc_BASE "Injection based on Nozzle equation calculation";
CM_ SG_ 2600403761 actualInjEndPos_BASE "current end position of injection [°KW] (degrees of crank angle)";
CM_ SG_ 2600403761 icmSparkVoltCyl3_BASE "Spark voltage information cylinder 3 [kV]";
CM_ SG_ 2600403761 fuelActualInComb_BASE "Fuel mass in current combustion [mg/stroke]";
CM_ SG_ 2600403761 boostInjActive_BASE "boost injection active";
CM_ SG_ 2600403761 eoiAfterIvcActive_BASE "end of injection after intake valve closed active";
CM_ SG_ 2600403761 railPresGaseous_BASE "Fuel Rail pressure of gaseous fuels";
CM_ BO_ 2566843182 "CANMSG CI (Component Identification) PGN description: NOTE: The make, model, serial number and unit number fields in this message";
CM_ SG_ 2566843182 CI_placeholder_BASE "Place Holder signal";
CM_ BO_ 2583648885 "TX CAN message of the EVCC2.";
CM_ SG_ 2583648885 chrgngPlugLckErrSttChrgI2_BASE "Charging plug locking error state of the charging interface 2.";
CM_ SG_ 2583648885 extrnlChrgDrtngReason_BASE "Main reason for charging power and current derating.";
CM_ SG_ 2583648885 extrnlChrgEVSE_MACoctet1_BASE "This value is the first of 6 octets of the EVSE assigned MAC address. The address is separated into 6 bytes, 1 per octet of the address. Byte 1 is the first octet of the address. Byte 2 is the second and so forth. If the MAC address is not configured or n";
CM_ SG_ 2583648885 extrnlChrgEVSE_MACoctet2_BASE "This value is the second of 6 octets of the EVSE assigned MAC address. The address is separated into 6 bytes, 1 per octet of the address. Byte 1 is the first octet of the address. Byte 2 is the second and so forth. If the MAC address is not configured or ";
CM_ SG_ 2583648885 extrnlChrgEVSE_MACoctet3_BASE "This value is the third of 6 octets of the EVSE assigned MAC address. The address is separated into 6 bytes, 1 per octet of the address. Byte 1 is the first octet of the address. Byte 2 is the second and so forth. If the MAC address is not configured or n";
CM_ SG_ 2583648885 extrnlChrgEVSE_MACoctet4_BASE "This value is the fourth of 6 octets of the EVSE assigned MAC address. The address is separated into 6 bytes, 1 per octet of the address. Byte 1 is the first octet of the address. Byte 2 is the second and so forth. If the MAC address is not configured or ";
CM_ SG_ 2583648885 extrnlChrgEVSE_MACoctet5_BASE "This value is the fifth of 6 octets of the EVSE assigned MAC address. The address is separated into 6 bytes, 1 per octet of the address. Byte 1 is the first octet of the address. Byte 2 is the second and so forth. If the MAC address is not configured or n";
CM_ SG_ 2583648885 extrnlChrgEVSE_MACoctet6_BASE "This value is the sixth of 6 octets of the EVSE assigned MAC address. The address is separated into 6 bytes, 1 per octet of the address. Byte 1 is the first octet of the address. Byte 2 is the second and so forth. If the MAC address is not configured or n";
CM_ SG_ 2583648885 chrgngPlugLckErrSttChrgI_BASE "Charging plug locking error state of the charging interface 1.";
CM_ SG_ 2600454433 reqDispTJAdeactAuto_BASE "Request to display traffic jam assist beeing deactivated without driver action.";
CM_ SG_ 2600454433 reqDispTJAdeactMan_BASE "Request to display traffic jam assist beeing deactivated by driver action.";
CM_ SG_ 2600454433 TJAselected_BASE "Signal indicates that traffic jam assist is selected by the driver.";
CM_ SG_ 2600454433 reqDispTJAdeactAutoNS_BASE "Request to display traffic jam assist beeing deactivated without driver action (no sound).";
CM_ SG_ 2600454433 reqDispTCWblock_BASE "Request to display that TCW is not available due to the sensor blockage.";
CM_ SG_ 2600454433 reqDispTCWcalib_BASE "Request to display that TCW is not available due to the sensor not being aligned.";
CM_ SG_ 2600454433 reqDispTCWLCWlftBlock_BASE "Request to display that TCW/LCW is not available on the left side due to the sensor blockage.";
CM_ SG_ 2600454433 reqDispTCWLCWlftCalib_BASE "Request to display that TCW/LCW is not available on the left side due to the sensor not being aligned.";
CM_ SG_ 2600454433 reqDispTCWLCWlftPermFlt_BASE "Request to display that TCW/LCW is not available on the left side due to a general fault.";
CM_ SG_ 2600454433 reqDispTCWLCWlftTemp_BASE "Request to display that TCW/LCW is not available on the left side due to overheating of sensor or warning lamp";
CM_ SG_ 2600454433 reqDispTCWLCWrghBlock_BASE "Request to display that TCW/LCW is not available on the right side due to the sensor blockage.";
CM_ SG_ 2600454433 reqDispTCWLCWrghCalib_BASE "Request to display that TCW/LCW is not available on the right side due to the sensor not being aligned.";
CM_ SG_ 2600454433 reqDispTCWLCWrghPermFlt_BASE "Request to display that TCW/LCW is not available on the right side due to a general fault.";
CM_ SG_ 2600454433 reqDispTCWLCWrghTemp_BASE "Request to display that TCW/LCW is not available on the right side due to overheating of sensor or warning lamp";
CM_ SG_ 2600454433 reqDispTCWlht_BASE "Request to display that TCW is not available due a drive from left-hand traffic into right-hand traffic.";
CM_ SG_ 2600454433 reqDispTCWpermFlt_BASE "Request to display that TCW is not available due to a general fault.";
CM_ SG_ 2600454433 reqDispTCWrht_BASE "Request to display that TCW is not available due a drive from left-hand traffic into right-hand traffic.";
CM_ SG_ 2600454433 reqDispTCWtemp_BASE "Request to display that TCW is not available due to overheating of sensor or warning lamp";
CM_ SG_ 2600454433 dispBattMainSwOffReqPrvnt_BASE "Signal to display that the shut-off request for the electric battery main switch is prevented.";
CM_ SG_ 2600454433 dispActEmergencySwitch_BASE "Display emergency switch actuated.";
CM_ SG_ 2600454433 reqDispLKAmodeActive_BASE "Request to display LKA being in active mode. LKA is in active mode (or active) when the function is switched on and the conditions for being active are met. In this mode, the system continuously or discontinuously controls the steering system is gener";
CM_ SG_ 2600454433 stopStartDeselected_BASE "Signal indicates whether the driver has de-selected the stop-start operation.";
CM_ SG_ 2600454433 reqDispLKAmodeStandby_BASE "Request to display LKA being in standby mode. LKA is in standby mode when the function is switched on but the conditions (e.g. system operating conditions, deliberate action from driver) for being active are not all met. In this mode, the system is not ";
CM_ BO_ 2600454425 "CANMSG auxStatMC24";
CM_ SG_ 2600454425 couplingLockState_BASE "A signal describing fifth wheel coupling state calculated as per inputs from fifth wheel couplin sensors and vehicle drive state.";
CM_ SG_ 2600454425 interlockServiceDue_BASE "This signal descrribes whether the calibraation of the alcohol test equipment is due.";
CM_ SG_ 2600454425 tempLockout_BASE "This signal describes whether a temporary lockout in the alcohol interlock test equipment is present";
CM_ SG_ 2600454425 permaLockout_BASE "This signal describes whether alcohol test equipment is in a state of permanent lockout.";
CM_ SG_ 2600454425 ttAirSuspDeactivation_BASE "Internal signal for the control of the control lamp for air suspension suppression";
CM_ SG_ 2600454425 dispWrnElHySteer_BASE "Triggering of the messages in the cluster depending on the status of the electrohydraulic steering assistance";
CM_ SG_ 2600454425 DIGenableDistWrn_BASE "This signal shows the current status of the distance warning enabled setting.";
CM_ SG_ 2600454425 VASCsafeStateActive_BASE "This signal indicates if any safe state is active.";
CM_ SG_ 2600454425 reqCSSerrLmp_BASE "Request to indicate the airbag telltale because of deactivating clamp 15 while driving (velocity > 0kmh).";
CM_ SG_ 2600454425 dispTipperStateSideWall_BASE "display state of tipper side wall";
CM_ SG_ 2600454425 dispLimpHomeMode_BASE "The signal specifies the status of the Limp Out Of Danger Function in order to select the right display massage.";
CM_ SG_ 2600454425 tailGateRsp_BASE "signal tailGate feedback";
CM_ SG_ 2600454425 ureaLvlWarningDisp1_BASE "First Warning due to low urea level active";
CM_ SG_ 2600454425 VASCsupplyPressureLow_BASE "This signal indicates insufficient supply pressure for air suspension control system.";
CM_ SG_ 2600454425 auxStatMC24chkE2E_BASE "checksum of end-to-end communication protection";
CM_ SG_ 2600454425 alcolTestMessage_BASE "This signal is used to trigger messages to be displayed on the cluster via the reaction numbers.";
CM_ BO_ 2566535719 "Electric PTO Drive Engagement 1; Variant for CVM Msg ID FA3A27";
CM_ SG_ 2566535719 enableSwitchePTO1_BASE "Status of the operator's switch or other input on vehicle which indicates the desire for activating or engaging the ePTO equipment";
CM_ SG_ 2566535719 engageConsent_ePTO1_BASE "Indicates equipment controller's consent to activate or engage the high voltage ePTO. The vehicle controller may only apply high voltage to ePTO equipment when consent is given. Removal of consent initiates normal power down. Lack of consent may indicat";
CM_ SG_ 2566535719 engageStatus_ePTO1_BASE "Indicates whether electric power is applied to the ePTO equipment.";
CM_ SG_ 2566535719 emrgncyDeenSw_ePTO1_BASE "Initiates emergency shutdown procedure as appropriate to the application, which may include active discharge of ePTO bus.";
CM_ SG_ 2566535719 systemRdnss_ePTO1_BASE "Indicates availability of the power source to energize ePTO equipment or operational readiness of ePTO equipment to be energized";
CM_ SG_ 2566535719 errorIndicator_ePTO1_BASE "Signal to the operator that some ePTO error exists, such as failed to activate when requested";
CM_ SG_ 2566535719 activeDischargeRequest_ePTO1_BAS "active discharge requests";
CM_ SG_ 2566535719 ePTODE1_Count_BASE "The message counter is used to detect situations where the transmitting ECU malfunction repeats the same frame all the time. The receiver of the information may use the counter parameter to detect this situation. The transmitting device will increase the ";
CM_ BO_ 2351387943 "Primary Control Message from this instance of Inverter. Some examples of use would be for a hybrid or electric vehicle propulsion motor or generator.  Msg ID Param: 270027";
CM_ SG_ 2351387943 msgCRC8saeJ1939_BASE "CRC8 SAE J1939";
CM_ SG_ 2351387943 MG2ICLimReqOCM_BASE "This parameter provides a way to temporarily override limits that are being received by the inverter in other messages. It allows a specific type of limit to be transmitted at a high rate or at the same moment as the set point for synchronization purposes";
CM_ SG_ 2351387943 MG2ICmaxLimReq_BASE "The Maximum limit requested";
CM_ SG_ 2351387943 MG2ICminLimReq_BASE "The Minimum limit requested";
CM_ SG_ 2351387943 MG2ICsetpointModeReq_BASE "Requests the modes for this instance of the inverter.";
CM_ SG_ 2351387943 MG2ICsetpointReq_BASE "Requests the set point for this inverter.";
CM_ SG_ 2351387943 msgCNTsaeJ1939_BASE "The message counter is used to detect situations where the transmitting ECU malfunction repeats the same frame all the time. The receiver of the information may use the counter parameter to detect this situation. The transmitting device will increase the ";
CM_ BO_ 2600403758 "CANMSG CVM_46";
CM_ SG_ 2600403758 trendDataCVMvariant_BASE "Variant for the set of signals provided by CVM for acquiring trenddata in CM4.";
CM_ SG_ 2600403758 trendDataCVMminorVersion_BASE "Minor version number for the set of signals provided by CVM for acquiring trenddata in CM4.";
CM_ SG_ 2600403758 trendDataCVMmajorVersion_BASE "Major version number for the set of signals provided by CVM for acquiring trenddata in CM4.";
CM_ BO_ 2600454438 "CANMSG auxStatMC37";
CM_ SG_ 2600454438 extrnlChrgStatus_BASE "Status of external charging.";
CM_ SG_ 2600454438 extrnlChrgFlapStateChrgI1_BASE "State of the flap of the charging interface 1.";
CM_ SG_ 2600454438 actStateChrgPlug2Disp_BASE "State of the plug connector of the conductive charging interface 2 for display purpose.";
CM_ SG_ 2600454438 actStateChrgPlugDisp_BASE "state of the plug connector of the conductive charging interface for display purpose.";
CM_ SG_ 2600454438 extrnlChrgTargetSOC_HR_BASE "Requested SOC of the traction energy storage.";
CM_ SG_ 2600454438 extrnlChrgTrgtDrvngRngDisp_BASE "The signal indicates the target driving range.";
CM_ SG_ 2600454438 extrnlChrgErrorType_BASE "The signal indicates the active error type of the charging system. Only highest prio error communicated.";
CM_ SG_ 2600454438 extrnlChrgHoldInfImmedDisp_BASE "The signal displays if the holding period for immediate charging is selected to be infinite.";
CM_ SG_ 2600454438 extrnlChrgModeDisp_BASE "The signal indicates the current charging mode.";
CM_ SG_ 2600454438 energyManagmtMenuReq_BASE "Request for activation and selection of the intial menu tab of the energy management menu in the cluster. Remark: This signal is the functional trigger for wakeup of the cluster.";
CM_ SG_ 2600454438 coolantTempCCC_BASE "Coolant temperature for temperature display";
CM_ SG_ 2600454438 extrnlChrgOTActrlDisp_BASE "The signal indicates if control of the charging settings via OTA (over the air) is selected.";
CM_ SG_ 2600454438 extrnlChrgFlapStateChrgI2_BASE "State of the flap of the charging interface 2.";
BA_DEF_ SG_  "SigType" ENUM  "DEFAULT","RANGE","RANGESIGNED","ASCII","DISCRETE","CONTROL","REFERENCEPGN","DTC","STRINGDELIMITER","STRINGLENGTH","STRINGLENGTHCONTROL","vector_leerstring";
BA_DEF_ SG_  "GenSigSendType" ENUM  "Cyclic","OnWrite","reserved","OnChange","reserved","reserved","reserved","NoSigSendType";
BA_DEF_ BO_  "VFrameFormat" ENUM  "CAN Standard","CAN Extended","reserved","J1939PG","reserved","reserved","reserved","reserved","reserved","reserved","reserved","reserved","reserved","reserved","StandardCAN_FD","ExtendedCAN_FD","vector_leerstring";
BA_DEF_ BO_  "GenMsgSendType" ENUM  "cyclic","reserved","cyclicIfActive","reserved","reserved","reserved","reserved","reserved","noMsgSendType","vector_leerstring";
BA_DEF_ BO_  "GenMsgCycleTime" INT 0 3600000;
BA_DEF_ BO_  "GenMsgStartDelayTime" INT 0 0;
BA_DEF_ BO_  "GenMsgILSupport" ENUM  "No","Yes","vector_leerstring";
BA_DEF_ SG_  "SystemSignalLongSymbol" STRING ;
BA_DEF_ BO_  "SystemMessageLongSymbol" STRING ;
BA_DEF_DEF_  "SigType" "DEFAULT";
BA_DEF_DEF_  "VFrameFormat" "CAN Extended";
BA_DEF_DEF_  "GenMsgSendType" "noMsgSendType";
BA_DEF_DEF_  "GenMsgCycleTime" 1000;
BA_DEF_DEF_  "GenMsgStartDelayTime" 0;
BA_DEF_DEF_  "GenMsgILSupport" "Yes";
BA_DEF_DEF_  "SystemSignalLongSymbol" "";
BA_DEF_DEF_  "GenSigSendType" "NoSigSendType";

BA_ "GenMsgSendType" BO_ 2566807232 0;

BA_ "GenMsgILSupport" BO_ 2365571367 0;
BA_ "GenMsgSendType" BO_ 2365571367 0;
BA_ "GenMsgCycleTime" BO_ 2365571367 100;

BA_ "GenMsgILSupport" BO_ 2364577418 0;
BA_ "GenMsgCycleTime" BO_ 2364577418 100;

BA_ "GenMsgILSupport" BO_ 2600403782 0;

BA_ "GenMsgILSupport" BO_ 2600454405 0;
BA_ "GenMsgCycleTime" BO_ 2600454405 0;

BA_ "GenMsgSendType" BO_ 2566842927 0;
BA_ "GenMsgCycleTime" BO_ 2566842927 100;

BA_ "GenMsgILSupport" BO_ 2600403784 0;

BA_ "GenMsgILSupport" BO_ 2600403785 0;

BA_ "GenMsgILSupport" BO_ 2566898215 0;
BA_ "GenMsgSendType" BO_ 2566898215 0;
BA_ "GenMsgCycleTime" BO_ 2566898215 100;

BA_ "GenMsgILSupport" BO_ 2566898182 0;
BA_ "GenMsgSendType" BO_ 2566898182 0;
BA_ "GenMsgCycleTime" BO_ 2566898182 100;

BA_ "GenMsgILSupport" BO_ 2566848295 0;
BA_ "GenMsgCycleTime" BO_ 2566848295 10000;

BA_ "GenMsgILSupport" BO_ 2600403787 0;

BA_ "GenMsgILSupport" BO_ 2600454439 0;
BA_ "GenMsgSendType" BO_ 2600454439 0;

BA_ "GenMsgILSupport" BO_ 2600403759 0;
BA_ "GenMsgSendType" BO_ 2600403759 0;

BA_ "GenMsgSendType" BO_ 2566827568 0;
BA_ "VFrameFormat" BO_ 2566827568 3;

BA_ "GenMsgSendType" BO_ 2600407434 0;

BA_ "GenMsgILSupport" BO_ 2566841088 0;
BA_ "GenMsgSendType" BO_ 2566841088 0;
BA_ "GenMsgCycleTime" BO_ 2566841088 5000;
BA_ "VFrameFormat" BO_ 2566841088 3;

BA_ "GenMsgILSupport" BO_ 2600403768 0;

BA_ "GenMsgILSupport" BO_ 2600403769 0;

BA_ "GenMsgILSupport" BO_ 2600403766 0;

BA_ "GenMsgILSupport" BO_ 2600403777 0;
BA_ "GenMsgSendType" BO_ 2600403777 0;
BA_ "GenMsgCycleTime" BO_ 2600403777 100;

BA_ "GenMsgILSupport" BO_ 2600403776 0;
BA_ "GenMsgSendType" BO_ 2600403776 0;
BA_ "GenMsgCycleTime" BO_ 2600403776 50;

BA_ "GenMsgILSupport" BO_ 2600403764 0;
BA_ "GenMsgCycleTime" BO_ 2600403764 100;

BA_ "GenMsgILSupport" BO_ 2600403786 0;

BA_ "GenMsgILSupport" BO_ 2600403780 0;

BA_ "GenMsgILSupport" BO_ 2600403783 0;

BA_ "GenMsgILSupport" BO_ 2600403779 0;

BA_ "GenMsgILSupport" BO_ 2600403767 0;

BA_ "GenMsgILSupport" BO_ 2600403778 0;

BA_ "GenMsgILSupport" BO_ 2667525635 0;
BA_ "GenMsgCycleTime" BO_ 2667525635 5000;

BA_ "GenMsgILSupport" BO_ 2600403760 0;

BA_ "GenMsgILSupport" BO_ 2566080807 0;
BA_ "GenMsgSendType" BO_ 2566080807 0;
BA_ "GenMsgCycleTime" BO_ 2566080807 100;

BA_ "GenMsgILSupport" BO_ 2566675782 0;
BA_ "GenMsgSendType" BO_ 2566675782 0;
BA_ "GenMsgCycleTime" BO_ 2566675782 10000;
BA_ "VFrameFormat" BO_ 2566675782 3;

BA_ "GenMsgILSupport" BO_ 2566678922 0;
BA_ "GenMsgCycleTime" BO_ 2566678922 10000;
BA_ "VFrameFormat" BO_ 2566678922 3;

BA_ "GenMsgSendType" BO_ 2566827815 0;

BA_ "GenMsgSendType" BO_ 2565865488 0;
BA_ "GenMsgCycleTime" BO_ 2565865488 100;

BA_ "GenMsgSendType" BO_ 2566845479 0;
BA_ "GenMsgCycleTime" BO_ 2566845479 500;
BA_ "VFrameFormat" BO_ 2566845479 3;

BA_ "GenMsgSendType" BO_ 2565866755 0;
BA_ "GenMsgCycleTime" BO_ 2565866755 100;

BA_ "GenMsgILSupport" BO_ 2566774823 0;
BA_ "GenMsgSendType" BO_ 2566774823 0;

BA_ "GenMsgILSupport" BO_ 2566687271 0;
BA_ "GenMsgSendType" BO_ 2566687271 0;

BA_ "GenMsgILSupport" BO_ 2566575143 0;
BA_ "GenMsgSendType" BO_ 2566575143 0;

BA_ "GenMsgILSupport" BO_ 2566686247 0;
BA_ "GenMsgSendType" BO_ 2566686247 0;

BA_ "GenMsgILSupport" BO_ 2565902887 0;
BA_ "GenMsgSendType" BO_ 2565902887 0;

BA_ "GenMsgILSupport" BO_ 2566775079 0;
BA_ "GenMsgSendType" BO_ 2566775079 0;

BA_ "GenMsgILSupport" BO_ 2566676038 0;
BA_ "GenMsgSendType" BO_ 2566676038 0;
BA_ "GenMsgCycleTime" BO_ 2566676038 10000;
BA_ "VFrameFormat" BO_ 2566676038 3;

BA_ "GenMsgILSupport" BO_ 2566701706 0;
BA_ "VFrameFormat" BO_ 2566701706 3;

BA_ "GenMsgILSupport" BO_ 2600403798 0;

BA_ "GenMsgILSupport" BO_ 2600403790 0;
BA_ "GenMsgSendType" BO_ 2600403790 0;
BA_ "GenMsgCycleTime" BO_ 2600403790 50;

BA_ "GenMsgILSupport" BO_ 2600403794 0;

BA_ "GenMsgILSupport" BO_ 2600403795 0;

BA_ "GenMsgILSupport" BO_ 2600403797 0;

BA_ "GenMsgILSupport" BO_ 2600403796 0;

BA_ "GenMsgILSupport" BO_ 2600403789 0;

BA_ "GenMsgILSupport" BO_ 2600403792 0;

BA_ "GenMsgILSupport" BO_ 2600403793 0;

BA_ "GenMsgILSupport" BO_ 2600407303 0;
BA_ "GenMsgSendType" BO_ 2600407303 0;
BA_ "VFrameFormat" BO_ 2600407303 3;

BA_ "GenMsgSendType" BO_ 2566811687 0;
BA_ "GenMsgCycleTime" BO_ 2566811687 3000;
BA_ "GenMsgStartDelayTime" BO_ 2566811687 80;

BA_ "GenMsgILSupport" BO_ 2600407296 0;
BA_ "GenMsgSendType" BO_ 2600407296 0;
BA_ "VFrameFormat" BO_ 2600407296 3;

BA_ "GenMsgILSupport" BO_ 2600403740 0;
BA_ "GenMsgSendType" BO_ 2600403740 0;
BA_ "GenMsgCycleTime" BO_ 2600403740 100;

BA_ "GenMsgILSupport" BO_ 2566847015 0;
BA_ "GenMsgSendType" BO_ 2566847015 0;

BA_ "GenMsgILSupport" BO_ 2566660647 0;
BA_ "GenMsgSendType" BO_ 2566660647 0;
BA_ "GenMsgCycleTime" BO_ 2566660647 10000;

BA_ "GenMsgSendType" BO_ 2566840064 0;
BA_ "GenMsgCycleTime" BO_ 2566840064 100;

BA_ "GenMsgSendType" BO_ 2565865513 0;
BA_ "GenMsgCycleTime" BO_ 2565865513 100;
BA_ "GenMsgStartDelayTime" BO_ 2565865513 50;

BA_ "GenMsgILSupport" BO_ 2551906343 0;
BA_ "GenMsgSendType" BO_ 2551906343 0;
BA_ "VFrameFormat" BO_ 2551906343 3;

BA_ "GenMsgILSupport" BO_ 2565902631 0;
BA_ "GenMsgSendType" BO_ 2565902631 0;
BA_ "GenMsgCycleTime" BO_ 2565902631 20;

BA_ "GenMsgILSupport" BO_ 2566687015 0;
BA_ "GenMsgSendType" BO_ 2566687015 0;

BA_ "GenMsgILSupport" BO_ 2566570030 0;
BA_ "GenMsgSendType" BO_ 2566570030 0;
BA_ "GenMsgCycleTime" BO_ 2566570030 10000;
BA_ "VFrameFormat" BO_ 2566570030 3;

BA_ "GenMsgILSupport" BO_ 2566569774 0;
BA_ "GenMsgSendType" BO_ 2566569774 0;
BA_ "GenMsgCycleTime" BO_ 2566569774 10000;
BA_ "VFrameFormat" BO_ 2566569774 3;

BA_ "GenMsgILSupport" BO_ 2566569518 0;
BA_ "GenMsgSendType" BO_ 2566569518 0;
BA_ "GenMsgCycleTime" BO_ 2566569518 10000;
BA_ "VFrameFormat" BO_ 2566569518 3;

BA_ "GenMsgILSupport" BO_ 2566685991 0;
BA_ "GenMsgSendType" BO_ 2566685991 0;

BA_ "GenMsgILSupport" BO_ 2364575882 0;
BA_ "GenMsgSendType" BO_ 2364575882 0;
BA_ "GenMsgCycleTime" BO_ 2364575882 100;

BA_ "GenMsgILSupport" BO_ 2566567975 0;
BA_ "GenMsgSendType" BO_ 2566567975 0;

BA_ "GenMsgSendType" BO_ 2566832167 0;
BA_ "GenMsgStartDelayTime" BO_ 2566832167 80;

BA_ "GenMsgILSupport" BO_ 2566819879 0;
BA_ "GenMsgSendType" BO_ 2566819879 0;
BA_ "GenMsgCycleTime" BO_ 2566819879 10000;
BA_ "VFrameFormat" BO_ 2566819879 3;

BA_ "GenMsgILSupport" BO_ 2566569262 0;
BA_ "GenMsgSendType" BO_ 2566569262 0;
BA_ "GenMsgCycleTime" BO_ 2566569262 10000;
BA_ "VFrameFormat" BO_ 2566569262 3;

BA_ "GenMsgILSupport" BO_ 2600403765 0;

BA_ "GenMsgILSupport" BO_ 2565933607 0;
BA_ "GenMsgSendType" BO_ 2565933607 0;
BA_ "GenMsgCycleTime" BO_ 2565933607 100;

BA_ "GenMsgILSupport" BO_ 2565933863 0;
BA_ "GenMsgSendType" BO_ 2565933863 0;
BA_ "GenMsgCycleTime" BO_ 2565933863 100;

BA_ "GenMsgILSupport" BO_ 2566810919 0;
BA_ "GenMsgSendType" BO_ 2566810919 0;

BA_ "GenMsgILSupport" BO_ 2565903143 0;
BA_ "GenMsgSendType" BO_ 2565903143 0;

BA_ "GenMsgILSupport" BO_ 2566688551 0;
BA_ "GenMsgSendType" BO_ 2566688551 0;

BA_ "GenMsgILSupport" BO_ 2565933351 0;
BA_ "GenMsgSendType" BO_ 2565933351 0;

BA_ "GenMsgILSupport" BO_ 2600403788 0;
BA_ "GenMsgSendType" BO_ 2600403788 0;

BA_ "GenMsgILSupport" BO_ 2600403791 0;
BA_ "GenMsgSendType" BO_ 2600403791 0;
BA_ "GenMsgCycleTime" BO_ 2600403791 100;

BA_ "GenMsgILSupport" BO_ 2600403761 0;

BA_ "GenMsgILSupport" BO_ 2566843182 0;
BA_ "GenMsgSendType" BO_ 2566843182 0;
BA_ "GenMsgCycleTime" BO_ 2566843182 10000;
BA_ "VFrameFormat" BO_ 2566843182 3;

BA_ "GenMsgILSupport" BO_ 2583648885 0;
BA_ "GenMsgSendType" BO_ 2583648885 0;

BA_ "GenMsgILSupport" BO_ 2600454433 0;
BA_ "GenMsgCycleTime" BO_ 2600454433 0;

BA_ "GenMsgILSupport" BO_ 2600454425 0;
BA_ "GenMsgCycleTime" BO_ 2600454425 0;

BA_ "GenMsgILSupport" BO_ 2566535719 0;
BA_ "GenMsgSendType" BO_ 2566535719 0;
BA_ "GenMsgCycleTime" BO_ 2566535719 100;

BA_ "GenMsgILSupport" BO_ 2351387943 0;
BA_ "GenMsgSendType" BO_ 2351387943 0;
BA_ "GenMsgCycleTime" BO_ 2351387943 100;

BA_ "GenMsgILSupport" BO_ 2600403758 0;
BA_ "GenMsgSendType" BO_ 2600403758 0;

BA_ "GenMsgILSupport" BO_ 2600454438 0;
BA_ "SystemSignalLongSymbol" SG_ 2566807232 tyreWheelIdentification_T2_TO_T1 "tyreWheelIdentification_T2_TO_T1TRUCK";
BA_ "SystemSignalLongSymbol" SG_ 2566807232 tirePressureThresholdDetection_T "tirePressureThresholdDetection_T2_TO_T1TRUCK";
BA_ "SystemSignalLongSymbol" SG_ 2566807232 tireModulePowerSupply_T2_TO_T1TR "tireModulePowerSupply_T2_TO_T1TRUCK";
BA_ "SystemSignalLongSymbol" SG_ 2600403784 speedDependentLvlActivationData_ "speedDependentLvlActivationData_BASE";
BA_ "SystemSignalLongSymbol" SG_ 2566848295 fuelSupplyEstimatedRemainingDist "fuelSupplyEstimatedRemainingDist_BASE";
BA_ "SystemSignalLongSymbol" SG_ 2600403787 transmissionInputShaftSpeed_BASI "transmissionInputShaftSpeed_BASIS";
BA_ "SystemSignalLongSymbol" SG_ 2600403787 transmissionOutputShaftSpeed_BAS "transmissionOutputShaftSpeed_BASIS";
BA_ "SystemSignalLongSymbol" SG_ 2566827568 serviceBrakeAirPressureCircuit1_ "serviceBrakeAirPressureCircuit1_BASIS";
BA_ "SystemSignalLongSymbol" SG_ 2566827568 serviceBrakeAirPressureCircuit2_ "serviceBrakeAirPressureCircuit2_BASIS";
BA_ "SystemSignalLongSymbol" SG_ 2566827568 auxiliaryEquipmentSupplyPressure "auxiliaryEquipmentSupplyPressure_BASIS";
BA_ "SystemSignalLongSymbol" SG_ 2566827568 airSuspensionSupplyPressure_BASI "airSuspensionSupplyPressure_BASIS";
BA_ "SystemSignalLongSymbol" SG_ 2566841088 engineReferenceEngineTorque_BASI "engineReferenceEngineTorque_BASIS";
BA_ "SystemSignalLongSymbol" SG_ 2600403777 MONd_safetyReactionDrivetrain_BA "MONd_safetyReactionDrivetrain_BASE";
BA_ "SystemSignalLongSymbol" SG_ 2600403786 technicalAxleLoadExceededStatus_ "technicalAxleLoadExceededStatus_BASE";
BA_ "SystemSignalLongSymbol" SG_ 2600403780 brakePressHRrearAxle1rightW_BASI "brakePressHRrearAxle1rightW_BASIS";
BA_ "SystemSignalLongSymbol" SG_ 2600403780 brakePressHRrearAxle2rightW_BASI "brakePressHRrearAxle2rightW_BASIS";
BA_ "SystemSignalLongSymbol" SG_ 2600403780 brakePressHRfrontAxleRightW_BASI "brakePressHRfrontAxleRightW_BASIS";
BA_ "SystemSignalLongSymbol" SG_ 2565865488 driversDemandRetarderPercTorque_ "driversDemandRetarderPercTorque_RD";
BA_ "SystemSignalLongSymbol" SG_ 2566845479 tirePressureThresholdDetection_B "tirePressureThresholdDetection_BASIS";
BA_ "SystemSignalLongSymbol" SG_ 2565866755 transmissionActualGearRatio_BASI "transmissionActualGearRatio_BASIS";
BA_ "SystemSignalLongSymbol" SG_ 2566775079 AirConditionerCompressorStatus_B "AirConditionerCompressorStatus_BASE";
BA_ "SystemSignalLongSymbol" SG_ 2566811687 grossCombinationVehicleWeight_VA "grossCombinationVehicleWeight_VAR2_MC";
BA_ "SystemSignalLongSymbol" SG_ 2566840064 nominalFrictionPercentTorque_BAS "nominalFrictionPercentTorque_BASIS";
BA_ "SystemSignalLongSymbol" SG_ 2566840064 estimatedEngineParasiticLossesPe "estimatedEngineParasiticLossesPercentTorque_BASIS";
BA_ "SystemSignalLongSymbol" SG_ 2600403788 transmissionOilTemperature_WSK_B "transmissionOilTemperature_WSK_BASE";
BA_ "SystemSignalLongSymbol" SG_ 2600403791 technicalAxleLoadExceededStatus_ "technicalAxleLoadExceededStatus_BASE";
BA_ "SystemSignalLongSymbol" SG_ 2566535719 activeDischargeRequest_ePTO1_BAS "activeDischargeRequest_ePTO1_BASE";
BA_ "GenSigSendType" SG_ 2566807232 tyreWheelIdentification_T2_TO_T1 0;
BA_ "GenSigSendType" SG_ 2566807232 tireAirLeakageRate_T2_TO_T1TRUCK 0;
BA_ "GenSigSendType" SG_ 2566807232 tirePressureThresholdDetection_T 0;
BA_ "GenSigSendType" SG_ 2566807232 tireModulePowerSupply_T2_TO_T1TR 0;
BA_ "GenSigSendType" SG_ 2566807232 identificationDataIndex_BASE 0;
BA_ "GenSigSendType" SG_ 2566807232 identificationDataContent_BASE 0;
BA_ "GenSigSendType" SG_ 2566807232 tireTemperature_T2_TO_T1TRUCK 0;
BA_ "GenSigSendType" SG_ 2365571367 highVoltSysModeAct_BASE 0;
BA_ "GenSigSendType" SG_ 2365571367 remDrvRangeWarning_BASE 0;
BA_ "GenSigSendType" SG_ 2365571367 BattSysCritOtWarn_BASE 0;
BA_ "GenSigSendType" SG_ 2365571367 PelOutInFlowTES_BASE 0;
BA_ "GenSigSendType" SG_ 2365571367 ePTOPowerDisp_BASE 0;
BA_ "GenSigSendType" SG_ 2365571367 battInstEngy_BASE 0;
BA_ "GenSigSendType" SG_ 2365571367 redVehAcousticModeReq_BASE 0;
BA_ "GenSigSendType" SG_ 2364577418 HVESSpassiveIsoTestStatus_BASE 0;
BA_ "GenSigSendType" SG_ 2364577418 HVESSintrnlChrgrState_BASE 0;
BA_ "GenSigSendType" SG_ 2364577418 HVESSnumberOfHVESPready_BASE 0;
BA_ "GenSigSendType" SG_ 2600403782 tscSAarbReqRE_BASE 0;
BA_ "GenSigSendType" SG_ 2600403782 tscSAarbReqRD_BASE 0;
BA_ "GenSigSendType" SG_ 2600403782 tscSAarbReqRX_BASE 0;
BA_ "GenSigSendType" SG_ 2600403782 acclCtrlActuatorMode_BASE 0;
BA_ "GenSigSendType" SG_ 2600403782 CCreqTscOcmSek01_BASE 0;
BA_ "GenSigSendType" SG_ 2600403782 CCreqTscOcmSek00_BASE 0;
BA_ "GenSigSendType" SG_ 2600403782 highVoltageActv_BASE 0;
BA_ "GenSigSendType" SG_ 2600454405 pressAirWarnCirc1_BASE 3;
BA_ "GenSigSendType" SG_ 2600454405 pressAirWarnCirc2_BASE 3;
BA_ "GenSigSendType" SG_ 2600454405 pressAirWarnCirc3_BASE 3;
BA_ "GenSigSendType" SG_ 2600454405 pressAirWarnCirc4_BASE 3;
BA_ "GenSigSendType" SG_ 2600454405 diffLockReq_BASE 3;
BA_ "GenSigSendType" SG_ 2600454405 diffCentralLockReq_BASE 3;
BA_ "GenSigSendType" SG_ 2566842927 axleLocation_VEHWE_VAR2_SSC1 0;
BA_ "GenSigSendType" SG_ 2566842927 axleWeight_VEHWE_VAR2_SSC1 0;
BA_ "GenSigSendType" SG_ 2600403784 kneelingActivationData_BASE 0;
BA_ "GenSigSendType" SG_ 2600403784 NN2ActivationData_BASE 0;
BA_ "GenSigSendType" SG_ 2600403784 NN3ActivationData_BASE 0;
BA_ "GenSigSendType" SG_ 2600403784 speedDependentLvlActivationData_ 0;
BA_ "GenSigSendType" SG_ 2600403785 valveActivationDataSPA1_BASE 0;
BA_ "GenSigSendType" SG_ 2600403785 valveActivationDataSPA2_BASE 0;
BA_ "GenSigSendType" SG_ 2600403785 valveActivationDataSPA3_BASE 0;
BA_ "GenSigSendType" SG_ 2600403785 valveActivationDataSPA4_BASE 0;
BA_ "GenSigSendType" SG_ 2566898215 pssblRngExt_ePTO_BASE 0;
BA_ "GenSigSendType" SG_ 2566898215 currPwrCnsmptEPTO_BASE 0;
BA_ "GenSigSendType" SG_ 2566898215 remOperatingTime_BASE 0;
BA_ "GenSigSendType" SG_ 2566898215 sMeanPowerTES_BASE 0;
BA_ "GenSigSendType" SG_ 2566898182 tourDataSetMux_BASE 0;
BA_ "GenSigSendType" SG_ 2566898182 energyConsumptionEPTO_BASE 0;
BA_ "GenSigSendType" SG_ 2566848295 waterInFuelIndicator_BASE 0;
BA_ "GenSigSendType" SG_ 2566848295 fuelSupplyEstimatedRemainingDist 0;
BA_ "GenSigSendType" SG_ 2600403787 steeringWheelAngle_BASIS 0;
BA_ "GenSigSendType" SG_ 2600403787 engineSpeed_BASIS 0;
BA_ "GenSigSendType" SG_ 2600403787 transmissionInputShaftSpeed_BASI 0;
BA_ "GenSigSendType" SG_ 2600403787 transmissionOutputShaftSpeed_BAS 0;
BA_ "GenSigSendType" SG_ 2600454439 highVoltSysModeAct_BASE 0;
BA_ "GenSigSendType" SG_ 2600454439 vehParkingMode_BASE 0;
BA_ "GenSigSendType" SG_ 2600454439 remDrvRangeWarning_BASE 0;
BA_ "GenSigSendType" SG_ 2600454439 stateOfChargeTES_BASE 0;
BA_ "GenSigSendType" SG_ 2600454439 dispFuelVolume_BASE 0;
BA_ "GenSigSendType" SG_ 2600454439 ePTOPowerDisp_BASE 0;
BA_ "GenSigSendType" SG_ 2600454439 remDrivingRangeEnergy_BASE 0;
BA_ "GenSigSendType" SG_ 2600454439 warningSOCoverflowDisp_BASE 0;
BA_ "GenSigSendType" SG_ 2600454439 LimpHomeMode_BASE 0;
BA_ "GenSigSendType" SG_ 2600403759 estCorrSpdTrjConfiAdapt_BASE 0;
BA_ "GenSigSendType" SG_ 2600403759 estCorrSpdClsAdapt_BASE 0;
BA_ "GenSigSendType" SG_ 2600403759 estCorrSpdTrlAdapt_BASE 0;
BA_ "GenSigSendType" SG_ 2600403759 vehSpd2ShaftSpdRatioAdapt_BASE 0;
BA_ "GenSigSendType" SG_ 2600403759 equSlopeDrvResistAdapt_BASE 0;
BA_ "GenSigSendType" SG_ 2600403759 estAvgHVpower24V_BASE 0;
BA_ "GenSigSendType" SG_ 2600403759 estCorrSpdTrjAdapt_BASE 0;
BA_ "GenSigSendType" SG_ 2566827568 pneumaticSupplyPressure_BASIS 0;
BA_ "GenSigSendType" SG_ 2566827568 serviceBrakeAirPressureCircuit1_ 0;
BA_ "GenSigSendType" SG_ 2566827568 serviceBrakeAirPressureCircuit2_ 0;
BA_ "GenSigSendType" SG_ 2566827568 auxiliaryEquipmentSupplyPressure 0;
BA_ "GenSigSendType" SG_ 2566827568 airSuspensionSupplyPressure_BASI 0;
BA_ "GenSigSendType" SG_ 2566827568 airCompressorStatus_BASE 0;
BA_ "GenSigSendType" SG_ 2566827568 parkingTrailerAirPressure_BASIS 0;
BA_ "GenSigSendType" SG_ 2600407434 actElHVpowHVAC_BASE 0;
BA_ "GenSigSendType" SG_ 2600407434 PelOutInFlowTES_BASE 0;
BA_ "GenSigSendType" SG_ 2600407434 stCombHeat_BASE 0;
BA_ "GenSigSendType" SG_ 2600407434 actStatePreCond_BASE 0;
BA_ "GenSigSendType" SG_ 2600407434 thermalAlertPredctnTES_BASE 0;
BA_ "GenSigSendType" SG_ 2600407434 actElPowAirComp_BASE 0;
BA_ "GenSigSendType" SG_ 2600407434 actModeHVAC1_BASE 0;
BA_ "GenSigSendType" SG_ 2600407434 washerFluidLvlLow_BASE 0;
BA_ "GenSigSendType" SG_ 2600407434 actElPowPwrtrn_BASE 0;
BA_ "GenSigSendType" SG_ 2566841088 engineReferenceEngineTorque_BASI 0;
BA_ "GenSigSendType" SG_ 2566841088 maxMomEngOverSpeedPoint7_BASIS 0;
BA_ "GenSigSendType" SG_ 2600403768 fuelConsptDriveCycle_BASE 0;
BA_ "GenSigSendType" SG_ 2600403768 pitchAngleTruckAndTrailer_BASE 0;
BA_ "GenSigSendType" SG_ 2600403768 Mgu3GeneratingCurrentLimit_BASE 0;
BA_ "GenSigSendType" SG_ 2600403769 activeTimeTSI_TD_BASE 0;
BA_ "GenSigSendType" SG_ 2600403769 clutchEnergy_BASE 0;
BA_ "GenSigSendType" SG_ 2600403769 arbGearReqSA_BASE 0;
BA_ "GenSigSendType" SG_ 2600403769 reqAirComp_BASE 0;
BA_ "GenSigSendType" SG_ 2600403769 setAirComp_BASE 0;
BA_ "GenSigSendType" SG_ 2600403769 reqDrivingDir1_BASE 0;
BA_ "GenSigSendType" SG_ 2600403766 vehSpdEnhanced_BASE 0;
BA_ "GenSigSendType" SG_ 2600403766 commandTorqueCCDI_BASE 0;
BA_ "GenSigSendType" SG_ 2600403766 Mgu3EstimatedShaftTorque_BASE 0;
BA_ "GenSigSendType" SG_ 2600403777 transCurRange_BASE 0;
BA_ "GenSigSendType" SG_ 2600403777 transReqRange_BASE 0;
BA_ "GenSigSendType" SG_ 2600403777 engineOperatingState_BASE 0;
BA_ "GenSigSendType" SG_ 2600403777 modeAG_BASE 0;
BA_ "GenSigSendType" SG_ 2600403777 clutchFrictionActive_BASE 0;
BA_ "GenSigSendType" SG_ 2600403777 engStart_BASE 0;
BA_ "GenSigSendType" SG_ 2600403777 increaseGear_BASE 0;
BA_ "GenSigSendType" SG_ 2600403777 MONd_safetyReactionDrivetrain_BA 0;
BA_ "GenSigSendType" SG_ 2600403777 DrvOffAgnstCurDrvDirActv_BASE 0;
BA_ "GenSigSendType" SG_ 2600403777 engineExhaustGasTemperature_VAR1 0;
BA_ "GenSigSendType" SG_ 2600403777 manualModeRequest_BASE 0;
BA_ "GenSigSendType" SG_ 2600403777 manualRetarderControl_BASIS 0;
BA_ "GenSigSendType" SG_ 2600403777 decreaseGear_BASE 0;
BA_ "GenSigSendType" SG_ 2600403777 displayMonErrTorqueSpeedReq_BASE 0;
BA_ "GenSigSendType" SG_ 2600403776 vehSpdFrontAxle_BASE 0;
BA_ "GenSigSendType" SG_ 2600403776 EmgcyBrkSysStatePlausi_BASE 0;
BA_ "GenSigSendType" SG_ 2600403776 EBAarbObjMotionType_BASE 0;
BA_ "GenSigSendType" SG_ 2600403776 EBAsysEngagDeltaVehVel_BASE 0;
BA_ "GenSigSendType" SG_ 2600403776 XBRextAccelDemEBA1_BASE 0;
BA_ "GenSigSendType" SG_ 2600403776 actualRange_BASE 0;
BA_ "GenSigSendType" SG_ 2600403776 vehicleDriveState_BASE 0;
BA_ "GenSigSendType" SG_ 2600403776 engState_BASE 0;
BA_ "GenSigSendType" SG_ 2600403776 EBAsysEngagTiDuration_BASE 0;
BA_ "GenSigSendType" SG_ 2600403764 ESPcontrActv_BASE 0;
BA_ "GenSigSendType" SG_ 2600403764 shiftInProcess_BASIS 0;
BA_ "GenSigSendType" SG_ 2600403764 dispDriveConfigMode_BASE 0;
BA_ "GenSigSendType" SG_ 2600403764 activationStateACC_BASE 0;
BA_ "GenSigSendType" SG_ 2600403764 reqDrivingDir_BASE 0;
BA_ "GenSigSendType" SG_ 2600403764 reqDrivingProg1_BASE 0;
BA_ "GenSigSendType" SG_ 2600403764 SOCuserTES_BASE 0;
BA_ "GenSigSendType" SG_ 2600403764 engineCoolantTemperatureHR_BASE 0;
BA_ "GenSigSendType" SG_ 2600403764 comfortShiftState_BASE 0;
BA_ "GenSigSendType" SG_ 2600403786 tractionHelpActivationData_BASE 0;
BA_ "GenSigSendType" SG_ 2600403786 technicalAxleLoadExceededStatus_ 0;
BA_ "GenSigSendType" SG_ 2600403786 memoryLevelActivationData_BASE 0;
BA_ "GenSigSendType" SG_ 2600403786 lowPressModeActiveData_BASE 0;
BA_ "GenSigSendType" SG_ 2600403786 AP1lowIdleSwitch_BASIS 0;
BA_ "GenSigSendType" SG_ 2600403786 retTipSwPos_BASE 0;
BA_ "GenSigSendType" SG_ 2600403786 creepCtrlConvAct_BASE 0;
BA_ "GenSigSendType" SG_ 2600403786 transReqGear_BASE 0;
BA_ "GenSigSendType" SG_ 2600403786 MONd_errSA_BASE 0;
BA_ "GenSigSendType" SG_ 2600403786 MONd_safetyReactionSpdReq_BASE 0;
BA_ "GenSigSendType" SG_ 2600403780 brakePressHRfrontAxleLeftW_BASIS 0;
BA_ "GenSigSendType" SG_ 2600403780 brakePressHRrearAxle1leftW_BASIS 0;
BA_ "GenSigSendType" SG_ 2600403780 brakePressHRrearAxle1rightW_BASI 0;
BA_ "GenSigSendType" SG_ 2600403780 brakePressHRrearAxle2leftW_BASIS 0;
BA_ "GenSigSendType" SG_ 2600403780 brakePressHRrearAxle2rightW_BASI 0;
BA_ "GenSigSendType" SG_ 2600403780 hydraulicOilTemperature_BASIS 0;
BA_ "GenSigSendType" SG_ 2600403780 RDactivated_BASE 0;
BA_ "GenSigSendType" SG_ 2600403780 REactivated_BASE 0;
BA_ "GenSigSendType" SG_ 2600403780 RXactivated_BASE 0;
BA_ "GenSigSendType" SG_ 2600403780 MONd_safetyReactionTrqReq_BASE 0;
BA_ "GenSigSendType" SG_ 2600403780 brakePressHRfrontAxleRightW_BASI 0;
BA_ "GenSigSendType" SG_ 2600403783 actMapSlope_BASE 0;
BA_ "GenSigSendType" SG_ 2600403783 Mgu3MeasuredSpeed_BASE 0;
BA_ "GenSigSendType" SG_ 2600403783 CCmodeState_BASE 0;
BA_ "GenSigSendType" SG_ 2600403783 tsiSpeedLimitViolationTD_BASE 0;
BA_ "GenSigSendType" SG_ 2600403783 ureaLvlWarningDisp1_BASE 0;
BA_ "GenSigSendType" SG_ 2600403783 ureaLvlWarningDisp2_BASE 0;
BA_ "GenSigSendType" SG_ 2600403783 engineIdleRunActive_BASE 0;
BA_ "GenSigSendType" SG_ 2600403783 APkickdownSwitch_BASIS 0;
BA_ "GenSigSendType" SG_ 2600403783 pitchAngleTruck_BASE 0;
BA_ "GenSigSendType" SG_ 2600403779 hydroDriveOilTempDisp_BASE 0;
BA_ "GenSigSendType" SG_ 2600403779 PTO2reqTyp_BASE 0;
BA_ "GenSigSendType" SG_ 2600403779 hydroDriveState_BASE 0;
BA_ "GenSigSendType" SG_ 2600403779 PTO2deactivationReq_BASE 0;
BA_ "GenSigSendType" SG_ 2600403779 overrunCondActv_BASE 0;
BA_ "GenSigSendType" SG_ 2600403779 PTO1deactivationReq_BASE 0;
BA_ "GenSigSendType" SG_ 2600403779 actualEngineTorque_BASE 0;
BA_ "GenSigSendType" SG_ 2600403779 SATorqCtrPri_BASE 0;
BA_ "GenSigSendType" SG_ 2600403767 CCvehSpd_BASE 0;
BA_ "GenSigSendType" SG_ 2600403767 waterInFuelDiagSt_BASE 0;
BA_ "GenSigSendType" SG_ 2600403767 TSIactivatedTD_BASE 0;
BA_ "GenSigSendType" SG_ 2600403767 waterInFuelRawDiagSt_BASE 0;
BA_ "GenSigSendType" SG_ 2600403767 PTO1req_BASE 0;
BA_ "GenSigSendType" SG_ 2600403767 shiftLockDueToAirDiagSt_BASE 0;
BA_ "GenSigSendType" SG_ 2600403767 PTO2req_BASE 0;
BA_ "GenSigSendType" SG_ 2600403767 clutchLiningDiagSt_BASE 0;
BA_ "GenSigSendType" SG_ 2600403767 statusAutomatik_BASE 0;
BA_ "GenSigSendType" SG_ 2600403767 dispClutchOverloadDiagSt_BASE 0;
BA_ "GenSigSendType" SG_ 2600403767 driveOffAct_BASE 0;
BA_ "GenSigSendType" SG_ 2600403767 reqDrivingProg_BASE 0;
BA_ "GenSigSendType" SG_ 2600403767 PTO1reqTyp_BASE 0;
BA_ "GenSigSendType" SG_ 2600403778 totalRevoltnDriveCycle_BASE 0;
BA_ "GenSigSendType" SG_ 2600403778 clamp30_BASE 0;
BA_ "GenSigSendType" SG_ 2600403778 liftAxleActivationData_BASE 0;
BA_ "GenSigSendType" SG_ 2600403778 dispMGSpressClutch_BASE 0;
BA_ "GenSigSendType" SG_ 2600403778 EBSbrakeSwitch_BASIS 0;
BA_ "GenSigSendType" SG_ 2600403778 activationStatusEPTO_BASE 0;
BA_ "GenSigSendType" SG_ 2667525635 appValSlider5_BASE 0;
BA_ "GenSigSendType" SG_ 2667525635 appMinValSlider5_BASE 0;
BA_ "GenSigSendType" SG_ 2667525635 appMaxValSlider4_BASE 0;
BA_ "GenSigSendType" SG_ 2667525635 appMinValSlider4_BASE 0;
BA_ "GenSigSendType" SG_ 2667525635 appEnaSlider5_BASE 0;
BA_ "GenSigSendType" SG_ 2667525635 appEnaSlider4_BASE 0;
BA_ "GenSigSendType" SG_ 2667525635 appEnaSlider6_BASE 0;
BA_ "GenSigSendType" SG_ 2667525635 appEnaSlider1_BASE 0;
BA_ "GenSigSendType" SG_ 2667525635 appMinValSlider6_BASE 0;
BA_ "GenSigSendType" SG_ 2667525635 appMaxValSlider6_BASE 0;
BA_ "GenSigSendType" SG_ 2667525635 appValSlider4_BASE 0;
BA_ "GenSigSendType" SG_ 2667525635 appValSlider6_BASE 0;
BA_ "GenSigSendType" SG_ 2667525635 appEnaSlider2_BASE 0;
BA_ "GenSigSendType" SG_ 2667525635 appEnaSlider3_BASE 0;
BA_ "GenSigSendType" SG_ 2667525635 drvProgIndivActive_BASE 0;
BA_ "GenSigSendType" SG_ 2667525635 appMaxValSlider5_BASE 0;
BA_ "GenSigSendType" SG_ 2600403760 hyrdgnMaxTankTemperature_BASE 0;
BA_ "GenSigSendType" SG_ 2600403760 hyrdgnTemperatureHighSide_BASE 0;
BA_ "GenSigSendType" SG_ 2600403760 hyrdgnMinTankTemperature_BASE 0;
BA_ "GenSigSendType" SG_ 2566080807 FCCI_placeholder_BASE 0;
BA_ "GenSigSendType" SG_ 2566675782 HVESSnumberOfHVESPconfig_BASE 0;
BA_ "GenSigSendType" SG_ 2566678922 HVESSestRemDist_BASE 0;
BA_ "GenSigSendType" SG_ 2566827815 tripFuelGas_BASE 0;
BA_ "GenSigSendType" SG_ 2566827815 totalFuelUsedGas_BASE 0;
BA_ "GenSigSendType" SG_ 2565865488 retarderTorqueMode_RD 0;
BA_ "GenSigSendType" SG_ 2565865488 intendedRetarderPercentTorque_RD 0;
BA_ "GenSigSendType" SG_ 2565865488 sourceAddressOfControllDevice_RD 0;
BA_ "GenSigSendType" SG_ 2565865488 driversDemandRetarderPercTorque_ 0;
BA_ "GenSigSendType" SG_ 2565865488 reqTorqRDbyDriver_BASE 0;
BA_ "GenSigSendType" SG_ 2565865488 actMaxAvailRetPercTorque_RD 0;
BA_ "GenSigSendType" SG_ 2565865488 actualRetarderPercentTorque_RD 0;
BA_ "GenSigSendType" SG_ 2566845479 tireLocation_BASE 0;
BA_ "GenSigSendType" SG_ 2566845479 tireTemperature_BASIS 0;
BA_ "GenSigSendType" SG_ 2566845479 tireStatus_BASE 0;
BA_ "GenSigSendType" SG_ 2566845479 tireSensorElectricalFault_BASE 0;
BA_ "GenSigSendType" SG_ 2566845479 tirePressureThresholdDetection_B 0;
BA_ "GenSigSendType" SG_ 2566845479 tirePressure_SAE 0;
BA_ "GenSigSendType" SG_ 2565866755 transmissionSelectedGear_BASIS 0;
BA_ "GenSigSendType" SG_ 2565866755 transmissionCurrentGear_BASIS 0;
BA_ "GenSigSendType" SG_ 2565866755 lowestPossibleGear_BASIS 0;
BA_ "GenSigSendType" SG_ 2565866755 highestPossibleGear_BASIS 0;
BA_ "GenSigSendType" SG_ 2565866755 recommendedGear_BASIS 0;
BA_ "GenSigSendType" SG_ 2565866755 modeGear_BASIS 0;
BA_ "GenSigSendType" SG_ 2565866755 modeReverse_BASIS 0;
BA_ "GenSigSendType" SG_ 2565866755 automatikMode_MAN1 0;
BA_ "GenSigSendType" SG_ 2565866755 transmissionActualGearRatio_BASI 0;
BA_ "GenSigSendType" SG_ 2566774823 AMB2_placeholder_BASE 0;
BA_ "GenSigSendType" SG_ 2566687271 FCCP2S_placeholder_BASE 0;
BA_ "GenSigSendType" SG_ 2566575143 EVSEACS2_placeholder_BASE 0;
BA_ "GenSigSendType" SG_ 2566686247 FCHTR_placeholder_BASE 0;
BA_ "GenSigSendType" SG_ 2565902887 highestCellTempHVESS_BASE 0;
BA_ "GenSigSendType" SG_ 2565902887 lowestCellTempHVESS_BASE 0;
BA_ "GenSigSendType" SG_ 2565902887 avrgCellTempHVESS_BASE 0;
BA_ "GenSigSendType" SG_ 2566775079 AirConditionerCompressorStatus_B 0;
BA_ "GenSigSendType" SG_ 2566676038 HVESSstateOfHealth_BASE 0;
BA_ "GenSigSendType" SG_ 2566676038 HVESSTotalLifetimeEnrgOut_BASE 0;
BA_ "GenSigSendType" SG_ 2566676038 HVESSTotalLifetimeEnrgInp_BASE 0;
BA_ "GenSigSendType" SG_ 2566701706 storedEnrgySrcLevel_BASE 0;
BA_ "GenSigSendType" SG_ 2566701706 extrnlEnergySrcConnection_BASE 0;
BA_ "GenSigSendType" SG_ 2566701706 sysPropDisState_BASE 0;
BA_ "GenSigSendType" SG_ 2566701706 propulsionSystemActive_BASE 0;
BA_ "GenSigSendType" SG_ 2600403798 CVM80placeholder_BASE 0;
BA_ "GenSigSendType" SG_ 2600403790 CVM72placeholder_BASE 0;
BA_ "GenSigSendType" SG_ 2600403794 CVM76placeholder_BASE 0;
BA_ "GenSigSendType" SG_ 2600403795 CVM77placeholder_BASE 0;
BA_ "GenSigSendType" SG_ 2600403797 CVM79placeholder_BASE 0;
BA_ "GenSigSendType" SG_ 2600403796 CVM78placeholder_BASE 0;
BA_ "GenSigSendType" SG_ 2600403789 CVM71placeholder_BASE 0;
BA_ "GenSigSendType" SG_ 2600403792 CVM74placeholder_BASE 0;
BA_ "GenSigSendType" SG_ 2600403793 CVM75placeholder_BASE 0;
BA_ "GenSigSendType" SG_ 2600407303 energyAvbl_BASE 0;
BA_ "GenSigSendType" SG_ 2600407303 actHVpowerBCC_BASE 0;
BA_ "GenSigSendType" SG_ 2600407303 act24VpowerBCC_BASE 0;
BA_ "GenSigSendType" SG_ 2600407303 remDrvRangeWarning_BASE 0;
BA_ "GenSigSendType" SG_ 2600407303 highVoltSysModeAct_BASE 0;
BA_ "GenSigSendType" SG_ 2600407303 LimpHomeMode_BASE 0;
BA_ "GenSigSendType" SG_ 2600407303 externalShutOffHVinfo_BASE 0;
BA_ "GenSigSendType" SG_ 2600407303 vehParkingMode_BASE 0;
BA_ "GenSigSendType" SG_ 2600407303 drvSysReadyToMove_BASE 0;
BA_ "GenSigSendType" SG_ 2566811687 poweredVehicleWeight_VAR2_MC 0;
BA_ "GenSigSendType" SG_ 2566811687 grossCombinationVehicleWeight_VA 0;
BA_ "GenSigSendType" SG_ 2566811687 numberOfMassEstimations_BASIS 0;
BA_ "GenSigSendType" SG_ 2600407296 battInstEngy_BASE 0;
BA_ "GenSigSendType" SG_ 2600407296 lowestCellTempSysTES_BASE 0;
BA_ "GenSigSendType" SG_ 2600407296 highestCellTempSysTES_BASE 0;
BA_ "GenSigSendType" SG_ 2600407296 actStateChrgPlugDisp_BASE 0;
BA_ "GenSigSendType" SG_ 2600407296 directionIndicator_BASIS 0;
BA_ "GenSigSendType" SG_ 2600407296 actStateChrgPlug2Disp_BASE 0;
BA_ "GenSigSendType" SG_ 2600403740 coolantTempSetpointLR_BASE 0;
BA_ "GenSigSendType" SG_ 2600403740 rollDetectedBB_BASE 0;
BA_ "GenSigSendType" SG_ 2600403740 eco24VpwrSaveReqExt_BASE 0;
BA_ "GenSigSendType" SG_ 2600403740 driverPresentBB_BASE 0;
BA_ "GenSigSendType" SG_ 2600403740 ICErunning_BASE 0;
BA_ "GenSigSendType" SG_ 2600403740 extCAMshown1_BASE 0;
BA_ "GenSigSendType" SG_ 2600403740 extCAMshown2_BASE 0;
BA_ "GenSigSendType" SG_ 2600403740 extCAMshown3_BASE 0;
BA_ "GenSigSendType" SG_ 2600403740 extCAMshown4_BASE 0;
BA_ "GenSigSendType" SG_ 2600403740 extCAMshown5_BASE 0;
BA_ "GenSigSendType" SG_ 2600403740 seatBeltDriverState_BASE 0;
BA_ "GenSigSendType" SG_ 2600403740 seatBeltCoDrvrState_BASE 0;
BA_ "GenSigSendType" SG_ 2600403740 defiladeLight_BASE 0;
BA_ "GenSigSendType" SG_ 2600403740 CCswStatusComb_BASE 0;
BA_ "GenSigSendType" SG_ 2566847015 brakeApplicationPressure_BASE 0;
BA_ "GenSigSendType" SG_ 2566660647 totalEngineEnergy_BASE 0;
BA_ "GenSigSendType" SG_ 2566840064 nominalFrictionPercentTorque_BAS 0;
BA_ "GenSigSendType" SG_ 2566840064 estimatedEngineParasiticLossesPe 0;
BA_ "GenSigSendType" SG_ 2565865513 retarderTorqueMode_RX 0;
BA_ "GenSigSendType" SG_ 2565865513 intendedRetarderPercentTorque_RX 0;
BA_ "GenSigSendType" SG_ 2565865513 retarderSwitch_BASIS 0;
BA_ "GenSigSendType" SG_ 2565865513 actMaxAvailRetPercTorque_RX 0;
BA_ "GenSigSendType" SG_ 2565865513 actualRetarderPercentTorque_RX 0;
BA_ "GenSigSendType" SG_ 2551906343 HVESSC1_placeholder_BASE 0;
BA_ "GenSigSendType" SG_ 2565902631 HVESSD2_placeholder_BASE 0;
BA_ "GenSigSendType" SG_ 2566687015 FCCP1S_placeholder_BASE 0;
BA_ "GenSigSendType" SG_ 2566570030 MG4LD_placeholder_BASE 0;
BA_ "GenSigSendType" SG_ 2566569774 MG3LD_placeholder_BASE 0;
BA_ "GenSigSendType" SG_ 2566569518 totalEnergyConsmpDS2_BASE 0;
BA_ "GenSigSendType" SG_ 2566569518 totalEnergyGenDS2_BASE 0;
BA_ "GenSigSendType" SG_ 2566685991 FCHTRC_placeholder_BASE 0;
BA_ "GenSigSendType" SG_ 2364575882 HVESSavbDisChargePower_BASE 0;
BA_ "GenSigSendType" SG_ 2364575882 HVESSavbChargePower_BASE 0;
BA_ "GenSigSendType" SG_ 2364575882 HVESSvoltageLevel_BASE 0;
BA_ "GenSigSendType" SG_ 2364575882 HVESScurrent_BASE 0;
BA_ "GenSigSendType" SG_ 2566567975 EVSE_DC_Charging_State_BASE 0;
BA_ "GenSigSendType" SG_ 2566832167 serCID1_MC_VAR1 0;
BA_ "GenSigSendType" SG_ 2566832167 serCID2_MC_VAR1 0;
BA_ "GenSigSendType" SG_ 2566832167 serDelayCalendTiBasd_MC_VAR1 0;
BA_ "GenSigSendType" SG_ 2566832167 serCID3_MC_VAR1 0;
BA_ "GenSigSendType" SG_ 2566832167 serDelayOperatTiBasd_MC_VAR1 0;
BA_ "GenSigSendType" SG_ 2566832167 serviceDist_MC_VAR1 0;
BA_ "GenSigSendType" SG_ 2566819879 ETH_placeholder_BASE 0;
BA_ "GenSigSendType" SG_ 2566569262 totalEnergyConsmpDS1_BASE 0;
BA_ "GenSigSendType" SG_ 2566569262 totalEnergyGenDS1_BASE 0;
BA_ "GenSigSendType" SG_ 2600403765 HRengineTotalFuelUsed_BASE 0;
BA_ "GenSigSendType" SG_ 2600403765 calcClutchTorq_BASE 0;
BA_ "GenSigSendType" SG_ 2565933607 HVESSD8_placeholder_BASE 0;
BA_ "GenSigSendType" SG_ 2565933863 HVESSD9_placeholder_BASE 0;
BA_ "GenSigSendType" SG_ 2566810919 HTR_placeholder_BASE 0;
BA_ "GenSigSendType" SG_ 2565903143 HVESSchargeCapacity_BASE 0;
BA_ "GenSigSendType" SG_ 2566688551 gasFuelSupplyPress1extRange_BASE 0;
BA_ "GenSigSendType" SG_ 2565933351 activationStateHVHTES_BASE 0;
BA_ "GenSigSendType" SG_ 2565933351 reqModeTempTES_BASE 0;
BA_ "GenSigSendType" SG_ 2565933351 coolantEmptyLevelSwTES_BASE 0;
BA_ "GenSigSendType" SG_ 2600403788 curBrkmaticMode_BASE 0;
BA_ "GenSigSendType" SG_ 2600403788 fwdCameraBlocked_BASE 0;
BA_ "GenSigSendType" SG_ 2600403788 fwdRadarBlocked_BASE 0;
BA_ "GenSigSendType" SG_ 2600403788 CCmodeStateSG_BASE 0;
BA_ "GenSigSendType" SG_ 2600403788 transmissionOilTemperature_TCU 0;
BA_ "GenSigSendType" SG_ 2600403788 transmissionOilTemperature_WSK_B 0;
BA_ "GenSigSendType" SG_ 2600403788 lockupClutchTemperature_BASE 0;
BA_ "GenSigSendType" SG_ 2600403791 axleLocation_wght_BASE 0;
BA_ "GenSigSendType" SG_ 2600403791 reqDrivingProg_BASE 0;
BA_ "GenSigSendType" SG_ 2600403791 rockingFreeActivationPerm_BASE 0;
BA_ "GenSigSendType" SG_ 2600403791 vehicleRolling_BASE 0;
BA_ "GenSigSendType" SG_ 2600403791 vehicleRollingRobust_BASE 0;
BA_ "GenSigSendType" SG_ 2600403791 externalNeutralRequest_BASE 0;
BA_ "GenSigSendType" SG_ 2600403791 lockupClutchFeedback_BASE 0;
BA_ "GenSigSendType" SG_ 2600403791 technicalAxleLoadExceededStatus_ 0;
BA_ "GenSigSendType" SG_ 2600403761 railTempFiltered_BASE 0;
BA_ "GenSigSendType" SG_ 2600403761 nozzleEqCalc_BASE 0;
BA_ "GenSigSendType" SG_ 2600403761 actualInjEndPos_BASE 0;
BA_ "GenSigSendType" SG_ 2600403761 icmSparkVoltCyl3_BASE 0;
BA_ "GenSigSendType" SG_ 2600403761 fuelActualInComb_BASE 0;
BA_ "GenSigSendType" SG_ 2600403761 boostInjActive_BASE 0;
BA_ "GenSigSendType" SG_ 2600403761 eoiAfterIvcActive_BASE 0;
BA_ "GenSigSendType" SG_ 2600403761 railPresGaseous_BASE 0;
BA_ "GenSigSendType" SG_ 2566843182 CI_placeholder_BASE 0;
BA_ "GenSigSendType" SG_ 2583648885 chrgngPlugLckErrSttChrgI2_BASE 0;
BA_ "GenSigSendType" SG_ 2583648885 extrnlChrgDrtngReason_BASE 0;
BA_ "GenSigSendType" SG_ 2583648885 extrnlChrgEVSE_MACoctet1_BASE 0;
BA_ "GenSigSendType" SG_ 2583648885 extrnlChrgEVSE_MACoctet2_BASE 0;
BA_ "GenSigSendType" SG_ 2583648885 extrnlChrgEVSE_MACoctet3_BASE 0;
BA_ "GenSigSendType" SG_ 2583648885 extrnlChrgEVSE_MACoctet4_BASE 0;
BA_ "GenSigSendType" SG_ 2583648885 extrnlChrgEVSE_MACoctet5_BASE 0;
BA_ "GenSigSendType" SG_ 2583648885 extrnlChrgEVSE_MACoctet6_BASE 0;
BA_ "GenSigSendType" SG_ 2583648885 chrgngPlugLckErrSttChrgI_BASE 0;
BA_ "GenSigSendType" SG_ 2600454433 reqDispLKAdeact_BASE 3;
BA_ "GenSigSendType" SG_ 2600454433 reqDispMenuLKA_BASE 3;
BA_ "GenSigSendType" SG_ 2600454433 reqDispTJAdeactAuto_BASE 3;
BA_ "GenSigSendType" SG_ 2600454433 reqDispTJAdeactMan_BASE 3;
BA_ "GenSigSendType" SG_ 2600454433 TJAselected_BASE 3;
BA_ "GenSigSendType" SG_ 2600454433 reqDispVirtualConvoy_BASE 3;
BA_ "GenSigSendType" SG_ 2600454433 reqDispTJAdeactAutoNS_BASE 3;
BA_ "GenSigSendType" SG_ 2600454433 reqDispTCWblock_BASE 3;
BA_ "GenSigSendType" SG_ 2600454433 reqDispTCWcalib_BASE 3;
BA_ "GenSigSendType" SG_ 2600454433 reqDispTCWLCWlftBlock_BASE 3;
BA_ "GenSigSendType" SG_ 2600454433 reqDispTCWLCWlftCalib_BASE 3;
BA_ "GenSigSendType" SG_ 2600454433 reqDispTCWLCWlftPermFlt_BASE 3;
BA_ "GenSigSendType" SG_ 2600454433 reqDispTCWLCWlftTemp_BASE 3;
BA_ "GenSigSendType" SG_ 2600454433 reqDispTCWLCWrghBlock_BASE 3;
BA_ "GenSigSendType" SG_ 2600454433 reqDispTCWLCWrghCalib_BASE 3;
BA_ "GenSigSendType" SG_ 2600454433 reqDispTCWLCWrghPermFlt_BASE 3;
BA_ "GenSigSendType" SG_ 2600454433 reqDispTCWLCWrghTemp_BASE 3;
BA_ "GenSigSendType" SG_ 2600454433 reqDispLKAlatArrows_BASE 3;
BA_ "GenSigSendType" SG_ 2600454433 reqDispTCWlht_BASE 3;
BA_ "GenSigSendType" SG_ 2600454433 reqDispTCWpermFlt_BASE 3;
BA_ "GenSigSendType" SG_ 2600454433 reqDispTCWrht_BASE 3;
BA_ "GenSigSendType" SG_ 2600454433 reqDispTCWtemp_BASE 3;
BA_ "GenSigSendType" SG_ 2600454433 ecoWarningDoor_BASE 3;
BA_ "GenSigSendType" SG_ 2600454433 ecoWarningWndw_BASE 3;
BA_ "GenSigSendType" SG_ 2600454433 errPrkHeatingOff_BASE 3;
BA_ "GenSigSendType" SG_ 2600454433 wrnProgADRCluster_BASE 3;
BA_ "GenSigSendType" SG_ 2600454433 dispBattMainSwOffReqPrvnt_BASE 3;
BA_ "GenSigSendType" SG_ 2600454433 dispActEmergencySwitch_BASE 3;
BA_ "GenSigSendType" SG_ 2600454433 reqDispLKAmodeActive_BASE 3;
BA_ "GenSigSendType" SG_ 2600454433 stopStartDeselected_BASE 3;
BA_ "GenSigSendType" SG_ 2600454433 bckgrndLghtDefLiMd_BASE 3;
BA_ "GenSigSendType" SG_ 2600454433 reqDispLKAmodeStandby_BASE 3;
BA_ "GenSigSendType" SG_ 2600454425 couplingLockState_BASE 3;
BA_ "GenSigSendType" SG_ 2600454425 interlockServiceDue_BASE 3;
BA_ "GenSigSendType" SG_ 2600454425 tempLockout_BASE 3;
BA_ "GenSigSendType" SG_ 2600454425 permaLockout_BASE 3;
BA_ "GenSigSendType" SG_ 2600454425 ttAirSuspDeactivation_BASE 3;
BA_ "GenSigSendType" SG_ 2600454425 dispWrnElHySteer_BASE 3;
BA_ "GenSigSendType" SG_ 2600454425 DIGenableDistWrn_BASE 3;
BA_ "GenSigSendType" SG_ 2600454425 VASCsafeStateActive_BASE 3;
BA_ "GenSigSendType" SG_ 2600454425 reqCSSerrLmp_BASE 3;
BA_ "GenSigSendType" SG_ 2600454425 dispTipperStateSideWall_BASE 3;
BA_ "GenSigSendType" SG_ 2600454425 dispLimpHomeMode_BASE 3;
BA_ "GenSigSendType" SG_ 2600454425 tailGateRsp_BASE 3;
BA_ "GenSigSendType" SG_ 2600454425 ureaLvlWarningDisp1_BASE 3;
BA_ "GenSigSendType" SG_ 2600454425 VASCsupplyPressureLow_BASE 3;
BA_ "GenSigSendType" SG_ 2600454425 auxStatMC24cntE2E_BASE 3;
BA_ "GenSigSendType" SG_ 2600454425 auxStatMC24chkE2E_BASE 3;
BA_ "GenSigSendType" SG_ 2600454425 alcolTestMessage_BASE 3;
BA_ "GenSigSendType" SG_ 2566535719 enableSwitchePTO1_BASE 0;
BA_ "GenSigSendType" SG_ 2566535719 engageConsent_ePTO1_BASE 0;
BA_ "GenSigSendType" SG_ 2566535719 engageStatus_ePTO1_BASE 0;
BA_ "GenSigSendType" SG_ 2566535719 emrgncyDeenSw_ePTO1_BASE 0;
BA_ "GenSigSendType" SG_ 2566535719 systemRdnss_ePTO1_BASE 0;
BA_ "GenSigSendType" SG_ 2566535719 errorIndicator_ePTO1_BASE 0;
BA_ "GenSigSendType" SG_ 2566535719 activeDischargeRequest_ePTO1_BAS 0;
BA_ "GenSigSendType" SG_ 2566535719 ePTODE1_Count_BASE 0;
BA_ "GenSigSendType" SG_ 2351387943 msgCRC8saeJ1939_BASE 0;
BA_ "GenSigSendType" SG_ 2351387943 MG2ICLimReqOCM_BASE 0;
BA_ "GenSigSendType" SG_ 2351387943 MG2ICmaxLimReq_BASE 0;
BA_ "GenSigSendType" SG_ 2351387943 MG2ICminLimReq_BASE 0;
BA_ "GenSigSendType" SG_ 2351387943 MG2ICsetpointModeReq_BASE 0;
BA_ "GenSigSendType" SG_ 2351387943 MG2ICsetpointReq_BASE 0;
BA_ "GenSigSendType" SG_ 2351387943 msgCNTsaeJ1939_BASE 0;
BA_ "GenSigSendType" SG_ 2600403758 trendDataCVMvariant_BASE 0;
BA_ "GenSigSendType" SG_ 2600403758 trendDataCVMminorVersion_BASE 0;
BA_ "GenSigSendType" SG_ 2600403758 trendDataCVMmajorVersion_BASE 0;
BA_ "GenSigSendType" SG_ 2600403758 rmngMinutesCVM_BASE 0;
BA_ "GenSigSendType" SG_ 2600403758 rmngHoursCVM_BASE 0;
BA_ "GenSigSendType" SG_ 2600454438 extrnlChrgStatus_BASE 0;
BA_ "GenSigSendType" SG_ 2600454438 extrnlChrgFlapStateChrgI1_BASE 0;
BA_ "GenSigSendType" SG_ 2600454438 actStateChrgPlug2Disp_BASE 0;
BA_ "GenSigSendType" SG_ 2600454438 actStateChrgPlugDisp_BASE 0;
BA_ "GenSigSendType" SG_ 2600454438 extrnlChrgTargetSOC_HR_BASE 0;
BA_ "GenSigSendType" SG_ 2600454438 extrnlChrgTrgtDrvngRngDisp_BASE 0;
BA_ "GenSigSendType" SG_ 2600454438 extrnlChrgErrorType_BASE 0;
BA_ "GenSigSendType" SG_ 2600454438 extrnlChrgHoldInfImmedDisp_BASE 0;
BA_ "GenSigSendType" SG_ 2600454438 extrnlChrgModeDisp_BASE 0;
BA_ "GenSigSendType" SG_ 2600454438 energyManagmtMenuReq_BASE 0;
BA_ "GenSigSendType" SG_ 2600454438 coolantTempCCC_BASE 0;
BA_ "GenSigSendType" SG_ 2600454438 extrnlChrgOTActrlDisp_BASE 0;
BA_ "GenSigSendType" SG_ 2600454438 extrnlChrgFlapStateChrgI2_BASE 0;
VAL_ 2566807232 tyreWheelIdentification_T2_TO_T1 0 "wheel position undefined, axle position undefined" 1 "wheel position 1, axle position undefined" 2 "wheel position 2, axle position undefined" 3 "wheel position 3, axle position undefined" 4 "wheel position 4, axle position undefined" 5 "wheel position 5, axle position undefined" 6 "wheel position 6, axle position undefined" 7 "wheel position 7, axle position undefined" 8 "wheel position 8, axle position undefined" 9 "wheel position 9, axle position undefined" 10 "wheel position 10, axle position undefined" 11 "wheel position 11, axle position undefined" 12 "wheel position 12, axle position undefined" 13 "wheel position 13, axle position undefined" 14 "wheel position 14, axle position undefined" 15 "wheel position 15, axle position undefined" 16 "wheel position undefined, axle position 1" 17 "wheel position 1, axle position 1" 18 "wheel position 2, axle position 1" 19 "wheel position 3, axle position 1" 20 "wheel position 4, axle position 1" 21 "wheel position 5, axle position 1" 22 "wheel position 6, axle position 1" 23 "wheel position 7, axle position 1" 24 "wheel position 8, axle position 1" 25 "wheel position 9, axle position 1" 26 "wheel position 10, axle position 1" 27 "wheel position 11, axle position 1" 28 "wheel position 12, axle position 1" 29 "wheel position 13, axle position 1" 30 "wheel position 14, axle position 1" 31 "wheel position 15, axle position 1" 32 "wheel position undefined, axle position 2" 33 "wheel position 1, axle position 2" 34 "wheel position 2, axle position 2" 35 "wheel position 3, axle position 2" 36 "wheel position 4, axle position 2" 37 "wheel position 5, axle position 2" 38 "wheel position 6, axle position 2" 39 "wheel position 7, axle position 2" 40 "wheel position 8, axle position 2" 41 "wheel position 9, axle position 2" 42 "wheel position 10, axle position 2" 43 "wheel position 11, axle position 2" 44 "wheel position 12, axle position 2" 45 "wheel position 13, axle position 2" 46 "wheel position 14, axle position 2" 47 "wheel position 15, axle position 2" 48 "wheel position undefined, axle position 3" 49 "wheel position 1, axle position 3" 50 "wheel position 2, axle position 3" 51 "wheel position 3, axle position 3" 52 "wheel position 4, axle position 3" 53 "wheel position 5, axle position 3" 54 "wheel position 6, axle position 3" 55 "wheel position 7, axle position 3" 56 "wheel position 8, axle position 3" 57 "wheel position 9, axle position 3" 58 "wheel position 10, axle position 3" 59 "wheel position 11, axle position 3" 60 "wheel position 12, axle position 3" 61 "wheel position 13, axle position 3" 62 "wheel position 14, axle position 3" 63 "wheel position 15, axle position 3" 64 "wheel position undefined, axle position 4" 65 "wheel position 1, axle position 4" 66 "wheel position 2, axle position 4" 67 "wheel position 3, axle position 4" 68 "wheel position 4, axle position 4" 69 "wheel position 5, axle position 4" 70 "wheel position 6, axle position 4" 71 "wheel position 7, axle position 4" 72 "wheel position 8, axle position 4" 73 "wheel position 9, axle position 4" 74 "wheel position 10, axle position 4" 75 "wheel position 11, axle position 4" 76 "wheel position 12, axle position 4" 77 "wheel position 13, axle position 4" 78 "wheel position 14, axle position 4" 79 "wheel position 15, axle position 4" 80 "wheel position undefined, axle position 5" 81 "wheel position 1, axle position 5" 82 "wheel position 2, axle position 5" 83 "wheel position 3, axle position 5" 84 "wheel position 4, axle position 5" 85 "wheel position 5, axle position 5" 86 "wheel position 6, axle position 5" 87 "wheel position 7, axle position 5" 88 "wheel position 8, axle position 5" 89 "wheel position 9, axle position 5" 90 "wheel position 10, axle position 5" 91 "wheel position 11, axle position 5" 92 "wheel position 12, axle position 5" 93 "wheel position 13, axle position 5" 94 "wheel position 14, axle position 5" 95 "wheel position 15, axle position 5" 96 "wheel position undefined, axle position 6" 97 "wheel position 1, axle position 6" 98 "wheel position 2, axle position 6" 99 "wheel position 3, axle position 6" 100 "wheel position 4, axle position 6" 101 "wheel position 5, axle position 6" 102 "wheel position 6, axle position 6" 103 "wheel position 7, axle position 6" 104 "wheel position 8, axle position 6" 105 "wheel position 9, axle position 6" 106 "wheel position 10, axle position 6" 107 "wheel position 11, axle position 6" 108 "wheel position 12, axle position 6" 109 "wheel position 13, axle position 6" 110 "wheel position 14, axle position 6" 111 "wheel position 15, axle position 6" 112 "wheel position undefined, axle position 7" 113 "wheel position 1, axle position 7" 114 "wheel position 2, axle position 7" 115 "wheel position 3, axle position 7" 116 "wheel position 4, axle position 7" 117 "wheel position 5, axle position 7" 118 "wheel position 6, axle position 7" 119 "wheel position 7, axle position 7" 120 "wheel position 8, axle position 7" 121 "wheel position 9, axle position 7" 122 "wheel position 10, axle position 7" 123 "wheel position 11, axle position 7" 124 "wheel position 12, axle position 7" 125 "wheel position 13, axle position 7" 126 "wheel position 14, axle position 7" 127 "wheel position 15, axle position 7" 128 "wheel position undefined, axle position 8" 129 "wheel position 1, axle position 8" 130 "wheel position 2, axle position 8" 131 "wheel position 3, axle position 8" 132 "wheel position 4, axle position 8" 133 "wheel position 5, axle position 8" 134 "wheel position 6, axle position 8" 135 "wheel position 7, axle position 8" 136 "wheel position 8, axle position 8" 137 "wheel position 9, axle position 8" 138 "wheel position 10, axle position 8" 139 "wheel position 11, axle position 8" 140 "wheel position 12, axle position 8" 141 "wheel position 13, axle position 8" 142 "wheel position 14, axle position 8" 143 "wheel position 15, axle position 8" 144 "wheel position undefined, axle position 9" 145 "wheel position 1, axle position 9" 146 "wheel position 2, axle position 9" 147 "wheel position 3, axle position 9" 148 "wheel position 4, axle position 9" 149 "wheel position 5, axle position 9" 150 "wheel position 6, axle position 9" 151 "wheel position 7, axle position 9" 152 "wheel position 8, axle position 9" 153 "wheel position 9, axle position 9" 154 "wheel position 10, axle position 9" 155 "wheel position 11, axle position 9" 156 "wheel position 12, axle position 9" 157 "wheel position 13, axle position 9" 158 "wheel position 14, axle position 9" 159 "wheel position 15, axle position 9" 160 "wheel position undefined, axle position 10" 161 "wheel position 1, axle position 10" 162 "wheel position 2, axle position 10" 163 "wheel position 3, axle position 10" 164 "wheel position 4, axle position 10" 165 "wheel position 5, axle position 10" 166 "wheel position 6, axle position 10" 167 "wheel position 7, axle position 10" 168 "wheel position 8, axle position 10" 169 "wheel position 9, axle position 10" 170 "wheel position 10, axle position 10" 171 "wheel position 11, axle position 10" 172 "wheel position 12, axle position 10" 173 "wheel position 13, axle position 10" 174 "wheel position 14, axle position 10" 175 "wheel position 15, axle position 10" 176 "wheel position undefined, axle position 11" 177 "wheel position 1, axle position 11" 178 "wheel position 2, axle position 11" 179 "wheel position 3, axle position 11" 180 "wheel position 4, axle position 11" 181 "wheel position 5, axle position 11" 182 "wheel position 6, axle position 11" 183 "wheel position 7, axle position 11" 184 "wheel position 8, axle position 11" 185 "wheel position 9, axle position 11" 186 "wheel position 10, axle position 11" 187 "wheel position 11, axle position 11" 188 "wheel position 12, axle position 11" 189 "wheel position 13, axle position 11" 190 "wheel position 14, axle position 11" 191 "wheel position 15, axle position 11" 192 "wheel position undefined, axle position 12" 193 "wheel position 1, axle position 12" 194 "wheel position 2, axle position 12" 195 "wheel position 3, axle position 12" 196 "wheel position 4, axle position 12" 197 "wheel position 5, axle position 12" 198 "wheel position 6, axle position 12" 199 "wheel position 7, axle position 12" 200 "wheel position 8, axle position 12" 201 "wheel position 9, axle position 12" 202 "wheel position 10, axle position 12" 203 "wheel position 11, axle position 12" 204 "wheel position 12, axle position 12" 205 "wheel position 13, axle position 12" 206 "wheel position 14, axle position 12" 207 "wheel position 15, axle position 12" 208 "wheel position undefined, axle position 13" 209 "wheel position 1, axle position 13" 210 "wheel position 2, axle position 13" 211 "wheel position 3, axle position 13" 212 "wheel position 4, axle position 13" 213 "wheel position 5, axle position 13" 214 "wheel position 6, axle position 13" 215 "wheel position 7, axle position 13" 216 "wheel position 8, axle position 13" 217 "wheel position 9, axle position 13" 218 "wheel position 10, axle position 13" 219 "wheel position 11, axle position 13" 220 "wheel position 12, axle position 13" 221 "wheel position 13, axle position 13" 222 "wheel position 14, axle position 13" 223 "wheel position 15, axle position 13" 224 "wheel position undefined, axle position 14" 225 "wheel position 1, axle position 14" 226 "wheel position 2, axle position 14" 227 "wheel position 3, axle position 14" 228 "wheel position 4, axle position 14" 229 "wheel position 5, axle position 14" 230 "wheel position 6, axle position 14" 231 "wheel position 7, axle position 14" 232 "wheel position 8, axle position 14" 233 "wheel position 9, axle position 14" 234 "wheel position 10, axle position 14" 235 "wheel position 11, axle position 14" 236 "wheel position 12, axle position 14" 237 "wheel position 13, axle position 14" 238 "wheel position 14, axle position 14" 239 "wheel position 15, axle position 14" 240 "wheel position undefined, axle position 15" 241 "wheel position 1, axle position 15" 242 "wheel position 2, axle position 15" 243 "wheel position 3, axle position 15" 244 "wheel position 4, axle position 15" 245 "wheel position 5, axle position 15" 246 "wheel position 6, axle position 15" 247 "wheel position 7, axle position 15" 248 "wheel position 8, axle position 15" 249 "wheel position 9, axle position 15" 250 "wheel position 10, axle position 15" 251 "wheel position 11, axle position 15" 252 "wheel position 12, axle position 15" 253 "wheel position 13, axle position 15" 254 "wheel position 14, axle position 15" 255 "wheel position 15, axle position 15";
VAL_ 2566807232 tirePressureThresholdDetection_T 0 "extreme over pressure" 1 "over pressure" 2 "no warning pressure" 3 "under pressure" 4 "extreme under pressure" 5 "not defined" 6 "error indicator" 7 "not available";
VAL_ 2566807232 tireModulePowerSupply_T2_TO_T1TR 0 "Insufficient power supply" 1 "Sufficient power supply" 2 "error" 3 "not available";
VAL_ 2365571367 highVoltSysModeAct_BASE 0 "HV-off" 1 "Drive" 2 "AC-Charge" 3 "DC-Charge" 4 "HVsysError" 5 "Discharging" 14 "Error" 15 "Not available";
VAL_ 2365571367 remDrvRangeWarning_BASE 0 "no warning" 1 "warning active, energy content low" 2 "ECO mode active, energy content low" 14 "error" 15 "not available";
VAL_ 2365571367 BattSysCritOtWarn_BASE 0 "Not Active" 1 "Active" 2 "Error" 3 "Not available";
VAL_ 2365571367 redVehAcousticModeReq_BASE 0 "no request" 1 "PIEK mode requested" 2 "silent mode requested" 14 "error" 15 "not available";
VAL_ 2364577418 HVESSpassiveIsoTestStatus_BASE 0 "No test requested / No test in process" 1 "Test requested but not yet in process" 2 "Test in process" 3 "Test complete; isolation acceptable" 4 "Test complete; isolation marginal" 5 "Test complete; isolation fault" 6 "Test is inhibited" 7 "Reserved" 8 "Reserved" 9 "Reserved" 10 "Reserved" 14 "error" 15 "not available";
VAL_ 2364577418 HVESSintrnlChrgrState_BASE 0 "charging off" 1 "charging on" 2 "error" 3 "not available";
VAL_ 2600403782 acclCtrlActuatorMode_BASE 0 "control off" 1 "EB speed control active" 2 "EB speed control passive" 3 "Eng speed control passive" 4 "Eng speed control active" 5 "EB accl control active" 6 "EB accl control passive" 7 "Eng accl control passive" 8 "Eng accl control active";
VAL_ 2600403782 CCreqTscOcmSek01_BASE 0 "override disable" 1 "speed control" 2 "torque control" 3 "speed / torque limit" 4 "acceleration limit" 6 "error" 7 "not available";
VAL_ 2600403782 CCreqTscOcmSek00_BASE 0 "override disable" 1 "speed control" 2 "torque control" 3 "speed torque limit" 4 "acceleration limit" 6 "error" 7 "not available";
VAL_ 2600403782 highVoltageActv_BASE 0 "HV-system not active" 1 "HV-system active" 2 "error" 3 "not available";
VAL_ 2600454405 pressAirWarnCirc1_BASE 0 "no warning" 1 "warning" 2 "warning and stop" 14 "error" 15 "not available";
VAL_ 2600454405 pressAirWarnCirc2_BASE 0 "no warning" 1 "warning" 2 "warning and stop" 14 "error" 15 "not available";
VAL_ 2600454405 pressAirWarnCirc3_BASE 0 "no warning" 1 "warning" 2 "warning and stop" 3 "warning (no trailer connected)" 14 "error" 15 "not available";
VAL_ 2600454405 pressAirWarnCirc4_BASE 0 "no warning" 1 "warning" 2 "warning and stop" 14 "error" 15 "not available";
VAL_ 2600454405 diffLockReq_BASE 0 "none" 1 "rear axle" 2 "front axle";
VAL_ 2600454405 diffCentralLockReq_BASE 0 "none" 1 "rear axle" 2 "transfer case" 3 "front axle";
VAL_ 2566898182 tourDataSetMux_BASE 0 "TourData01" 1 "TourData02" 2 "TourData03" 3 "TourData04" 4 "TourData05";
VAL_ 2566848295 waterInFuelIndicator_BASE 0 "no water in fuel detected" 1 "water in fuel detected" 2 "error" 3 "not available";
VAL_ 2600454439 highVoltSysModeAct_BASE 0 "HV-off" 1 "Drive" 2 "AC-Charge" 3 "DC-Charge" 4 "HVsysError" 5 "Discharging" 14 "Error" 15 "Not available";
VAL_ 2600454439 vehParkingMode_BASE 0 "vehicle not in parking mode" 1 "vehicle in parking mode" 2 "error" 3 "not available";
VAL_ 2600454439 remDrvRangeWarning_BASE 0 "no warning" 1 "warning active, energy content low" 2 "ECO mode active, energy content low" 14 "error" 15 "not available";
VAL_ 2600454439 warningSOCoverflowDisp_BASE 0 "Warning request not active" 1 "Warning request active" 2 "error" 3 "not available";
VAL_ 2600454439 LimpHomeMode_BASE 0 "LIMP home mode not active" 1 "LIMP home mode active" 2 "error" 3 "not available";
VAL_ 2600403759 estCorrSpdClsAdapt_BASE 0 "vehicle speed 0 to 29 km/h" 1 "vehicle speed 30 to 49 km/h" 2 "vehicle speed 50 to 69 km/h" 3 "vehicle speed 70 to 90 km/h" 4 "vehicle speed 91to 110 km/h" 5 "vehicle speed 111 to 130 km/h" 14 "error" 15 "not available";
VAL_ 2600403759 estCorrSpdTrlAdapt_BASE 0 "no trailer connected" 1 "trailer connected" 2 "error" 3 "not available";
VAL_ 2566827568 airCompressorStatus_BASE 0 "Compressor not active" 1 "Compressor active" 2 "error" 3 "not available";
VAL_ 2600407434 stCombHeat_BASE 0 "off" 1 "active" 2 "closed" 3 "failure" 14 "error" 15 "not available";
VAL_ 2600407434 actStatePreCond_BASE 0 "preconditioning not active" 1 "preconditioning active" 2 "error" 3 "not available";
VAL_ 2600407434 thermalAlertPredctnTES_BASE 0 "no thermal alert detected" 1 "thermal alert detected" 2 "error" 3 "not available";
VAL_ 2600407434 actModeHVAC1_BASE 0 "ventilation mode" 1 "heating mode" 2 "air conditioning mode" 14 "error" 15 "not available";
VAL_ 2600407434 washerFluidLvlLow_BASE 0 "washer level above threshold" 1 "washer level below threshold" 2 "error" 3 "not available";
VAL_ 2600403769 reqAirComp_BASE 0 "air compressor off (external request)" 1 "air compressor on (external request)" 2 "error" 3 "not available";
VAL_ 2600403769 setAirComp_BASE 0 "air compressor off" 1 "air compressor on" 2 "error" 3 "signal not available";
VAL_ 2600403769 reqDrivingDir1_BASE 0 "R - cruising range reverse" 1 "N - cruising range neutral" 2 "D - cruising range forward" 4 "reserved 4" 5 "reserved 5" 6 "reserved 6" 7 "reserved 7" 8 "reserved 8" 9 "reserved 9" 10 "reserved 10" 11 "error 11" 12 "error 12" 13 "error 13" 14 "error" 15 "not available";
VAL_ 2600403777 transCurRange_BASE 12356 "D0 (ASCII:0x44 0x30)  external neutral" 12612 "D1 (ASCII:0x44 0x31) 1.starting gear" 12626 "R1 (ASCII: 0x52 0x31) 1. starting gear reverse" 12868 "D2 (ASCII:0x44 0x32) 2. starting gear" 12882 "R2 (ASCII: 0x52 0x32) 2. starting gear reverse" 13124 "D3 (ASCII:0x44 0x33) 3. starting gear" 13138 "R3 (ASCII: 0x52 0x33) 3. starting gear reverse" 13380 "D4 (ASCII:0x44 0x34)  4. starting gear" 13394 "R4 (ASCII: 0x52 0x34) 4. starting gear reverse" 13636 "D5 (ASCII:0x44 0x35) 5.starting gear" 13892 "D6 (ASCII:0x44 0x36) 6. starting gear" 14148 "D7 (ASCII: 0x44 0x37) 7. starting gear" 16964 "DB (ASCII:0x44 0x42) Roll function activated" 17220 "DC (ASCII:0x44 0x43) Roll function active" 17440 "D (ASCII: 0x20 0x44)  forward gear" 17734 "(ASCII:0x46 0x45) Error" 17988 "DF (ASCII:0x44 0x46) rockingFree D activated" 18002 "RF (ASCII:0x52 0x46) rockingFree R activated" 18244 "DG (ASCII:0x44 0x47) rockingFree Forward active" 18258 "RG (ASCII:0x52 0x47) rockingFree Reverse active" 18500 "DH (ASCII:0x44 0x48) rockingFree Dm activated" 18514 "RH (ASCII:0x52 0x48) rockingFree Rm activated" 18759 "DI (ASCII:0x44 0x49) rockingFree Dx activated" 18770 "RI (ASCII:0x52 0x49) rockingFree Rx activated" 19780 "DM (ASCII: 0x44 0x4D)  maneuver" 19794 "RM (ASCII: 0x52 0x4D) maneuver reverse" 20000 "N (ASCII: 0x20 0x4E)  neutral gear" 20548 "DP(ASCII:0x44 0x50) power mode" 20804 "DQ (ASCII:0x44 0x51) rockingFree Power activated" 21024 "R (ASCII: 0x20 0x52) reverse gear" 22596 "DX (ASCII: 0x44 0x58) offroad" 22610 "RX (ASCII: 0x52 0x58) offroad  reverse";
VAL_ 2600403777 transReqRange_BASE 12356 "D0 (ASCII:0x44 0x30)  external neutral" 12612 "D1 (ASCII:0x44 0x31) 1.starting gear" 12626 "R1 (ASCII: 0x52 0x31) 1. starting gear reverse" 12868 "D2 (ASCII:0x44 0x32) 2. starting gear" 12882 "R2 (ASCII: 0x52 0x32) 2. starting gear reverse" 13124 "D3 (ASCII:0x44 0x33) 3. starting gear" 13138 "R3 (ASCII: 0x52 0x33) 3. starting gear reverse" 13380 "D4 (ASCII:0x44 0x34)  4. starting gear" 13394 "R4 (ASCII: 0x52 0x34) 4. starting gear reverse" 13636 "D5 (ASCII:0x44 0x35) 5.starting gear" 13892 "D6 (ASCII:0x44 0x36) 6. starting gear" 14148 "D7 (ASCII: 0x44 0x37) 7. starting gear" 16964 "DB (ASCII:0x44 0x42) Roll function activated" 17220 "DC (ASCII:0x44 0x43) Roll function active" 17440 "D (ASCII: 0x20 0x44)  forward gear" 17734 "(ASCII:0x46 0x45) Error" 17988 "DF (ASCII:0x44 0x46) rockingFree D activated" 18002 "RF (ASCII:0x52 0x46) rockingFree R activated" 18244 "DG (ASCII:0x44 0x47) rockingFree Forward active" 18258 "RG (ASCII:0x52 0x47) rockingFree Reverse active" 18500 "DH (ASCII:0x44 0x48) rockingFree Dm activated" 18514 "RH (ASCII:0x52 0x48) rockingFree Rm activated" 18759 "DI (ASCII:0x44 0x49) rockingFree Dx activated" 18770 "RI (ASCII:0x52 0x49) rockingFree Rx activated" 19780 "DM (ASCII: 0x44 0x4D)  maneuver" 19794 "RM (ASCII: 0x52 0x4D) maneuver reverse" 20000 "N (ASCII: 0x20 0x4E)  neutral gear" 20548 "DP(ASCII:0x44 0x50) power mode" 20804 "DQ (ASCII:0x44 0x51) rockingFree Power activated" 21024 "R (ASCII: 0x20 0x52) reverse gear" 22596 "DX (ASCII: 0x44 0x58) offroad" 22610 "RX (ASCII: 0x52 0x58) offroad  reverse";
VAL_ 2600403777 engineOperatingState_BASE 0 "Engine Stopped" 1 "Pre-Start" 2 "Starting" 3 "Warm-Up" 4 "Running" 5 "Cool-down" 6 "Engine Stopping" 7 "Post-Run" 15 "not available";
VAL_ 2600403777 modeAG_BASE 0 "Manuellmode" 1 "Automatikmode" 2 "error" 3 "not available";
VAL_ 2600403777 clutchFrictionActive_BASE 0 "no active clutch work" 1 "active clutch work" 2 "error" 3 "not available";
VAL_ 2600403777 engStart_BASE 0 "no start request" 1 "normal start request" 2 "emergency start request" 3 "start request without fuel injection" 6 "error" 7 "not available";
VAL_ 2600403777 increaseGear_BASE 0 "inactive" 1 "active" 2 "error" 3 "not available";
VAL_ 2600403777 MONd_safetyReactionDrivetrain_BA 0 "Keine Sicherheitsreaktion" 1 "Sicherheitsreaktion wird aufgrund eines Fehlers ausgelöst";
VAL_ 2600403777 DrvOffAgnstCurDrvDirActv_BASE 0 "not active" 1 "active" 2 "error" 3 "not available";
VAL_ 2600403777 manualModeRequest_BASE 0 "no request" 1 "manual mode request" 2 "error" 3 "not available";
VAL_ 2600403777 manualRetarderControl_BASIS 0 "off" 1 "on" 2 "error" 3 "not available";
VAL_ 2600403777 decreaseGear_BASE 0 "inactive" 1 "active" 2 "error" 3 "not available";
VAL_ 2600403777 displayMonErrTorqueSpeedReq_BASE 0 "do not display torque/speed request violation" 1 "display torque/speed request violation" 2 "error" 3 "not available";
VAL_ 2600403776 EmgcyBrkSysStatePlausi_BASE 0 "system is not ready (initialization not finished)" 1 "system is temporarily not available (e.g. due to boundary conditions necessary for operation)" 2 "system is deactivated by driver" 3 "system is ready (no warning and no braking active)" 4 "driver overrides system" 5 "collision warning active (not affecting vehicle dynamics)" 6 "collision warning with braking (e.g. brake jerk or partial braking)" 7 "emergency braking active" 14 "error" 15 "not available / not installed";
VAL_ 2600403776 EBAarbObjMotionType_BASE 0 "unkown" 1 "oncoming" 2 "stationary" 3 "stopped" 4 "comoving" 5 "crossing left" 6 "crossing right" 7 "not available" 14 "error" 15 "not available";
VAL_ 2600403776 actualRange_BASE 0 "slow range group" 1 "fast range group" 2 "error" 3 "not available";
VAL_ 2600403776 vehicleDriveState_BASE 0 "vehicle stand still" 1 "vehicle drives forward" 2 "vehicles drives backwards" 3 "vehicle direction unknown" 6 "error" 7 "not available";
VAL_ 2600403776 engState_BASE 0 "engine stand still" 1 "engine slow speed" 2 "engine running" 3 "engine over speed" 6 "error" 7 "not available";
VAL_ 2600403764 ESPcontrActv_BASE 0 "Off" 1 "On" 2 "reserved" 3 "Don't care/Take no action" 6 "error" 7 "not available";
VAL_ 2600403764 shiftInProcess_BASIS 0 "shift is not in process" 1 "shift in process" 2 "error" 3 "not available";
VAL_ 2600403764 dispDriveConfigMode_BASE 0 "coasting requested" 1 "low level requested" 2 "high level requested" 3 "reserved 3" 4 "reserved 4" 5 "reserved 5" 6 "reserved 6" 7 "reserved 7" 8 "reserved 8" 9 "reserved 9" 10 "reserved 10" 11 "error 1" 12 "error 2" 13 "error 3" 14 "error 4" 15 "not available";
VAL_ 2600403764 activationStateACC_BASE 0 "deactive" 1 "active" 2 "at deactivation" 3 "standby" 14 "error indicator" 15 "not available / not installed";
VAL_ 2600403764 reqDrivingDir_BASE 0 "R - cruising range reverse" 1 "N - cruising range neutral" 2 "D - cruising range forward" 6 "error" 7 "not available";
VAL_ 2600403764 reqDrivingProg1_BASE 0 "Programm 0 (default)" 1 "Programm 1" 2 "Programm 2" 3 "Programm 3" 4 "Programm 4" 5 "Programm 5" 6 "Programm 6" 7 "Programm 7" 8 "Programm 8" 9 "Programm 9" 10 "Programm 10" 11 "Programm 11" 12 "Programm 12" 13 "Programm 13" 14 "Programm 14" 30 "error" 31 "not available";
VAL_ 2600403764 comfortShiftState_BASE 0 "passive" 1 "active" 2 "error" 3 "not available";
VAL_ 2600403786 AP1lowIdleSwitch_BASIS 0 "AP 1 not in low idle condition" 1 "AP 1  in low idle condition" 2 "Error" 3 "Not available";
VAL_ 2600403786 retTipSwPos_BASE 0 "Tipstufe 0; keine Tipstufe" 1 "Tipstufe 1" 2 "Tipstufe 2" 3 "Tipstufe 3" 4 "Tipstufe 4" 5 "Tipstufe 5" 6 "Tipstufe 6" 7 "Tipstufe 7" 8 "Tipstufe 8" 9 "Tipstufe 9" 10 "Tipstufe 10" 14 "error" 15 "not available";
VAL_ 2600403786 creepCtrlConvAct_BASE 0 "not active" 1 "active" 2 "error" 3 "not available";
VAL_ 2600403786 MONd_errSA_BASE 0 "No error active" 1 "Driveoff observer" 2 "Clutch/engine coordination" 3 "Drag torque control" 4 "Start up clutch control" 5 "Clutch protection" 6 "Clutch control neutral" 7 "reserved" 8 "TEM start/stop control" 9 "reserved" 10 "reserved" 11 "reserved" 12 "reserved" 13 "reserved" 14 "reserved" 15 "reserved" 16 "reserved" 17 "Gearbox" 18 "Comfort shift" 19 "Low range go" 20 "Clutch slip control" 21 "Secondary limit during open drivetrain" 22 "Low gear go" 23 "Control transRearAxle" 24 "Brake/EBS system" 25 "Accelerator pedal" 26 "Accelerator pedal limit" 27 "Secondary command from FGR/ACC" 28 "Limit due to cooling liquid" 29 "Electronic noise management" 30 "Vehicle acceleration limit" 31 "Command by PIN" 32 "Tropic engine protection" 33 "ZDR speed control/limit" 34 "Secondary limit for endurance brakes" 35 "Gear dependent speed/torque limit" 36 "Inhibit vehicle startup" 37 "Limit due to speed manipulation" 38 "Engine low idle control" 39 "PTO speed/torque limit" 40 "Low idle increase for E-management" 41 "Limit during EfficientRoll" 42 "Clutch control for PTO / limit after driveoff" 43 "UpShift support" 44 "Electronic creep torque control" 45 "Limit during showing" 46 "Driveoff using Brake pedal" 47 "Limit by gearbox ECU" 48 "Secondary limit from EBA" 49 "ACC Stop and Go" 50 "Command/limit from external ECU" 51 "ATC kink protection" 52 "KSM command/limit" 53 "Dynamic torque limit" 54 "Engine speed limit D38" 55 "Gear dependent speed/torque limit (NHMR)" 56 "reserved" 57 "reserved" 58 "reserved" 59 "reserved" 60 "reserved" 61 "reserved" 62 "reserved" 63 "reserved";
VAL_ 2600403786 MONd_safetyReactionSpdReq_BASE 0 "Keine Sicherheitsreaktion" 1 "Sicherheitsreaktion wird aufgrund eines Fehlers ausgelöst" 2 "error" 3 "not available";
VAL_ 2600403780 RDactivated_BASE 0 "retarder drive line NOT active" 1 "retarder drive line active" 2 "error" 3 "not available";
VAL_ 2600403780 REactivated_BASE 0 "retarder engine NOT active" 1 "retarder engine active" 2 "error" 3 "not available";
VAL_ 2600403780 RXactivated_BASE 0 "retarder exhaust NOT active" 1 "retarder exhaust active" 2 "error" 3 "not available";
VAL_ 2600403780 MONd_safetyReactionTrqReq_BASE 0 "Keine Sicherheitsreaktion" 1 "Sicherheitsreaktion wird aufgrund eines Fehlers ausgelöst" 2 "error" 3 "not available";
VAL_ 2600403783 CCmodeState_BASE 0 "Init" 1 "CCmodeInit" 2 "OFFmode" 3 "ACCmode - ACCerror" 4 "FGRmode - FGRerror" 5 "FGBmode - FGBerror" 10 "FGBmode - OFFpressed" 11 "FGBmode - FGBpassiv" 12 "FGBmode - FGBstandby" 13 "FGBmode - FGBactv" 20 "FGRmode - FGRpassiv" 21 "ACCmode - ACCpassiv" 22 "FGRmode - FGRactv" 23 "ACCmode - ACCactv" 30 "error" 31 "not available";
VAL_ 2600403783 tsiSpeedLimitViolationTD_BASE 0 "Not violated" 1 "Violated" 2 "Undefined" 6 "error" 7 "not available";
VAL_ 2600403783 ureaLvlWarningDisp1_BASE 0 "warning urea level not active" 1 "warning urea level active" 2 "error" 3 "not available";
VAL_ 2600403783 ureaLvlWarningDisp2_BASE 0 "warning urea level not active" 1 "warning urea level active" 2 "error" 3 "not available";
VAL_ 2600403783 engineIdleRunActive_BASE 0 "idle run not active" 1 "idle run active";
VAL_ 2600403783 APkickdownSwitch_BASIS 0 "Kickdown passive" 1 "Kickdown active" 2 "Error" 3 "Not available";
VAL_ 2600403779 PTO2reqTyp_BASE 0 "not defined" 1 "stationary transfercase mounted" 2 "stationary engine mounted" 3 "stationary transfercase mounted" 4 "instationary engine mounted" 5 "instationary transmission mounted" 6 "stationary transmission mounted" 7 "not available" 14 "error" 15 "not available";
VAL_ 2600403779 hydroDriveState_BASE 0 "not activated" 1 "activated and not active" 2 "activated and active" 3 "temperature shut off" 4 "speed shut off" 14 "error" 15 "not available";
VAL_ 2600403779 PTO2deactivationReq_BASE 0 "no PTO2 deactivation" 1 "manual PTO2 deactivation" 2 "automated PTO2 deactivation due to internal fault conditions" 3 "automated PTO2 deactivation due to manual shift - misuse" 6 "error" 7 "not available";
VAL_ 2600403779 overrunCondActv_BASE 0 "over run not active" 1 "over run active";
VAL_ 2600403779 PTO1deactivationReq_BASE 0 "no PTO1 deactivation" 1 "manual PTO1 deactivation" 2 "automated PTO1 deactivation due to internal fault conditions" 3 "automated PTO1 deactivation due to manual shift - misuse" 6 "error" 7 "not available";
VAL_ 2600403767 waterInFuelDiagSt_BASE 0 "valid" 2 "not available / not installed" 18 "warning active";
VAL_ 2600403767 TSIactivatedTD_BASE 0 "off" 1 "on" 2 "error" 3 "not available";
VAL_ 2600403767 waterInFuelRawDiagSt_BASE 0 "valid" 2 "not available / not installed" 18 "warning active";
VAL_ 2600403767 PTO1req_BASE 0 "no request" 1 "request" 2 "error" 3 "not available";
VAL_ 2600403767 shiftLockDueToAirDiagSt_BASE 0 "valid" 2 "not available" 18 "warning" 34 "below minimum threshold";
VAL_ 2600403767 PTO2req_BASE 0 "no request" 1 "request" 2 "error" 3 "not available";
VAL_ 2600403767 clutchLiningDiagSt_BASE 0 "valid" 2 "not available" 34 "below minimum threshold";
VAL_ 2600403767 statusAutomatik_BASE 0 "automatic not available" 1 "automatic available" 2 "error" 3 "not available";
VAL_ 2600403767 dispClutchOverloadDiagSt_BASE 0 "valid" 18 "warning active";
VAL_ 2600403767 driveOffAct_BASE 0 "drive off inactive" 1 "drive off active" 2 "error" 3 "not available";
VAL_ 2600403767 reqDrivingProg_BASE 0 "Programm 0 (default)" 1 "Programm 1" 2 "Programm 2" 3 "Programm 3" 4 "Programm 4" 5 "Programm 5" 6 "Programm 6" 7 "Programm 7" 8 "Programm 8" 9 "Programm 9" 10 "Programm 10" 11 "Programm 11" 12 "Programm 12" 13 "Programm 13" 14 "Programm 14" 15 "error/not available";
VAL_ 2600403767 PTO1reqTyp_BASE 0 "not defined" 1 "stationary transfercase mounted" 2 "stationary engine mounted" 3 "instationary transfercase mounted" 4 "instationary engine mounted" 5 "instationary transmission mounted" 6 "stationary transmission mounted" 7 "not available" 14 "error" 15 "not available";
VAL_ 2600403778 dispMGSpressClutch_BASE 0 "passive" 1 "active" 2 "error" 3 "not available";
VAL_ 2600403778 EBSbrakeSwitch_BASIS 0 "Brake pedal is not being pressed" 1 "Brake pedal is being pressed" 2 "error" 3 "not available";
VAL_ 2600403778 activationStatusEPTO_BASE 0 "off" 1 "pending off" 2 "pending active" 3 "active" 14 "error" 15 "not available";
VAL_ 2667525635 appEnaSlider5_BASE 0 "not enabled" 1 "enabled" 2 "error" 3 "not available";
VAL_ 2667525635 appEnaSlider4_BASE 0 "not enabled" 1 "enabled" 2 "error" 3 "not available";
VAL_ 2667525635 appEnaSlider6_BASE 0 "not enabled" 1 "enabled" 2 "error" 3 "not available";
VAL_ 2667525635 appEnaSlider1_BASE 0 "not enabled" 1 "enabled" 2 "error" 3 "not available";
VAL_ 2667525635 appEnaSlider2_BASE 0 "not enabled" 1 "enabled" 2 "error" 3 "not available";
VAL_ 2667525635 appEnaSlider3_BASE 0 "not enabled" 1 "enabled" 2 "error" 3 "not available";
VAL_ 2667525635 drvProgIndivActive_BASE 0 "not active" 1 "active" 2 "error" 3 "not available";
VAL_ 2565865488 retarderTorqueMode_RD 0 "Low idle governor/ no request(default mode)" 1 "Acelator pedal/operator selection" 2 "cruise control" 3 "PTO governor" 4 "Road Speed Governor" 5 "ASR Control" 6 "Transmission Control" 7 "ABS Control" 8 "Torque Limiting" 9 "High Speed Governor" 10 "Braking System" 11 "Remote Accelerator" 12 "Service Procedure" 13 "not defined" 14 "other" 15 "not available";
VAL_ 2566845479 tireLocation_BASE 0 "outer left axle 1" 1 "inner left axle 1" 2 "inner right axle 1" 3 "outer right axle 1" 16 "outer left axle 2" 17 "inner left axle 2" 18 "inner right axle 2" 19 "outer right axle 2" 32 "outer left axle 3" 33 "inner left axle 3" 34 "inner right axle 3" 35 "outer right axle 3" 48 "outer left axle 4" 49 "inner left axle 4" 50 "inner right axle 4" 51 "outer right axle 4" 64 "outer left axle 5" 65 "inner left axle 5" 66 "inner right axle 5" 67 "outer right axle 5" 80 "outer left axle 6" 81 "inner left axle 6" 82 "inner right axle 6" 83 "outer right axle 6" 224 "spare tire 1" 254 "Error" 255 "Not Available";
VAL_ 2566845479 tireStatus_BASE 0 "Ok (no fault)" 1 "Tire leak detected" 2 "Error" 3 "Not Available";
VAL_ 2566845479 tireSensorElectricalFault_BASE 0 "Ok (No Fault)" 1 "Not Defined (Fault)" 2 "Error" 3 "Not Supported";
VAL_ 2566845479 tirePressureThresholdDetection_B 0 "extreme over pressure" 1 "over pressure" 2 "no warning pressure" 3 "under pressure" 4 "extreme under pressure" 5 "not defined" 6 "error indicator" 7 "not available";
VAL_ 2565866755 modeGear_BASIS 1 "1-9 range2 = 0x31 - 0x39" 14 "range2 = 0x4D" 15 "sonst";
VAL_ 2565866755 modeReverse_BASIS 0 "Range1 = 0x44" 1 "Range1 = 0x52" 3 "sonst";
VAL_ 2565866755 automatikMode_MAN1 0 "sonst" 1 "ReqGear = 0xFA";
VAL_ 2566775079 AirConditionerCompressorStatus_B 0 "Air Conditioner Compressor is OFF" 1 "Air Conditioner Compressor is ON" 2 "error" 3 "not available";
VAL_ 2566701706 extrnlEnergySrcConnection_BASE 0 "No Connection" 1 "Connection Error (Verification failed)" 2 "Connection Verification in Process" 3 "Connection 1 - Energy Source and Drain" 4 "Connection 1 - Energy Source" 5 "Connection 1 - Energy Drain" 6 "Connection 2 - Error (Verification failed)  (Grandfathered state: new applications shall use state 0001b)" 7 "Connection 2 - Verification in Process  (Grandfathered state: new applications shall use state 0010b)" 8 "Connection 2 - Energy Source and Drain" 9 "Connection 2 - Energy Source" 10 "Connection 2 - Energy Drain" 11 "Connection 3 - Energy Source and Drain" 12 "Connection 3 - Energy Source" 13 "Connection 3 - Energy Drain" 14 "Error" 15 "Not Available";
VAL_ 2566701706 sysPropDisState_BASE 0 "propulsion not disabled" 1 "propulsion disabled" 2 "error" 3 "not available";
VAL_ 2566701706 propulsionSystemActive_BASE 0 "Propulsion System is not ready to move vehicle if commanded by operator" 1 "Propulsion System is ready to move vehicle if commanded by operator" 2 "error" 3 "not available";
VAL_ 2600407303 remDrvRangeWarning_BASE 0 "no warning" 1 "warning active, energy content low" 2 "ECO mode active, energy content low" 14 "error" 15 "not available";
VAL_ 2600407303 highVoltSysModeAct_BASE 0 "HV-off" 1 "Drive" 2 "AC-Charge" 3 "DC-Charge" 4 "HVsysError" 5 "Discharging" 14 "Error" 15 "Not available";
VAL_ 2600407303 LimpHomeMode_BASE 0 "LIMP home mode not active" 1 "LIMP home mode active" 2 "error" 3 "not available";
VAL_ 2600407303 externalShutOffHVinfo_BASE 0 "no external shut-off" 1 "external shut-off due to emergency case" 2 "error" 3 "not available";
VAL_ 2600407303 vehParkingMode_BASE 0 "vehicle not in parking mode" 1 "vehicle in parking mode" 2 "error" 3 "not available";
VAL_ 2600407303 drvSysReadyToMove_BASE 0 "off" 1 "on" 2 "error" 3 "not available";
VAL_ 2600407296 actStateChrgPlugDisp_BASE 0 "not plugged" 1 "plugged and unlocked" 2 "plugged and locked" 3 "not plausible" 4 "reserve 1" 5 "reserve 2" 6 "reserve 3" 7 "reserve 4" 8 "reserve 5" 9 "reserve 6" 10 "reserve 7" 11 "reserve 8" 12 "reserve 9" 13 "reserve 10" 14 "error" 15 "not available";
VAL_ 2600407296 directionIndicator_BASIS 0 "forward" 1 "reverse" 2 "error" 3 "not available";
VAL_ 2600407296 actStateChrgPlug2Disp_BASE 0 "not plugged" 1 "plugged and unlocked" 2 "plugged and locked" 3 "not plausible" 4 "reserved 1" 5 "reserved 2" 6 "reserved 3" 7 "reserved 4" 8 "reserved 5" 9 "reserved 6" 10 "reserved 7" 11 "reserved 8" 12 "reserved 9" 13 "reserved 10" 14 "error" 15 "not available";
VAL_ 2600403740 rollDetectedBB_BASE 0 "vehicle stand still" 1 "rolling / movig forward" 2 "rolling / moving backwards" 3 "reserved" 4 "reserved" 5 "reserved" 6 "reserved" 7 "reserved" 8 "reserved" 9 "reserved" 10 "reserved" 11 "error" 12 "error" 13 "error" 14 "error" 15 "not available";
VAL_ 2600403740 eco24VpwrSaveReqExt_BASE 0 "no power limit" 1 "power limited" 2 "error" 3 "not available";
VAL_ 2600403740 driverPresentBB_BASE 0 "driver not present" 1 "driver present" 2 "error" 3 "not available";
VAL_ 2600403740 ICErunning_BASE 0 "ICE not running" 1 "ICE running" 2 "error" 3 "not available";
VAL_ 2600403740 extCAMshown1_BASE 0 "Camera not shown" 1 "Camera currently visible on screen" 2 "error" 3 "not available";
VAL_ 2600403740 extCAMshown2_BASE 0 "Camera not shown" 1 "Camera currently visible on screen" 2 "error" 3 "not available";
VAL_ 2600403740 extCAMshown3_BASE 0 "Camera not shown" 1 "Camera currently visible on screen" 2 "error" 3 "not available";
VAL_ 2600403740 extCAMshown4_BASE 0 "Camera not shown" 1 "Camera currently visible on screen" 2 "error" 3 "not available";
VAL_ 2600403740 extCAMshown5_BASE 0 "Camera not shown" 1 "Camera currently visible on screen" 2 "error" 3 "not available";
VAL_ 2600403740 seatBeltDriverState_BASE 0 "not locked" 1 "locked" 2 "error" 3 "not available";
VAL_ 2600403740 seatBeltCoDrvrState_BASE 0 "not locked" 1 "locked" 2 "error" 3 "not available";
VAL_ 2600403740 defiladeLight_BASE 0 "deactivated" 1 "activated" 2 "error" 3 "not available";
VAL_ 2600403740 CCswStatusComb_BASE 0 "neutral" 1 "Off" 4 "Set-" 16 "Resume" 64 "Set+" 128 "Set" 170 "Defect" 250 "Safe current Speed";
VAL_ 2566847015 brakeApplicationPressure_BASE 251 "error" 252 "error" 253 "error" 254 "error" 255 "not available";
VAL_ 2565865513 retarderTorqueMode_RX 0 "Low idle governor_ no request(default mode)" 1 "Acelator pedal _ operator selection" 2 "cruise control" 3 "PTO governor" 4 "Road Speed Governor" 5 "ASR Control" 6 "Transmission Control" 7 "ABS Control" 8 "Torque Limiting" 9 "High Speed Governor" 10 "Braking System" 11 "Remote Accelerator" 12 "Service Procedure" 13 "not defined" 14 "other" 15 "not available";
VAL_ 2565865513 retarderSwitch_BASIS 0 "aus" 1 "Retarderstufe 1" 2 "Retarderstufe 2" 3 "Retarderstufe 3" 4 "Retarderstufe 4" 5 "Retarderstufe 5" 6 "Retarderstufe 6" 7 "Retarderstufe 7" 8 "Retarderstufe 8" 9 "Retarderstufe 9" 10 "Retarderstufe 10" 11 "reserved 1" 12 "reserved 2" 13 "reserved 3" 14 "reserved 4" 15 "reserved 5";
VAL_ 2566567975 EVSE_DC_Charging_State_BASE 0 "Idle No EVSE connected" 1 "Charging" 2 "Standby" 3 "Reserved 3" 4 "Power Delivery Startup" 5 "reserved" 6 "Power Delivery Shutdown" 7 "Welding Check" 8 "Charge Parameter Discovery" 9 "Cable Check" 10 "Initializing" 11 "Precharge" 12 "Terminating" 13 "Battery failure An error condition due to the battery state" 14 "EVSE fault  An error condition due to the EVSE" 15 "Not available";
VAL_ 2566832167 serCID1_MC_VAR1 000 "Service Check for entire vehicle" 001 "Brake Lining: left front axle" 002 "Brake Lining: right front axle" 003 "Brake Lining: left rear axle" 004 "Brake Lining: right rear axle" 005 "Clutch Lining" 006 "006-10 not defined" 011 "Brake Lining: left rear axle #2" 012 "Brake Lining: right rear axle #2" 013 "Brake Lining: left rear axle #3" 014 "Brake Lining: right rear axle #3" 015 "Brake Lining: General" 016 "Regulated general check for entire vehicle" 017 "Brake System General Check" 018 "In-between check" 019 "Check Trip Recorder" 020 "Check Exhaust Gas" 021 "Check Vehicle Speed Limiter" 022 "022-029 not defined" 030 "Engine Coolant Change" 031 "Engine Coolant Filter Change" 032 "Engine Oil - Engine #1" 033 "Engine Oil - Engine #2" 034 "not defined" 035 "Steering Oil" 036 "not defined" 037 "Transmission Oil - Transmission #1" 038 "Transmission Oil - Transmission #2" 039 "not defined" 040 "intermediate transmission oil" 041 "not defined" 042 "Front Axle Oil" 043 "Rear Axle Oil" 044 "044-47 not defined" 048 "Tires" 049 "Engine Air Filter" 050 "Engine Oil Filter" 051 "Engine Fuel  Filter" 052 "052-060 not defined" 061 "Tachograph" 062 "Driver Card #1" 063 "Driver Card #2" 064 "064-239 not defined" 240 "240-249 Manufacturer Specific" 250 "250-251 Reserved" 252 "Reset all Components" 253 "No Action To Be Taken" 254 "Error" 255 "Component Identification not available";
VAL_ 2566832167 serCID2_MC_VAR1 000 "Service Check for entire vehicle" 001 "Brake Lining: left front axle" 002 "Brake Lining: right front axle" 003 "Brake Lining: left rear axle" 004 "Brake Lining: right rear axle" 005 "Clutch Lining" 006 "006-10 not defined" 011 "Brake Lining: left rear axle #2" 012 "Brake Lining: right rear axle #2" 013 "Brake Lining: left rear axle #3" 014 "Brake Lining: right rear axle #3" 015 "Brake Lining: General" 016 "Regulated general check for entire vehicle" 017 "Brake System General Check" 018 "In-between check" 019 "Check Trip Recorder" 020 "Check Exhaust Gas" 021 "Check Vehicle Speed Limiter" 022 "022-029 not defined" 030 "Engine Coolant Change" 031 "Engine Coolant Filter Change" 032 "Engine Oil - Engine #1" 033 "Engine Oil - Engine #2" 034 "not defined" 035 "Steering Oil" 036 "not defined" 037 "Transmission Oil - Transmission #1" 038 "Transmission Oil - Transmission #2" 039 "not defined" 040 "intermediate transmission oil" 041 "not defined" 042 "Front Axle Oil" 043 "Rear Axle Oil" 044 "044-47 not defined" 048 "Tires" 049 "Engine Air Filter" 050 "Engine Oil Filter" 051 "Engine Fuel  Filter" 052 "052-060 not defined" 061 "Tachograph" 062 "Driver Card #1" 063 "Driver Card #2" 064 "064-239 not defined" 240 "240-249 Manufacturer Specific" 250 "250-251 Reserved" 252 "Reset all Components" 253 "No Action To Be Taken" 254 "Error" 255 "Component Identification not available";
VAL_ 2566832167 serCID3_MC_VAR1 000 "Service Check for entire vehicle" 001 "Brake Lining: left front axle" 002 "Brake Lining: right front axle" 003 "Brake Lining: left rear axle" 004 "Brake Lining: right rear axle" 005 "Clutch Lining" 006 "006-10 not defined" 011 "Brake Lining: left rear axle #2" 012 "Brake Lining: right rear axle #2" 013 "Brake Lining: left rear axle #3" 014 "Brake Lining: right rear axle #3" 015 "Brake Lining: General" 016 "Regulated general check for entire vehicle" 017 "Brake System General Check" 018 "In-between check" 019 "Check Trip Recorder" 020 "Check Exhaust Gas" 021 "Check Vehicle Speed Limiter" 022 "022-029 not defined" 030 "Engine Coolant Change" 031 "Engine Coolant Filter Change" 032 "Engine Oil - Engine #1" 033 "Engine Oil - Engine #2" 034 "not defined" 035 "Steering Oil" 036 "not defined" 037 "Transmission Oil - Transmission #1" 038 "Transmission Oil - Transmission #2" 039 "not defined" 040 "intermediate transmission oil" 041 "not defined" 042 "Front Axle Oil" 043 "Rear Axle Oil" 044 "044-47 not defined" 048 "Tires" 049 "Engine Air Filter" 050 "Engine Oil Filter" 051 "Engine Fuel  Filter" 052 "052-060 not defined" 061 "Tachograph" 062 "Driver Card #1" 063 "Driver Card #2" 064 "064-239 not defined" 240 "240-249 Manufacturer Specific" 250 "250-251 Reserved" 252 "Reset all Components" 253 "No Action To Be Taken" 254 "Error" 255 "Component Identification not available";
VAL_ 2565933351 activationStateHVHTES_BASE 0 "HVH off" 1 "HVH on" 2 "error" 3 "not available";
VAL_ 2565933351 reqModeTempTES_BASE 0 "Circulating" 1 "Cooling" 2 "Heating" 14 "error" 15 "not available";
VAL_ 2565933351 coolantEmptyLevelSwTES_BASE 0 "Empty Level not active" 1 "Empty Level active" 2 "error" 3 "not available";
VAL_ 2600403788 curBrkmaticMode_BASE 0 "Nothing (active) -" 1 "Deactivated BrakeMatic - A/" 2 "Automatic active and working - A" 3 "Servicebrake active and working - symbol brake" 4 "Manual Level 1 active and working" 5 "Manual Level 2 active and working" 6 "Manual Level 3 active and working" 7 "Manual Level 4 active and working" 8 "Manual Level 5 active and working" 9 "Manual Level 6 active and working" 10 "Manual Level Max active and working (reserved)" 11 "Manual Level active and working - only one level" 12 "Off Symbol" 254 "error" 255 "not available";
VAL_ 2600403788 fwdCameraBlocked_BASE 0 "no blockage detected" 1 "blockage detected" 2 "error" 3 "not available";
VAL_ 2600403788 fwdRadarBlocked_BASE 0 "no blockage detected" 1 "blockage detected" 2 "error" 3 "not available";
VAL_ 2600403788 CCmodeStateSG_BASE 0 "Init" 1 "CCmode Init" 2 "off mode" 3 "FGB passive" 4 "FGB active" 5 "FGB standby" 6 "FGR passive" 7 "FGR active" 8 "FGR from ACC transition" 9 "ACC passive" 10 "ACC active" 11 "ACC at deactivation" 12 "ACC standby" 254 "error" 255 "not available";
VAL_ 2600403791 reqDrivingProg_BASE 0 "Programm 0 (default)" 1 "Programm 1" 2 "Programm 2" 3 "Programm 3" 4 "Programm 4" 5 "Programm 5" 6 "Programm 6" 7 "Programm 7" 8 "Programm 8" 9 "Programm 9" 10 "Programm 10" 11 "Programm 11" 12 "Programm 12" 13 "Programm 13" 14 "Programm 14" 15 "error/not available";
VAL_ 2600403791 rockingFreeActivationPerm_BASE 0 "no RockingFree permission to arbiter" 1 "RockingFree permission to arbiter" 2 "error" 3 "not available";
VAL_ 2600403791 vehicleRolling_BASE 0 "drivetrain not open due to vehicle rolling request" 1 "drivetrain open due to vehicle rolling request" 2 "error" 3 "not available";
VAL_ 2600403791 vehicleRollingRobust_BASE 0 "drivetrain not open due to vehicle rolling request" 1 "drivetrain open due to vehicle rolling request" 2 "error" 3 "not available";
VAL_ 2600403791 externalNeutralRequest_BASE 0 "passive" 1 "active" 2 "error" 3 "not available";
VAL_ 2600403791 lockupClutchFeedback_BASE 0 "lockup clutch open" 1 "lockup clutch slipping" 2 "lockup clutch closed" 3 "lockup clutch in transition" 4 "lockup clutch controlled by adaption" 5 "lockup clutch not available" 6 "lockup clutch error" 7 "lockup clutch disengaged due to communication error" 8 "lockup clutch opened due to false neutral" 9 "lockup clutch temporarily not responding" 10 "lockup clutch performance derated" 11 "warm up phase" 12 "reserved 6" 13 "reserved 7" 14 "error" 15 "not available";
VAL_ 2600403761 boostInjActive_BASE 0 "False" 1 "True";
VAL_ 2600403761 eoiAfterIvcActive_BASE 0 "False" 1 "True";
VAL_ 2583648885 chrgngPlugLckErrSttChrgI2_BASE 0 "no error" 1 "error active" 2 "error" 3 "not available";
VAL_ 2583648885 extrnlChrgDrtngReason_BASE 0 "no reason" 1 "C-Box temperature" 2 "charging inlet temperature" 3 "OBC derating" 4 "reserved" 5 "reserved" 6 "reserved" 7 "reserved" 8 "reserved" 9 "reserved" 10 "reserved" 14 "error" 15 "not available";
VAL_ 2583648885 chrgngPlugLckErrSttChrgI_BASE 0 "no error" 1 "error active" 2 "error" 3 "not available";
VAL_ 2600454433 reqDispLKAdeact_BASE 0 "not active" 1 "active" 2 "error" 3 "not available";
VAL_ 2600454433 reqDispMenuLKA_BASE 0 "not active" 1 "active" 2 "error" 3 "not available";
VAL_ 2600454433 reqDispTJAdeactAuto_BASE 0 "not active" 1 "active" 2 "error" 3 "not available";
VAL_ 2600454433 reqDispTJAdeactMan_BASE 0 "not active" 1 "active" 2 "error" 3 "not available";
VAL_ 2600454433 TJAselected_BASE 0 "TJA is not selected" 1 "TJA is selected" 2 "error" 3 "not available";
VAL_ 2600454433 reqDispVirtualConvoy_BASE 0 "do not show convoy" 1 "show convoy" 2 "error" 3 "not available";
VAL_ 2600454433 reqDispTJAdeactAutoNS_BASE 0 "not active" 1 "active" 2 "error" 3 "not available";
VAL_ 2600454433 reqDispTCWblock_BASE 0 "not active" 1 "active" 2 "error" 3 "not available";
VAL_ 2600454433 reqDispTCWcalib_BASE 0 "not active" 1 "active" 2 "error" 3 "not available";
VAL_ 2600454433 reqDispTCWLCWlftBlock_BASE 0 "not active" 1 "active" 2 "error" 3 "not available";
VAL_ 2600454433 reqDispTCWLCWlftCalib_BASE 0 "not active" 1 "active" 2 "error" 3 "not available";
VAL_ 2600454433 reqDispTCWLCWlftPermFlt_BASE 0 "not active" 1 "active" 2 "error" 3 "not available";
VAL_ 2600454433 reqDispTCWLCWlftTemp_BASE 0 "not active" 1 "active" 2 "error" 3 "not available";
VAL_ 2600454433 reqDispTCWLCWrghBlock_BASE 0 "not active" 1 "active" 2 "error" 3 "not available";
VAL_ 2600454433 reqDispTCWLCWrghCalib_BASE 0 "not active" 1 "active" 2 "error" 3 "not available";
VAL_ 2600454433 reqDispTCWLCWrghPermFlt_BASE 0 "not active" 1 "active" 2 "error" 3 "not available";
VAL_ 2600454433 reqDispTCWLCWrghTemp_BASE 0 "not active" 1 "active" 2 "error" 3 "not available";
VAL_ 2600454433 reqDispLKAlatArrows_BASE 0 "do not show arrows" 1 "show arrows" 2 "error" 3 "not available";
VAL_ 2600454433 reqDispTCWlht_BASE 0 "not active" 1 "active" 2 "error" 3 "not available";
VAL_ 2600454433 reqDispTCWpermFlt_BASE 0 "not active" 1 "active" 2 "error" 3 "not available";
VAL_ 2600454433 reqDispTCWrht_BASE 0 "not active" 1 "active" 2 "error" 3 "not available";
VAL_ 2600454433 reqDispTCWtemp_BASE 0 "not active" 1 "active" 2 "error" 3 "not available";
VAL_ 2600454433 ecoWarningDoor_BASE 0 "No Eco warning door" 1 "Eco warning door" 2 "error" 3 "not available";
VAL_ 2600454433 ecoWarningWndw_BASE 0 "No Eco warning window" 1 "Eco warning window" 2 "error" 3 "not available";
VAL_ 2600454433 errPrkHeatingOff_BASE 0 "no Not-Off" 1 "Not-Off" 2 "error" 3 "not available";
VAL_ 2600454433 wrnProgADRCluster_BASE 0 "no warning" 1 "warning" 2 "error" 3 "not available";
VAL_ 2600454433 dispBattMainSwOffReqPrvnt_BASE 0 "no display" 1 "display" 2 "error" 3 "not available";
VAL_ 2600454433 dispActEmergencySwitch_BASE 0 "off" 1 "on" 2 "error" 3 "not available";
VAL_ 2600454433 reqDispLKAmodeActive_BASE 0 "not in active mode" 1 "active mode" 2 "error" 3 "not available";
VAL_ 2600454433 stopStartDeselected_BASE 0 "the driver does not want to deselect the stop start automatic." 1 "the driver wants to deselect the stop start automatic." 2 "error" 3 "not available";
VAL_ 2600454433 bckgrndLghtDefLiMd_BASE 0 "full MiL mode" 1 "reduced MiL mode" 2 "error" 3 "not available";
VAL_ 2600454433 reqDispLKAmodeStandby_BASE 0 "not standby mode" 1 "standby mode" 2 "error" 3 "not available";
VAL_ 2600454425 couplingLockState_BASE 0 "Nothing to display from fifth wheel" 1 "reserved" 2 "Forward gear engaged: Plate 1 Kingpin 0 Lock 0" 3 "Plate 0 Kingpin 1 Lock 0" 4 "Reverse or neutral gear engaged: Plate 1 Kingpin 0 Lock 0" 5 "Plate 1 Kingpin 1 Lock 1: closed" 6 "Plate 1 Kingpin 0 Lock 1" 7 "Plate 1 Kingpin 1 Lock 0" 8 "Plate 0 Kingpin 1 Lock 1" 9 "Plate 0 Kingpin 0 Lock 1" 10 "Sensored fifth wheel error" 11 "Sensored fifth wheel is deactivated by service" 254 "error" 255 "not available";
VAL_ 2600454425 interlockServiceDue_BASE 0 "No calibration of the alcohol interlock test equipment needed" 1 "Calibration of the alcohol test equipment is due" 2 "Error" 3 "Not available";
VAL_ 2600454425 tempLockout_BASE 0 "Temporary lockout not present" 1 "Temporary lockout present" 2 "Error" 3 "Not available";
VAL_ 2600454425 permaLockout_BASE 0 "Permanent lockout not present" 1 "Permanent lockout present" 2 "Error" 3 "Not available";
VAL_ 2600454425 ttAirSuspDeactivation_BASE 0 "inactive" 1 "active" 2 "Error" 3 "Not available";
VAL_ 2600454425 dispWrnElHySteer_BASE 0 "No message" 1 "Fallback mode message" 2 "MCU Failure mode message" 3 "Compensation mode message" 4 "Reduced mode message" 5 "Fail mode message" 6 "Self-Healing mode message" 7 "Overheating mode message" 8 "Unknown mode message" 9 "24 Volt not OK mode message" 10 "Steering function not OK mode message" 11 "Steering system warmup active" 14 "error" 15 "not available";
VAL_ 2600454425 DIGenableDistWrn_BASE 0 "off" 1 "on" 2 "error" 3 "not available";
VAL_ 2600454425 VASCsafeStateActive_BASE 0 "inactive" 1 "active" 2 "error" 3 "not available";
VAL_ 2600454425 reqCSSerrLmp_BASE 0 "CSS error indication lamp inactive" 1 "CSS error indication lamp active" 2 "error" 3 "not available";
VAL_ 2600454425 dispTipperStateSideWall_BASE 0 "display tipper sidewall locked" 1 "display tipper sidewall unlocked" 2 "error" 3 "not available";
VAL_ 2600454425 dispLimpHomeMode_BASE 0 "no display" 1 "display Limp Home Mode can be activated" 2 "display Limp Home Mode preselected" 3 "display Limp Home Mode active" 4 "display Limp Home Mode deactivated" 5 "reserved 5" 6 "reserved 6" 7 "reserved 7" 8 "reserved 8" 9 "reserved 9" 10 "reserved 10" 11 "error 1" 12 "error 2" 13 "error 3" 14 "error" 15 "not available";
VAL_ 2600454425 tailGateRsp_BASE 0 "Response tailGate closed" 1 "Response tailGate open" 2 "error" 3 "not available";
VAL_ 2600454425 ureaLvlWarningDisp1_BASE 0 "warning urea level not active" 1 "warning urea level active" 2 "error" 3 "not available";
VAL_ 2600454425 VASCsupplyPressureLow_BASE 0 "inactive" 1 "active" 2 "error" 3 "not available";
VAL_ 2600454425 alcolTestMessage_BASE 0 "No message" 1 "ALCOHOLVEHICLELOCK_TEST_HINT" 2 "ALCOHOLVEHICLELOCK_EMERGENCYSTART_HINT" 3 "ALCOHOLVEHICLELOCK_INCORRECT_OPERATION_HINT" 4 "ALCOHOLVEHICLELOCK_ADVANCE_HINT" 5 "ALCOHOLVEHICLELOCK_ERROR_HINT" 6 "ALCOHOLVEHICLELOCK_EMERGENCYSTART_DONE" 14 "Error" 15 "Not available";
VAL_ 2566535719 enableSwitchePTO1_BASE 0 "Enable switch off - ePTO operation not desired" 1 "Enable switch on - ePTO operation desired" 2 "Error" 3 "Not available";
VAL_ 2566535719 engageConsent_ePTO1_BASE 0 "Consent not given - ePTO should not be activated or engaged" 1 "Consent given - ePTO equipment may be activated or engaged" 2 "Error" 3 "Not available";
VAL_ 2566535719 engageStatus_ePTO1_BASE 0 "Drive not activated or engaged" 1 "Drive is activated or engaged" 2 "Error" 3 "Not available";
VAL_ 2566535719 emrgncyDeenSw_ePTO1_BASE 0 "Emergency De-energize not active" 1 "Emergency De-energize active - initiate shutdown" 2 "Error" 3 "Not available";
VAL_ 2566535719 systemRdnss_ePTO1_BASE 0 "ePTO not available due to system error" 1 "ePTO available" 2 "Reserved" 3 "Not available";
VAL_ 2566535719 errorIndicator_ePTO1_BASE 0 "no ePTO error detected or ePTO not enabled" 1 "ePTO error detected" 2 "Reserved" 3 "Not available";
VAL_ 2566535719 activeDischargeRequest_ePTO1_BAS 0 "no active discharge request" 1 "active discharge request" 2 "error" 3 "not available";
VAL_ 2351387943 MG2ICLimReqOCM_BASE 0 "Limits not currently being requested in this PG. The operating limits are not overridden" 1 "Torque Limits Mode" 2 "Speed Limits Mode" 3 "DC Side Voltage Limits Mode" 4 "DC Side Current Limits Mode" 5 "DC Side Power Limits Mode" 6 "Mechanical Power Limits Mode" 7 "SAE reserved 7" 8 "SAE reserved 8" 9 "SAE reserved 9" 10 "SAE reserved 10" 11 "SAE reserved 11" 12 "SAE reserved 12" 13 "SAE reserved 13" 14 "error" 15 "not available  - take no action";
VAL_ 2351387943 MG2ICsetpointModeReq_BASE 0 "Power On -the inverter is commanded to be powered on and able to communicate, but the Power Stage is disabled e.g. no switching or output" 1 "SAE Reserved 1" 2 "Standby - the inverter Power Stage is powered but commanded to a neutral operating mode i.e. no torque control, for example." 3 "SAE Reserved 3" 4 "SAE Reserved 4" 5 "Manufacturer specific passive mode 1" 6 "Manufacturer specific passive mode 2" 7 "Enable Torque Control Mode" 8 "Enable Speed Control Mode" 9 "Enable DC Side Voltage Mode" 10 "Enable DC Side Current Mode" 11 "Enable DC Power Control Mode" 12 "Enable Mechanical Power Control Mode" 13 "SAE Reserved" 14 "SAE Reserved" 15 "SAE Reserved" 16 "SAE Reserved" 17 "SAE Reserved" 18 "Manufacturer specific active mode 1" 19 "Manufacturer specific active mode 2" 20 "Inverter active discharge mode e.g. used to discharge capacitance within the inverter." 21 "Inverter power down command mode  - afterwards inverter will not respond to further commands." 22 "SAE Reserved 22" 23 "SAE Reserved 23" 24 "SAE Reserved 24" 25 "SAE Reserved 25" 26 "SAE Reserved 26" 27 "SAE Reserved 27" 28 "Manufacturer specific special mode 1" 29 "Manufacturer specific special mode 2" 30 "SAE Reserved 30" 31 "Not Available - Dont Care -Take No";
VAL_ 2600403758 trendDataCVMvariant_BASE 0 "CORE" 1 "TRUE" 14 "error" 15 "not available";
VAL_ 2600403758 trendDataCVMminorVersion_BASE 14 "error" 15 "not available";
VAL_ 2600403758 trendDataCVMmajorVersion_BASE 14 "error" 15 "not available";
VAL_ 2600454438 extrnlChrgStatus_BASE 0 "char. not active - not connected" 1 "char. not active - connected" 2 "immediate charging active" 3 "immediate charging finished" 4 "charging can not start/error" 5 "char. not active- veh. not ready" 6 "timer/profile charging active" 7 "timer/profile charging finished" 8 "timer/profile charging paused" 9 "station controlled charging active" 10 "station controlled  charging finished" 11 "station controlled  charging paused" 12 "char. communication setup" 13 "charging stopped by user" 14 "immediate charging conservation" 15 "timer/profile charging conservation" 16 "station controlled charging conservation" 62 "error" 63 "not available";
VAL_ 2600454438 extrnlChrgFlapStateChrgI1_BASE 0 "charging flap closed & unlocked" 1 "charging flap closed & locked" 2 "charging flap open" 14 "error" 15 "not available";
VAL_ 2600454438 actStateChrgPlug2Disp_BASE 0 "not plugged" 1 "plugged and unlocked" 2 "plugged and locked" 3 "not plausible" 4 "reserved 1" 5 "reserved 2" 6 "reserved 3" 7 "reserved 4" 8 "reserved 5" 9 "reserved 6" 10 "reserved 7" 11 "reserved 8" 12 "reserved 9" 13 "reserved 10" 14 "error" 15 "not available";
VAL_ 2600454438 actStateChrgPlugDisp_BASE 0 "not plugged" 1 "plugged and unlocked" 2 "plugged and locked" 3 "not plausible" 4 "reserve 1" 5 "reserve 2" 6 "reserve 3" 7 "reserve 4" 8 "reserve 5" 9 "reserve 6" 10 "reserve 7" 11 "reserve 8" 12 "reserve 9" 13 "reserve 10" 14 "error" 15 "not available";
VAL_ 2600454438 extrnlChrgErrorType_BASE 0 "no error" 1 "multiple interface connected" 2 "parking brake not applied" 3 "plug not locked" 4 "missing authentification" 5 "fault charging system, charging not active" 6 "fault charging system, charging aborted" 7 "fault charging infrastructure, charging not active" 8 "fault charging infrastructure, charging aborted" 9 "incompability charging infrastructure" 10 "hazardous fault charging system" 11 "charging suppressed" 12 "panto no physical connection" 13 "panto state unknown" 14 "panto initial start condition not met" 62 "error" 63 "not available";
VAL_ 2600454438 extrnlChrgHoldInfImmedDisp_BASE 0 "not selected" 1 "selected" 2 "error" 3 "not available";
VAL_ 2600454438 extrnlChrgModeDisp_BASE 0 "immediate charging" 1 "timer charging" 2 "station controlled (fallback immediate)" 3 "station controlled (fallback timer charging)" 14 "error" 15 "not available";
VAL_ 2600454438 energyManagmtMenuReq_BASE 0 "no request" 1 "last menu tab" 2 "charging menu tab" 3 "HVAC menu tab" 4 "bodybuilder menu tab" 14 "error" 15 "not available";
VAL_ 2600454438 extrnlChrgOTActrlDisp_BASE 0 "OTA control disabled" 1 "OTA control enabled" 2 "error" 3 "not available";
VAL_ 2600454438 extrnlChrgFlapStateChrgI2_BASE 0 "charging flap closed & unlocked" 1 "charging flap closed & locked" 2 "charging flap open" 14 "error" 15 "not available";
